VERSION ""

NS_ :

BS_:

BU_: FBD_HL IPB_App1 FBD_HM FBD_HR FBD_Miko FBD_MM FBD_Trunk FBD_VL FBD_VM FBD_VR Diagnosetool_CAN_FD_IPB_41

BO_ 552 LocalizationInitFBD_Miko: 48 FBD_Miko
 SG_ LocalizationInitFBD_Miko_IRKList : 0|8@1+ (1.0,0) [0|252] "" IPB_App1
 SG_ LocalizationInitFBD_Miko_ZoneEnt : 8|8@1+ (1.0,0) [0|252] "" IPB_App1
 SG_ LocalizationInitFBD_Miko_Ranging : 16|16@1+ (1.0,0) [0|65532] "" IPB_App1
 SG_ LocalizationInitFBD_Miko_TimeOfF : 32|16@1+ (15.65,0) [0|1000000] "ps" IPB_App1
 SG_ LocalizationInitFBD_Miko_RSSI_0 : 48|8@1+ (1.0,-90) [-90|90] "°" IPB_App1
 SG_ LocalizationInitFBD_Miko_Rangi_2 : 56|16@1+ (1.0,0) [0|65532] "" IPB_App1
 SG_ LocalizationInitFBD_Miko_TimeO_2 : 72|16@1+ (15.65,0) [0|1000000] "ps" IPB_App1
 SG_ LocalizationInitFBD_Miko_RSSI_1 : 88|8@1+ (1.0,-90) [-90|90] "°" IPB_App1
 SG_ LocalizationInitFBD_Miko_Rangi_3 : 96|16@1+ (1.0,0) [0|65532] "" IPB_App1
 SG_ LocalizationInitFBD_Miko_TimeO_3 : 112|16@1+ (15.65,0) [0|1000000] "ps" IPB_App1
 SG_ LocalizationInitFBD_Miko_RSSI_2 : 128|8@1+ (1.0,-90) [-90|90] "°" IPB_App1
 SG_ LocalizationInitFBD_Miko_Rangi_4 : 136|16@1+ (1.0,0) [0|65532] "" IPB_App1
 SG_ LocalizationInitFBD_Miko_TimeO_4 : 152|16@1+ (15.65,0) [0|1000000] "ps" IPB_App1
 SG_ LocalizationInitFBD_Miko_RSSI_3 : 168|8@1+ (1.0,-90) [-90|90] "°" IPB_App1
 SG_ LocalizationInitFBD_Miko_Rangi_5 : 176|16@1+ (1.0,0) [0|65532] "" IPB_App1
 SG_ LocalizationInitFBD_Miko_TimeO_5 : 192|16@1+ (15.65,0) [0|1000000] "ps" IPB_App1
 SG_ LocalizationInitFBD_Miko_RSSI_4 : 208|8@1+ (1.0,-90) [-90|90] "°" IPB_App1
 SG_ LocalizationInitFBD_Miko_Sign_00 : 216|8@1+ (1.0,0) [0|255] "" IPB_App1
 SG_ LocalizationInitFBD_Miko_Sign_01 : 224|8@1+ (1.0,0) [0|255] "" IPB_App1
 SG_ LocalizationInitFBD_Miko_Sign_02 : 232|8@1+ (1.0,0) [0|255] "" IPB_App1
 SG_ LocalizationInitFBD_Miko_Sign_03 : 240|8@1+ (1.0,0) [0|255] "" IPB_App1
 SG_ LocalizationInitFBD_Miko_Sign_04 : 248|8@1+ (1.0,0) [0|255] "" IPB_App1
 SG_ LocalizationInitFBD_Miko_Sign_05 : 256|8@1+ (1.0,0) [0|255] "" IPB_App1
 SG_ LocalizationInitFBD_Miko_Sign_06 : 264|8@1+ (1.0,0) [0|255] "" IPB_App1
 SG_ LocalizationInitFBD_Miko_Sign_07 : 272|8@1+ (1.0,0) [0|255] "" IPB_App1
 SG_ LocalizationInitFBD_Miko_Sign_08 : 280|8@1+ (1.0,0) [0|255] "" IPB_App1
 SG_ LocalizationInitFBD_Miko_Sign_09 : 288|8@1+ (1.0,0) [0|255] "" IPB_App1
 SG_ LocalizationInitFBD_Miko_Sign_10 : 296|8@1+ (1.0,0) [0|255] "" IPB_App1
 SG_ LocalizationInitFBD_Miko_Sign_11 : 304|8@1+ (1.0,0) [0|255] "" IPB_App1
 SG_ LocalizationInitFBD_Miko_Sign_12 : 312|8@1+ (1.0,0) [0|255] "" IPB_App1
 SG_ LocalizationInitFBD_Miko_Sign_13 : 320|8@1+ (1.0,0) [0|255] "" IPB_App1
 SG_ LocalizationInitFBD_Miko_Sign_14 : 328|8@1+ (1.0,0) [0|255] "" IPB_App1
 SG_ LocalizationInitFBD_Miko_Sign_15 : 336|8@1+ (1.0,0) [0|255] "" IPB_App1
 SG_ LocalizationInitFBD_Miko_Rangi_6 : 344|8@1+ (1.0,0) [0|255] "" IPB_App1
 SG_ LocalizationInitFBD_Miko_Rangi_7 : 352|8@1+ (1.0,0) [0|255] "" IPB_App1
 SG_ LocalizationInitFBD_Miko_Rangi_8 : 360|8@1+ (1.0,0) [0|255] "" IPB_App1
 SG_ LocalizationInitFBD_Miko_Rangi_9 : 368|8@1+ (1.0,0) [0|255] "" IPB_App1
 SG_ LocalizationInitFBD_Miko_Rang_10 : 376|8@1+ (1.0,0) [0|255] "" IPB_App1

BO_ 560 LocalizationInitFBD_MM: 48 FBD_MM
 SG_ LocalizationInitFBD_MM_IRKListIn : 0|8@1+ (1.0,0) [0|252] "" IPB_App1
 SG_ LocalizationInitFBD_MM_ZoneEntry : 8|8@1+ (1.0,0) [0|252] "" IPB_App1
 SG_ LocalizationInitFBD_MM_RangingBl : 16|16@1+ (1.0,0) [0|65532] "" IPB_App1
 SG_ LocalizationInitFBD_MM_TimeOfFli : 32|16@1+ (15.65,0) [0|1000000] "ps" IPB_App1
 SG_ LocalizationInitFBD_MM_RSSI_0 : 48|8@1+ (1.0,-90) [-90|90] "°" IPB_App1
 SG_ LocalizationInitFBD_MM_Ranging_2 : 56|16@1+ (1.0,0) [0|65532] "" IPB_App1
 SG_ LocalizationInitFBD_MM_TimeOfF_2 : 72|16@1+ (15.65,0) [0|1000000] "ps" IPB_App1
 SG_ LocalizationInitFBD_MM_RSSI_1 : 88|8@1+ (1.0,-90) [-90|90] "°" IPB_App1
 SG_ LocalizationInitFBD_MM_Ranging_3 : 96|16@1+ (1.0,0) [0|65532] "" IPB_App1
 SG_ LocalizationInitFBD_MM_TimeOfF_3 : 112|16@1+ (15.65,0) [0|1000000] "ps" IPB_App1
 SG_ LocalizationInitFBD_MM_RSSI_2 : 128|8@1+ (1.0,-90) [-90|90] "°" IPB_App1
 SG_ LocalizationInitFBD_MM_Ranging_4 : 136|16@1+ (1.0,0) [0|65532] "" IPB_App1
 SG_ LocalizationInitFBD_MM_TimeOfF_4 : 152|16@1+ (15.65,0) [0|1000000] "ps" IPB_App1
 SG_ LocalizationInitFBD_MM_RSSI_3 : 168|8@1+ (1.0,-90) [-90|90] "°" IPB_App1
 SG_ LocalizationInitFBD_MM_Ranging_5 : 176|16@1+ (1.0,0) [0|65532] "" IPB_App1
 SG_ LocalizationInitFBD_MM_TimeOfF_5 : 192|16@1+ (15.65,0) [0|1000000] "ps" IPB_App1
 SG_ LocalizationInitFBD_MM_RSSI_4 : 208|8@1+ (1.0,-90) [-90|90] "°" IPB_App1
 SG_ LocalizationInitFBD_MM_Sign_00 : 216|8@1+ (1.0,0) [0|255] "" IPB_App1
 SG_ LocalizationInitFBD_MM_Sign_01 : 224|8@1+ (1.0,0) [0|255] "" IPB_App1
 SG_ LocalizationInitFBD_MM_Sign_02 : 232|8@1+ (1.0,0) [0|255] "" IPB_App1
 SG_ LocalizationInitFBD_MM_Sign_03 : 240|8@1+ (1.0,0) [0|255] "" IPB_App1
 SG_ LocalizationInitFBD_MM_Sign_04 : 248|8@1+ (1.0,0) [0|255] "" IPB_App1
 SG_ LocalizationInitFBD_MM_Sign_05 : 256|8@1+ (1.0,0) [0|255] "" IPB_App1
 SG_ LocalizationInitFBD_MM_Sign_06 : 264|8@1+ (1.0,0) [0|255] "" IPB_App1
 SG_ LocalizationInitFBD_MM_Sign_07 : 272|8@1+ (1.0,0) [0|255] "" IPB_App1
 SG_ LocalizationInitFBD_MM_Sign_08 : 280|8@1+ (1.0,0) [0|255] "" IPB_App1
 SG_ LocalizationInitFBD_MM_Sign_09 : 288|8@1+ (1.0,0) [0|255] "" IPB_App1
 SG_ LocalizationInitFBD_MM_Sign_10 : 296|8@1+ (1.0,0) [0|255] "" IPB_App1
 SG_ LocalizationInitFBD_MM_Sign_11 : 304|8@1+ (1.0,0) [0|255] "" IPB_App1
 SG_ LocalizationInitFBD_MM_Sign_12 : 312|8@1+ (1.0,0) [0|255] "" IPB_App1
 SG_ LocalizationInitFBD_MM_Sign_13 : 320|8@1+ (1.0,0) [0|255] "" IPB_App1
 SG_ LocalizationInitFBD_MM_Sign_14 : 328|8@1+ (1.0,0) [0|255] "" IPB_App1
 SG_ LocalizationInitFBD_MM_Sign_15 : 336|8@1+ (1.0,0) [0|255] "" IPB_App1
 SG_ LocalizationInitFBD_MM_RangingRo : 344|8@1+ (1.0,0) [0|255] "" IPB_App1
 SG_ LocalizationInitFBD_MM_Ranging_6 : 352|8@1+ (1.0,0) [0|255] "" IPB_App1
 SG_ LocalizationInitFBD_MM_Ranging_7 : 360|8@1+ (1.0,0) [0|255] "" IPB_App1
 SG_ LocalizationInitFBD_MM_Ranging_8 : 368|8@1+ (1.0,0) [0|255] "" IPB_App1
 SG_ LocalizationInitFBD_MM_Ranging_9 : 376|8@1+ (1.0,0) [0|255] "" IPB_App1

BO_ 553 LocalizationInitFBD_Trunk: 48 FBD_Trunk
 SG_ LocalizationInitFBD_Trunk_IRKLis : 0|8@1+ (1.0,0) [0|252] "" IPB_App1
 SG_ LocalizationInitFBD_Trunk_ZoneEn : 8|8@1+ (1.0,0) [0|252] "" IPB_App1
 SG_ LocalizationInitFBD_Trunk_Rangin : 16|16@1+ (1.0,0) [0|65532] "" IPB_App1
 SG_ LocalizationInitFBD_Trunk_TimeOf : 32|16@1+ (15.65,0) [0|1000000] "ps" IPB_App1
 SG_ LocalizationInitFBD_Trunk_RSSI_0 : 48|8@1+ (1.0,-90) [-90|90] "°" IPB_App1
 SG_ LocalizationInitFBD_Trunk_Rang_2 : 56|16@1+ (1.0,0) [0|65532] "" IPB_App1
 SG_ LocalizationInitFBD_Trunk_Time_2 : 72|16@1+ (15.65,0) [0|1000000] "ps" IPB_App1
 SG_ LocalizationInitFBD_Trunk_RSSI_1 : 88|8@1+ (1.0,-90) [-90|90] "°" IPB_App1
 SG_ LocalizationInitFBD_Trunk_Rang_3 : 96|16@1+ (1.0,0) [0|65532] "" IPB_App1
 SG_ LocalizationInitFBD_Trunk_Time_3 : 112|16@1+ (15.65,0) [0|1000000] "ps" IPB_App1
 SG_ LocalizationInitFBD_Trunk_RSSI_2 : 128|8@1+ (1.0,-90) [-90|90] "°" IPB_App1
 SG_ LocalizationInitFBD_Trunk_Rang_4 : 136|16@1+ (1.0,0) [0|65532] "" IPB_App1
 SG_ LocalizationInitFBD_Trunk_Time_4 : 152|16@1+ (15.65,0) [0|1000000] "ps" IPB_App1
 SG_ LocalizationInitFBD_Trunk_RSSI_3 : 168|8@1+ (1.0,-90) [-90|90] "°" IPB_App1
 SG_ LocalizationInitFBD_Trunk_Rang_5 : 176|16@1+ (1.0,0) [0|65532] "" IPB_App1
 SG_ LocalizationInitFBD_Trunk_Time_5 : 192|16@1+ (15.65,0) [0|1000000] "ps" IPB_App1
 SG_ LocalizationInitFBD_Trunk_RSSI_4 : 208|8@1+ (1.0,-90) [-90|90] "°" IPB_App1
 SG_ LocalizationInitFBD_Trunk_Sign_0 : 216|8@1+ (1.0,0) [0|255] "" IPB_App1
 SG_ LocalizationInitFBD_Trunk_Sign_2 : 224|8@1+ (1.0,0) [0|255] "" IPB_App1
 SG_ LocalizationInitFBD_Trunk_Sign_3 : 232|8@1+ (1.0,0) [0|255] "" IPB_App1
 SG_ LocalizationInitFBD_Trunk_Sign_4 : 240|8@1+ (1.0,0) [0|255] "" IPB_App1
 SG_ LocalizationInitFBD_Trunk_Sign_5 : 248|8@1+ (1.0,0) [0|255] "" IPB_App1
 SG_ LocalizationInitFBD_Trunk_Sign_6 : 256|8@1+ (1.0,0) [0|255] "" IPB_App1
 SG_ LocalizationInitFBD_Trunk_Sign_7 : 264|8@1+ (1.0,0) [0|255] "" IPB_App1
 SG_ LocalizationInitFBD_Trunk_Sign_8 : 272|8@1+ (1.0,0) [0|255] "" IPB_App1
 SG_ LocalizationInitFBD_Trunk_Sign_9 : 280|8@1+ (1.0,0) [0|255] "" IPB_App1
 SG_ LocalizationInitFBD_Trunk_Sig_10 : 288|8@1+ (1.0,0) [0|255] "" IPB_App1
 SG_ LocalizationInitFBD_Trunk_Sign_1 : 296|8@1+ (1.0,0) [0|255] "" IPB_App1
 SG_ LocalizationInitFBD_Trunk_Sig_11 : 304|8@1+ (1.0,0) [0|255] "" IPB_App1
 SG_ LocalizationInitFBD_Trunk_Sig_12 : 312|8@1+ (1.0,0) [0|255] "" IPB_App1
 SG_ LocalizationInitFBD_Trunk_Sig_13 : 320|8@1+ (1.0,0) [0|255] "" IPB_App1
 SG_ LocalizationInitFBD_Trunk_Sig_14 : 328|8@1+ (1.0,0) [0|255] "" IPB_App1
 SG_ LocalizationInitFBD_Trunk_Sig_15 : 336|8@1+ (1.0,0) [0|255] "" IPB_App1
 SG_ LocalizationInitFBD_Trunk_Rang_6 : 344|8@1+ (1.0,0) [0|255] "" IPB_App1
 SG_ LocalizationInitFBD_Trunk_Rang_7 : 352|8@1+ (1.0,0) [0|255] "" IPB_App1
 SG_ LocalizationInitFBD_Trunk_Rang_8 : 360|8@1+ (1.0,0) [0|255] "" IPB_App1
 SG_ LocalizationInitFBD_Trunk_Rang_9 : 368|8@1+ (1.0,0) [0|255] "" IPB_App1
 SG_ LocalizationInitFBD_Trunk_Ran_10 : 376|8@1+ (1.0,0) [0|255] "" IPB_App1

BO_ 554 LocalizationInitFBD_VL: 48 FBD_VL
 SG_ LocalizationInitFBD_VL_IRKListIn : 0|8@1+ (1.0,0) [0|252] "" IPB_App1
 SG_ LocalizationInitFBD_VL_ZoneEntry : 8|8@1+ (1.0,0) [0|252] "" IPB_App1
 SG_ LocalizationInitFBD_VL_RangingBl : 16|16@1+ (1.0,0) [0|65532] "" IPB_App1
 SG_ LocalizationInitFBD_VL_TimeOfFli : 32|16@1+ (15.65,0) [0|1000000] "ps" IPB_App1
 SG_ LocalizationInitFBD_VL_RSSI_0 : 48|8@1+ (1.0,-90) [-90|90] "°" IPB_App1
 SG_ LocalizationInitFBD_VL_Ranging_2 : 56|16@1+ (1.0,0) [0|65532] "" IPB_App1
 SG_ LocalizationInitFBD_VL_TimeOfF_2 : 72|16@1+ (15.65,0) [0|1000000] "ps" IPB_App1
 SG_ LocalizationInitFBD_VL_RSSI_1 : 88|8@1+ (1.0,-90) [-90|90] "°" IPB_App1
 SG_ LocalizationInitFBD_VL_Ranging_3 : 96|16@1+ (1.0,0) [0|65532] "" IPB_App1
 SG_ LocalizationInitFBD_VL_TimeOfF_3 : 112|16@1+ (15.65,0) [0|1000000] "ps" IPB_App1
 SG_ LocalizationInitFBD_VL_RSSI_2 : 128|8@1+ (1.0,-90) [-90|90] "°" IPB_App1
 SG_ LocalizationInitFBD_VL_Ranging_4 : 136|16@1+ (1.0,0) [0|65532] "" IPB_App1
 SG_ LocalizationInitFBD_VL_TimeOfF_4 : 152|16@1+ (15.65,0) [0|1000000] "ps" IPB_App1
 SG_ LocalizationInitFBD_VL_RSSI_3 : 168|8@1+ (1.0,-90) [-90|90] "°" IPB_App1
 SG_ LocalizationInitFBD_VL_Ranging_5 : 176|16@1+ (1.0,0) [0|65532] "" IPB_App1
 SG_ LocalizationInitFBD_VL_TimeOfF_5 : 192|16@1+ (15.65,0) [0|1000000] "ps" IPB_App1
 SG_ LocalizationInitFBD_VL_RSSI_4 : 208|8@1+ (1.0,-90) [-90|90] "°" IPB_App1
 SG_ LocalizationInitFBD_VL_Sign_00 : 216|8@1+ (1.0,0) [0|255] "" IPB_App1
 SG_ LocalizationInitFBD_VL_Sign_01 : 224|8@1+ (1.0,0) [0|255] "" IPB_App1
 SG_ LocalizationInitFBD_VL_Sign_02 : 232|8@1+ (1.0,0) [0|255] "" IPB_App1
 SG_ LocalizationInitFBD_VL_Sign_03 : 240|8@1+ (1.0,0) [0|255] "" IPB_App1
 SG_ LocalizationInitFBD_VL_Sign_04 : 248|8@1+ (1.0,0) [0|255] "" IPB_App1
 SG_ LocalizationInitFBD_VL_Sign_05 : 256|8@1+ (1.0,0) [0|255] "" IPB_App1
 SG_ LocalizationInitFBD_VL_Sign_06 : 264|8@1+ (1.0,0) [0|255] "" IPB_App1
 SG_ LocalizationInitFBD_VL_Sign_07 : 272|8@1+ (1.0,0) [0|255] "" IPB_App1
 SG_ LocalizationInitFBD_VL_Sign_08 : 280|8@1+ (1.0,0) [0|255] "" IPB_App1
 SG_ LocalizationInitFBD_VL_Sign_09 : 288|8@1+ (1.0,0) [0|255] "" IPB_App1
 SG_ LocalizationInitFBD_VL_Sign_10 : 296|8@1+ (1.0,0) [0|255] "" IPB_App1
 SG_ LocalizationInitFBD_VL_Sign_11 : 304|8@1+ (1.0,0) [0|255] "" IPB_App1
 SG_ LocalizationInitFBD_VL_Sign_12 : 312|8@1+ (1.0,0) [0|255] "" IPB_App1
 SG_ LocalizationInitFBD_VL_Sign_13 : 320|8@1+ (1.0,0) [0|255] "" IPB_App1
 SG_ LocalizationInitFBD_VL_Sign_14 : 328|8@1+ (1.0,0) [0|255] "" IPB_App1
 SG_ LocalizationInitFBD_VL_Sign_15 : 336|8@1+ (1.0,0) [0|255] "" IPB_App1
 SG_ LocalizationInitFBD_VL_RangingRo : 344|8@1+ (1.0,0) [0|255] "" IPB_App1
 SG_ LocalizationInitFBD_VL_Ranging_6 : 352|8@1+ (1.0,0) [0|255] "" IPB_App1
 SG_ LocalizationInitFBD_VL_Ranging_7 : 360|8@1+ (1.0,0) [0|255] "" IPB_App1
 SG_ LocalizationInitFBD_VL_Ranging_8 : 368|8@1+ (1.0,0) [0|255] "" IPB_App1
 SG_ LocalizationInitFBD_VL_Ranging_9 : 376|8@1+ (1.0,0) [0|255] "" IPB_App1

BO_ 550 LocalizationInitFBD_VM: 48 FBD_VM
 SG_ LocalizationInitFBD_VM_IRKListIn : 0|8@1+ (1.0,0) [0|252] "" IPB_App1
 SG_ LocalizationInitFBD_VM_ZoneEntry : 8|8@1+ (1.0,0) [0|252] "" IPB_App1
 SG_ LocalizationInitFBD_VM_RangingBl : 16|16@1+ (1.0,0) [0|65532] "" IPB_App1
 SG_ LocalizationInitFBD_VM_TimeOfFli : 32|16@1+ (15.65,0) [0|1000000] "ps" IPB_App1
 SG_ LocalizationInitFBD_VM_RSSI_0 : 48|8@1+ (1.0,-90) [-90|90] "°" IPB_App1
 SG_ LocalizationInitFBD_VM_Ranging_2 : 56|16@1+ (1.0,0) [0|65532] "" IPB_App1
 SG_ LocalizationInitFBD_VM_TimeOfF_2 : 72|16@1+ (15.65,0) [0|1000000] "ps" IPB_App1
 SG_ LocalizationInitFBD_VM_RSSI_1 : 88|8@1+ (1.0,-90) [-90|90] "°" IPB_App1
 SG_ LocalizationInitFBD_VM_Ranging_3 : 96|16@1+ (1.0,0) [0|65532] "" IPB_App1
 SG_ LocalizationInitFBD_VM_TimeOfF_3 : 112|16@1+ (15.65,0) [0|1000000] "ps" IPB_App1
 SG_ LocalizationInitFBD_VM_RSSI_2 : 128|8@1+ (1.0,-90) [-90|90] "°" IPB_App1
 SG_ LocalizationInitFBD_VM_Ranging_4 : 136|16@1+ (1.0,0) [0|65532] "" IPB_App1
 SG_ LocalizationInitFBD_VM_TimeOfF_4 : 152|16@1+ (15.65,0) [0|1000000] "ps" IPB_App1
 SG_ LocalizationInitFBD_VM_RSSI_3 : 168|8@1+ (1.0,-90) [-90|90] "°" IPB_App1
 SG_ LocalizationInitFBD_VM_Ranging_5 : 176|16@1+ (1.0,0) [0|65532] "" IPB_App1
 SG_ LocalizationInitFBD_VM_TimeOfF_5 : 192|16@1+ (15.65,0) [0|1000000] "ps" IPB_App1
 SG_ LocalizationInitFBD_VM_RSSI_4 : 208|8@1+ (1.0,-90) [-90|90] "°" IPB_App1
 SG_ LocalizationInitFBD_VM_Sign_00 : 216|8@1+ (1.0,0) [0|255] "" IPB_App1
 SG_ LocalizationInitFBD_VM_Sign_01 : 224|8@1+ (1.0,0) [0|255] "" IPB_App1
 SG_ LocalizationInitFBD_VM_Sign_02 : 232|8@1+ (1.0,0) [0|255] "" IPB_App1
 SG_ LocalizationInitFBD_VM_Sign_03 : 240|8@1+ (1.0,0) [0|255] "" IPB_App1
 SG_ LocalizationInitFBD_VM_Sign_04 : 248|8@1+ (1.0,0) [0|255] "" IPB_App1
 SG_ LocalizationInitFBD_VM_Sign_05 : 256|8@1+ (1.0,0) [0|255] "" IPB_App1
 SG_ LocalizationInitFBD_VM_Sign_06 : 264|8@1+ (1.0,0) [0|255] "" IPB_App1
 SG_ LocalizationInitFBD_VM_Sign_07 : 272|8@1+ (1.0,0) [0|255] "" IPB_App1
 SG_ LocalizationInitFBD_VM_Sign_08 : 280|8@1+ (1.0,0) [0|255] "" IPB_App1
 SG_ LocalizationInitFBD_VM_Sign_09 : 288|8@1+ (1.0,0) [0|255] "" IPB_App1
 SG_ LocalizationInitFBD_VM_Sign_10 : 296|8@1+ (1.0,0) [0|255] "" IPB_App1
 SG_ LocalizationInitFBD_VM_Sign_11 : 304|8@1+ (1.0,0) [0|255] "" IPB_App1
 SG_ LocalizationInitFBD_VM_Sign_12 : 312|8@1+ (1.0,0) [0|255] "" IPB_App1
 SG_ LocalizationInitFBD_VM_Sign_13 : 320|8@1+ (1.0,0) [0|255] "" IPB_App1
 SG_ LocalizationInitFBD_VM_Sign_14 : 328|8@1+ (1.0,0) [0|255] "" IPB_App1
 SG_ LocalizationInitFBD_VM_Sign_15 : 336|8@1+ (1.0,0) [0|255] "" IPB_App1
 SG_ LocalizationInitFBD_VM_RangingRo : 344|8@1+ (1.0,0) [0|255] "" IPB_App1
 SG_ LocalizationInitFBD_VM_Ranging_6 : 352|8@1+ (1.0,0) [0|255] "" IPB_App1
 SG_ LocalizationInitFBD_VM_Ranging_7 : 360|8@1+ (1.0,0) [0|255] "" IPB_App1
 SG_ LocalizationInitFBD_VM_Ranging_8 : 368|8@1+ (1.0,0) [0|255] "" IPB_App1
 SG_ LocalizationInitFBD_VM_Ranging_9 : 376|8@1+ (1.0,0) [0|255] "" IPB_App1

BO_ 555 LocalizationInitFBD_VR: 48 FBD_VR
 SG_ LocalizationInitFBD_VR_IRKListIn : 0|8@1+ (1.0,0) [0|252] "" IPB_App1
 SG_ LocalizationInitFBD_VR_ZoneEntry : 8|8@1+ (1.0,0) [0|252] "" IPB_App1
 SG_ LocalizationInitFBD_VR_RangingBl : 16|16@1+ (1.0,0) [0|65532] "" IPB_App1
 SG_ LocalizationInitFBD_VR_TimeOfFli : 32|16@1+ (15.65,0) [0|1000000] "ps" IPB_App1
 SG_ LocalizationInitFBD_VR_RSSI_0 : 48|8@1+ (1.0,-90) [-90|90] "°" IPB_App1
 SG_ LocalizationInitFBD_VR_Ranging_2 : 56|16@1+ (1.0,0) [0|65532] "" IPB_App1
 SG_ LocalizationInitFBD_VR_TimeOfF_2 : 72|16@1+ (15.65,0) [0|1000000] "ps" IPB_App1
 SG_ LocalizationInitFBD_VR_RSSI_1 : 88|8@1+ (1.0,-90) [-90|90] "°" IPB_App1
 SG_ LocalizationInitFBD_VR_Ranging_3 : 96|16@1+ (1.0,0) [0|65532] "" IPB_App1
 SG_ LocalizationInitFBD_VR_TimeOfF_3 : 112|16@1+ (15.65,0) [0|1000000] "ps" IPB_App1
 SG_ LocalizationInitFBD_VR_RSSI_2 : 128|8@1+ (1.0,-90) [-90|90] "°" IPB_App1
 SG_ LocalizationInitFBD_VR_Ranging_4 : 136|16@1+ (1.0,0) [0|65532] "" IPB_App1
 SG_ LocalizationInitFBD_VR_TimeOfF_4 : 152|16@1+ (15.65,0) [0|1000000] "ps" IPB_App1
 SG_ LocalizationInitFBD_VR_RSSI_3 : 168|8@1+ (1.0,-90) [-90|90] "°" IPB_App1
 SG_ LocalizationInitFBD_VR_Ranging_5 : 176|16@1+ (1.0,0) [0|65532] "" IPB_App1
 SG_ LocalizationInitFBD_VR_TimeOfF_5 : 192|16@1+ (15.65,0) [0|1000000] "ps" IPB_App1
 SG_ LocalizationInitFBD_VR_RSSI_4 : 208|8@1+ (1.0,-90) [-90|90] "°" IPB_App1
 SG_ LocalizationInitFBD_VR_Sign_00 : 216|8@1+ (1.0,0) [0|255] "" IPB_App1
 SG_ LocalizationInitFBD_VR_Sign_01 : 224|8@1+ (1.0,0) [0|255] "" IPB_App1
 SG_ LocalizationInitFBD_VR_Sign_02 : 232|8@1+ (1.0,0) [0|255] "" IPB_App1
 SG_ LocalizationInitFBD_VR_Sign_03 : 240|8@1+ (1.0,0) [0|255] "" IPB_App1
 SG_ LocalizationInitFBD_VR_Sign_04 : 248|8@1+ (1.0,0) [0|255] "" IPB_App1
 SG_ LocalizationInitFBD_VR_Sign_05 : 256|8@1+ (1.0,0) [0|255] "" IPB_App1
 SG_ LocalizationInitFBD_VR_Sign_06 : 264|8@1+ (1.0,0) [0|255] "" IPB_App1
 SG_ LocalizationInitFBD_VR_Sign_07 : 272|8@1+ (1.0,0) [0|255] "" IPB_App1
 SG_ LocalizationInitFBD_VR_Sign_08 : 280|8@1+ (1.0,0) [0|255] "" IPB_App1
 SG_ LocalizationInitFBD_VR_Sign_09 : 288|8@1+ (1.0,0) [0|255] "" IPB_App1
 SG_ LocalizationInitFBD_VR_Sign_10 : 296|8@1+ (1.0,0) [0|255] "" IPB_App1
 SG_ LocalizationInitFBD_VR_Sign_11 : 304|8@1+ (1.0,0) [0|255] "" IPB_App1
 SG_ LocalizationInitFBD_VR_Sign_12 : 312|8@1+ (1.0,0) [0|255] "" IPB_App1
 SG_ LocalizationInitFBD_VR_Sign_13 : 320|8@1+ (1.0,0) [0|255] "" IPB_App1
 SG_ LocalizationInitFBD_VR_Sign_14 : 328|8@1+ (1.0,0) [0|255] "" IPB_App1
 SG_ LocalizationInitFBD_VR_Sign_15 : 336|8@1+ (1.0,0) [0|255] "" IPB_App1
 SG_ LocalizationInitFBD_VR_RangingRo : 344|8@1+ (1.0,0) [0|255] "" IPB_App1
 SG_ LocalizationInitFBD_VR_Ranging_6 : 352|8@1+ (1.0,0) [0|255] "" IPB_App1
 SG_ LocalizationInitFBD_VR_Ranging_7 : 360|8@1+ (1.0,0) [0|255] "" IPB_App1
 SG_ LocalizationInitFBD_VR_Ranging_8 : 368|8@1+ (1.0,0) [0|255] "" IPB_App1
 SG_ LocalizationInitFBD_VR_Ranging_9 : 376|8@1+ (1.0,0) [0|255] "" IPB_App1

BO_ 406 LocalizationInitRequest: 20 IPB_App1
 SG_ LocalizationInitRequest_Address : 0|16@1+ (1,0) [0|0] "" FBD_HL,FBD_HM,FBD_HR,FBD_MM,FBD_Miko,FBD_Trunk,FBD_VL,FBD_VM,FBD_VR
 SG_ LocalizationInitRequest_SessionI : 16|8@1+ (1.0,0) [0|252] "" FBD_HL,FBD_HM,FBD_HR,FBD_MM,FBD_Miko,FBD_Trunk,FBD_VL,FBD_VM,FBD_VR
 SG_ LocalizationInitRequest_IRKListI : 24|8@1+ (1.0,0) [0|252] "" FBD_HL,FBD_HM,FBD_HR,FBD_MM,FBD_Miko,FBD_Trunk,FBD_VL,FBD_VM,FBD_VR
 SG_ LocalizationInitRequest_Auth00 : 32|8@1+ (1.0,0) [0|255] "" FBD_HL,FBD_HM,FBD_HR,FBD_MM,FBD_Miko,FBD_Trunk,FBD_VL,FBD_VM,FBD_VR
 SG_ LocalizationInitRequest_Auth01 : 40|8@1+ (1.0,0) [0|255] "" FBD_HL,FBD_HM,FBD_HR,FBD_MM,FBD_Miko,FBD_Trunk,FBD_VL,FBD_VM,FBD_VR
 SG_ LocalizationInitRequest_Auth02 : 48|8@1+ (1.0,0) [0|255] "" FBD_HL,FBD_HM,FBD_HR,FBD_MM,FBD_Miko,FBD_Trunk,FBD_VL,FBD_VM,FBD_VR
 SG_ LocalizationInitRequest_Auth03 : 56|8@1+ (1.0,0) [0|255] "" FBD_HL,FBD_HM,FBD_HR,FBD_MM,FBD_Miko,FBD_Trunk,FBD_VL,FBD_VM,FBD_VR
 SG_ LocalizationInitRequest_Auth04 : 64|8@1+ (1.0,0) [0|255] "" FBD_HL,FBD_HM,FBD_HR,FBD_MM,FBD_Miko,FBD_Trunk,FBD_VL,FBD_VM,FBD_VR
 SG_ LocalizationInitRequest_Auth05 : 72|8@1+ (1.0,0) [0|255] "" FBD_HL,FBD_HM,FBD_HR,FBD_MM,FBD_Miko,FBD_Trunk,FBD_VL,FBD_VM,FBD_VR
 SG_ LocalizationInitRequest_Auth06 : 80|8@1+ (1.0,0) [0|255] "" FBD_HL,FBD_HM,FBD_HR,FBD_MM,FBD_Miko,FBD_Trunk,FBD_VL,FBD_VM,FBD_VR
 SG_ LocalizationInitRequest_Auth07 : 88|8@1+ (1.0,0) [0|255] "" FBD_HL,FBD_HM,FBD_HR,FBD_MM,FBD_Miko,FBD_Trunk,FBD_VL,FBD_VM,FBD_VR
 SG_ LocalizationInitRequest_Auth08 : 96|8@1+ (1.0,0) [0|255] "" FBD_HL,FBD_HM,FBD_HR,FBD_MM,FBD_Miko,FBD_Trunk,FBD_VL,FBD_VM,FBD_VR
 SG_ LocalizationInitRequest_Auth09 : 104|8@1+ (1.0,0) [0|255] "" FBD_HL,FBD_HM,FBD_HR,FBD_MM,FBD_Miko,FBD_Trunk,FBD_VL,FBD_VM,FBD_VR
 SG_ LocalizationInitRequest_Auth10 : 112|8@1+ (1.0,0) [0|255] "" FBD_HL,FBD_HM,FBD_HR,FBD_MM,FBD_Miko,FBD_Trunk,FBD_VL,FBD_VM,FBD_VR
 SG_ LocalizationInitRequest_Auth11 : 120|8@1+ (1.0,0) [0|255] "" FBD_HL,FBD_HM,FBD_HR,FBD_MM,FBD_Miko,FBD_Trunk,FBD_VL,FBD_VM,FBD_VR
 SG_ LocalizationInitRequest_Auth12 : 128|8@1+ (1.0,0) [0|255] "" FBD_HL,FBD_HM,FBD_HR,FBD_MM,FBD_Miko,FBD_Trunk,FBD_VL,FBD_VM,FBD_VR
 SG_ LocalizationInitRequest_Auth13 : 136|8@1+ (1.0,0) [0|255] "" FBD_HL,FBD_HM,FBD_HR,FBD_MM,FBD_Miko,FBD_Trunk,FBD_VL,FBD_VM,FBD_VR
 SG_ LocalizationInitRequest_Auth14 : 144|8@1+ (1.0,0) [0|255] "" FBD_HL,FBD_HM,FBD_HR,FBD_MM,FBD_Miko,FBD_Trunk,FBD_VL,FBD_VM,FBD_VR
 SG_ LocalizationInitRequest_Auth15 : 152|8@1+ (1.0,0) [0|255] "" FBD_HL,FBD_HM,FBD_HR,FBD_MM,FBD_Miko,FBD_Trunk,FBD_VL,FBD_VM,FBD_VR

BO_ 999 LocalizationResult_IPB: 32 IPB_App1
 SG_ LocalizationResult_IPB_Byte00 : 0|8@1+ (1.0,0) [0|252] "" Diagnosetool_CAN_FD_IPB_41
 SG_ LocalizationResult_IPB_Byte01 : 8|8@1+ (1.0,0) [0|252] "" Diagnosetool_CAN_FD_IPB_41
 SG_ LocalizationResult_IPB_Byte02 : 16|8@1+ (1.0,0) [0|252] "" Diagnosetool_CAN_FD_IPB_41
 SG_ LocalizationResult_IPB_Byte03 : 24|8@1+ (1.0,0) [0|252] "" Diagnosetool_CAN_FD_IPB_41
 SG_ LocalizationResult_IPB_Byte04 : 32|8@1+ (1.0,0) [0|252] "" Diagnosetool_CAN_FD_IPB_41
 SG_ LocalizationResult_IPB_Byte05 : 40|8@1+ (1.0,0) [0|252] "" Diagnosetool_CAN_FD_IPB_41
 SG_ LocalizationResult_IPB_Byte06 : 48|8@1+ (1.0,0) [0|252] "" Diagnosetool_CAN_FD_IPB_41
 SG_ LocalizationResult_IPB_Byte07 : 56|8@1+ (1.0,0) [0|252] "" Diagnosetool_CAN_FD_IPB_41
 SG_ LocalizationResult_IPB_Byte08 : 64|8@1+ (1.0,0) [0|252] "" Diagnosetool_CAN_FD_IPB_41
 SG_ LocalizationResult_IPB_Byte09 : 72|8@1+ (1.0,0) [0|252] "" Diagnosetool_CAN_FD_IPB_41
 SG_ LocalizationResult_IPB_Byte10 : 80|8@1+ (1.0,0) [0|252] "" Diagnosetool_CAN_FD_IPB_41
 SG_ LocalizationResult_IPB_Byte11 : 88|8@1+ (1.0,0) [0|252] "" Diagnosetool_CAN_FD_IPB_41
 SG_ LocalizationResult_IPB_Byte12 : 96|8@1+ (1.0,0) [0|252] "" Diagnosetool_CAN_FD_IPB_41
 SG_ LocalizationResult_IPB_Byte13 : 104|8@1+ (1.0,0) [0|252] "" Diagnosetool_CAN_FD_IPB_41
 SG_ LocalizationResult_IPB_Byte14 : 112|8@1+ (1.0,0) [0|252] "" Diagnosetool_CAN_FD_IPB_41
 SG_ LocalizationResult_IPB_Byte15 : 120|8@1+ (1.0,0) [0|252] "" Diagnosetool_CAN_FD_IPB_41
 SG_ LocalizationResult_IPB_Byte16 : 128|8@1+ (1.0,0) [0|252] "" Diagnosetool_CAN_FD_IPB_41
 SG_ LocalizationResult_IPB_Byte17 : 136|8@1+ (1.0,0) [0|252] "" Diagnosetool_CAN_FD_IPB_41
 SG_ LocalizationResult_IPB_Byte18 : 144|8@1+ (1.0,0) [0|252] "" Diagnosetool_CAN_FD_IPB_41
 SG_ LocalizationResult_IPB_Byte19 : 152|8@1+ (1.0,0) [0|252] "" Diagnosetool_CAN_FD_IPB_41
 SG_ LocalizationResult_IPB_Byte20 : 160|8@1+ (1.0,0) [0|252] "" Diagnosetool_CAN_FD_IPB_41
 SG_ LocalizationResult_IPB_Byte21 : 168|8@1+ (1.0,0) [0|252] "" Diagnosetool_CAN_FD_IPB_41
 SG_ LocalizationResult_IPB_Byte22 : 176|8@1+ (1.0,0) [0|252] "" Diagnosetool_CAN_FD_IPB_41
 SG_ LocalizationResult_IPB_Byte23 : 184|8@1+ (1.0,0) [0|252] "" Diagnosetool_CAN_FD_IPB_41
 SG_ LocalizationResult_IPB_Byte24 : 192|8@1+ (1.0,0) [0|252] "" Diagnosetool_CAN_FD_IPB_41
 SG_ LocalizationResult_IPB_Byte25 : 200|8@1+ (1.0,0) [0|252] "" Diagnosetool_CAN_FD_IPB_41
 SG_ LocalizationResult_IPB_Byte26 : 208|8@1+ (1.0,0) [0|252] "" Diagnosetool_CAN_FD_IPB_41
 SG_ LocalizationResult_IPB_Byte27 : 216|8@1+ (1.0,0) [0|252] "" Diagnosetool_CAN_FD_IPB_41
 SG_ LocalizationResult_IPB_Byte28 : 224|8@1+ (1.0,0) [0|252] "" Diagnosetool_CAN_FD_IPB_41
 SG_ LocalizationResult_IPB_Byte29 : 232|8@1+ (1.0,0) [0|252] "" Diagnosetool_CAN_FD_IPB_41
 SG_ LocalizationResult_IPB_Byte30 : 240|8@1+ (1.0,0) [0|252] "" Diagnosetool_CAN_FD_IPB_41
 SG_ LocalizationResult_IPB_Byte31 : 248|8@1+ (1.0,0) [0|252] "" Diagnosetool_CAN_FD_IPB_41

BO_ 998 MyWayTracking_IPB: 32 IPB_App1
 SG_ MyWayTracking_IPB_SessionIDShort : 0|8@1+ (1.0,0) [0|252] "" Diagnosetool_CAN_FD_IPB_41
 SG_ MyWayTracking_IPB_IRKListIndex : 8|8@1+ (1.0,0) [0|252] "" Diagnosetool_CAN_FD_IPB_41
 SG_ MyWayTracking_IPB_TrackingStatus : 16|8@1+ (1.0,0) [0|252] "" Diagnosetool_CAN_FD_IPB_41
 SG_ MyWayTracking_IPB_Classification : 24|8@1+ (1.0,0) [0|252] "" Diagnosetool_CAN_FD_IPB_41
 SG_ MyWayTracking_IPB_Intent : 32|8@1+ (1.0,0) [0|252] "" Diagnosetool_CAN_FD_IPB_41
 SG_ MyWayTracking_IPB_TimeRemaining : 40|8@1+ (1.0,0) [0|252] "" Diagnosetool_CAN_FD_IPB_41
 SG_ MyWayTracking_IPB_Target : 48|8@1+ (1.0,0) [0|252] "" Diagnosetool_CAN_FD_IPB_41
 SG_ MyWayTracking_IPB_Parameter00 : 56|8@1+ (1.0,0) [0|252] "" Diagnosetool_CAN_FD_IPB_41
 SG_ MyWayTracking_IPB_Parameter01 : 64|8@1+ (1.0,0) [0|252] "" Diagnosetool_CAN_FD_IPB_41
 SG_ MyWayTracking_IPB_Parameter02 : 72|8@1+ (1.0,0) [0|252] "" Diagnosetool_CAN_FD_IPB_41
 SG_ MyWayTracking_IPB_Parameter03 : 80|8@1+ (1.0,0) [0|252] "" Diagnosetool_CAN_FD_IPB_41
 SG_ MyWayTracking_IPB_Parameter04 : 88|8@1+ (1.0,0) [0|252] "" Diagnosetool_CAN_FD_IPB_41
 SG_ MyWayTracking_IPB_Parameter05 : 96|8@1+ (1.0,0) [0|252] "" Diagnosetool_CAN_FD_IPB_41
 SG_ MyWayTracking_IPB_Parameter06 : 104|8@1+ (1.0,0) [0|252] "" Diagnosetool_CAN_FD_IPB_41
 SG_ MyWayTracking_IPB_Parameter07 : 112|8@1+ (1.0,0) [0|252] "" Diagnosetool_CAN_FD_IPB_41
 SG_ MyWayTracking_IPB_Parameter08 : 120|8@1+ (1.0,0) [0|252] "" Diagnosetool_CAN_FD_IPB_41
 SG_ MyWayTracking_IPB_Parameter09 : 128|8@1+ (1.0,0) [0|252] "" Diagnosetool_CAN_FD_IPB_41
 SG_ MyWayTracking_IPB_Parameter10 : 136|8@1+ (1.0,0) [0|252] "" Diagnosetool_CAN_FD_IPB_41
 SG_ MyWayTracking_IPB_Parameter11 : 144|8@1+ (1.0,0) [0|252] "" Diagnosetool_CAN_FD_IPB_41
 SG_ MyWayTracking_IPB_Parameter12 : 152|8@1+ (1.0,0) [0|252] "" Diagnosetool_CAN_FD_IPB_41
 SG_ MyWayTracking_IPB_Parameter13 : 160|8@1+ (1.0,0) [0|252] "" Diagnosetool_CAN_FD_IPB_41
 SG_ MyWayTracking_IPB_Parameter14 : 168|8@1+ (1.0,0) [0|252] "" Diagnosetool_CAN_FD_IPB_41
 SG_ MyWayTracking_IPB_Parameter15 : 176|8@1+ (1.0,0) [0|252] "" Diagnosetool_CAN_FD_IPB_41
 SG_ MyWayTracking_IPB_Parameter16 : 184|8@1+ (1.0,0) [0|252] "" Diagnosetool_CAN_FD_IPB_41
 SG_ MyWayTracking_IPB_Parameter17 : 192|8@1+ (1.0,0) [0|252] "" Diagnosetool_CAN_FD_IPB_41
 SG_ MyWayTracking_IPB_Parameter18 : 200|8@1+ (1.0,0) [0|252] "" Diagnosetool_CAN_FD_IPB_41
 SG_ MyWayTracking_IPB_Parameter19 : 208|8@1+ (1.0,0) [0|252] "" Diagnosetool_CAN_FD_IPB_41
 SG_ MyWayTracking_IPB_Parameter20 : 216|8@1+ (1.0,0) [0|252] "" Diagnosetool_CAN_FD_IPB_41
 SG_ MyWayTracking_IPB_Parameter21 : 224|8@1+ (1.0,0) [0|252] "" Diagnosetool_CAN_FD_IPB_41
 SG_ MyWayTracking_IPB_Parameter22 : 232|8@1+ (1.0,0) [0|252] "" Diagnosetool_CAN_FD_IPB_41
 SG_ MyWayTracking_IPB_Parameter23 : 240|8@1+ (1.0,0) [0|252] "" Diagnosetool_CAN_FD_IPB_41
 SG_ MyWayTracking_IPB_Parameter24 : 248|8@1+ (1.0,0) [0|252] "" Diagnosetool_CAN_FD_IPB_41

BO_ 606 RequestBindingStatusFBD: 8 IPB_App1
 SG_ RequestBindingStatusFBD_Address : 0|16@1+ (1,0) [0|0] "" FBD_HL,FBD_HM,FBD_HR,FBD_MM,FBD_Miko,FBD_Trunk,FBD_VL,FBD_VM,FBD_VR
 SG_ RequestBindingStatusFBD_RequestS : 16|8@1+ (1.0,0) [0|252] "" FBD_HL,FBD_HM,FBD_HR,FBD_MM,FBD_Miko,FBD_Trunk,FBD_VL,FBD_VM,FBD_VR

BO_ 384 RequestBLECSSession: 48 IPB_App1
 SG_ RequestBLECSSession_Address : 0|16@1+ (1,0) [0|0] "" FBD_HL,FBD_HM,FBD_HR,FBD_MM,FBD_Miko,FBD_Trunk,FBD_VL,FBD_VM,FBD_VR
 SG_ RequestBLECSSession_ID : 16|8@1+ (1.0,0) [0|252] "" FBD_HL,FBD_HM,FBD_HR,FBD_MM,FBD_Miko,FBD_Trunk,FBD_VL,FBD_VM,FBD_VR
 SG_ RequestBLECSSession_IRKListID : 24|8@1+ (1.0,0) [0|252] "" FBD_HL,FBD_HM,FBD_HR,FBD_MM,FBD_Miko,FBD_Trunk,FBD_VL,FBD_VM,FBD_VR
 SG_ RequestBLECSSession_DeviceGroup : 32|8@1+ (1.0,0) [0|252] "" FBD_HL,FBD_HM,FBD_HR,FBD_MM,FBD_Miko,FBD_Trunk,FBD_VL,FBD_VM,FBD_VR
 SG_ RequestBLECSSession_MainModeType : 40|8@1+ (1,0) [0|0] "" FBD_HL,FBD_HM,FBD_HR,FBD_MM,FBD_Miko,FBD_Trunk,FBD_VL,FBD_VM,FBD_VR
 SG_ RequestBLECSSession_SubModeType : 48|8@1+ (1,0) [0|0] "" FBD_HL,FBD_HM,FBD_HR,FBD_MM,FBD_Miko,FBD_Trunk,FBD_VL,FBD_VM,FBD_VR
 SG_ RequestBLECSSession_MainModeRepe : 56|8@1+ (1.0,0) [0|252] "" FBD_HL,FBD_HM,FBD_HR,FBD_MM,FBD_Miko,FBD_Trunk,FBD_VL,FBD_VM,FBD_VR
 SG_ RequestBLECSSession_Mode0Steps : 64|8@1+ (1.0,0) [0|252] "" FBD_HL,FBD_HM,FBD_HR,FBD_MM,FBD_Miko,FBD_Trunk,FBD_VL,FBD_VM,FBD_VR
 SG_ RequestBLECSSession_RTTType : 72|8@1+ (1,0) [0|0] "" FBD_HL,FBD_HM,FBD_HR,FBD_MM,FBD_Miko,FBD_Trunk,FBD_VL,FBD_VM,FBD_VR
 SG_ RequestBLECSSession_CSSyncPHY : 80|8@1+ (1,0) [0|0] "" FBD_HL,FBD_HM,FBD_HR,FBD_MM,FBD_Miko,FBD_Trunk,FBD_VL,FBD_VM,FBD_VR
 SG_ RequestBLECSSession_ChannelMap00 : 88|64@1+ (1,0) [0|0] "" FBD_HL,FBD_HM,FBD_HR,FBD_MM,FBD_Miko,FBD_Trunk,FBD_VL,FBD_VM,FBD_VR
 SG_ RequestBLECSSession_ChannelMap60 : 152|24@1+ (1,0) [0|0] "" FBD_HL,FBD_HM,FBD_HR,FBD_MM,FBD_Miko,FBD_Trunk,FBD_VL,FBD_VM,FBD_VR
 SG_ RequestBLECSSession_MaxProcedure : 176|16@1+ (0.625,0) [0|40900] "ms" FBD_HL,FBD_HM,FBD_HR,FBD_MM,FBD_Miko,FBD_Trunk,FBD_VL,FBD_VM,FBD_VR
 SG_ RequestBLECSSession_MinProcedure : 192|16@1+ (0.625,0) [0|40900] "ms" FBD_HL,FBD_HM,FBD_HR,FBD_MM,FBD_Miko,FBD_Trunk,FBD_VL,FBD_VM,FBD_VR
 SG_ RequestBLECSSession_MaxProcedu_2 : 208|16@1+ (0.625,0) [0|40900] "ms" FBD_HL,FBD_HM,FBD_HR,FBD_MM,FBD_Miko,FBD_Trunk,FBD_VL,FBD_VM,FBD_VR
 SG_ RequestBLECSSession_MaxProcedu_3 : 224|16@1+ (1.0,0) [0|65532] "" FBD_HL,FBD_HM,FBD_HR,FBD_MM,FBD_Miko,FBD_Trunk,FBD_VL,FBD_VM,FBD_VR
 SG_ RequestBLECSSession_ToneAntennaC : 240|8@1+ (1,0) [0|0] "" FBD_HL,FBD_HM,FBD_HR,FBD_MM,FBD_Miko,FBD_Trunk,FBD_VL,FBD_VM,FBD_VR
 SG_ RequestBLECSSession_BusCycleTime : 248|16@1+ (1.0,0) [0|65532] "ms" FBD_HL,FBD_HM,FBD_HR,FBD_MM,FBD_Miko,FBD_Trunk,FBD_VL,FBD_VM,FBD_VR

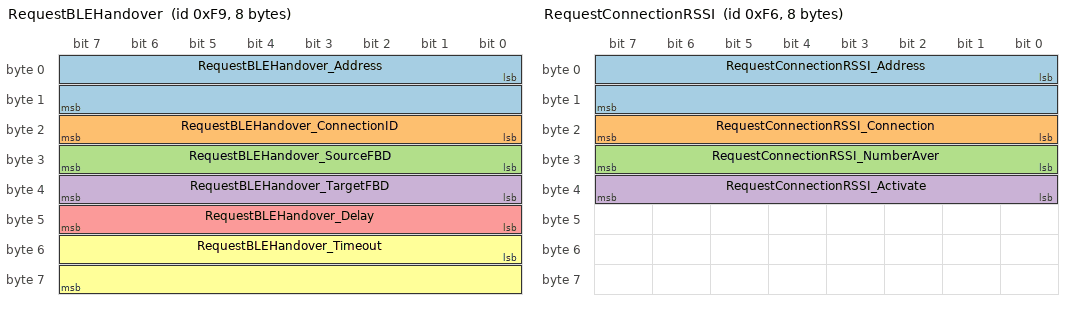
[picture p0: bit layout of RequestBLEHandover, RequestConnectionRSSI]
BO_ 249 RequestBLEHandover: 8 IPB_App1
 SG_ RequestBLEHandover_Address : 0|16@1+ (1,0) [0|0] "" FBD_HL,FBD_HM,FBD_HR,FBD_MM,FBD_Miko,FBD_Trunk,FBD_VL,FBD_VM,FBD_VR
 SG_ RequestBLEHandover_ConnectionID : 16|8@1+ (1.0,0) [0|252] "" FBD_HL,FBD_HM,FBD_HR,FBD_MM,FBD_Miko,FBD_Trunk,FBD_VL,FBD_VM,FBD_VR
 SG_ RequestBLEHandover_SourceFBD : 24|8@1+ (1,0) [0|0] "" FBD_HL,FBD_HM,FBD_HR,FBD_MM,FBD_Miko,FBD_Trunk,FBD_VL,FBD_VM,FBD_VR
 SG_ RequestBLEHandover_TargetFBD : 32|8@1+ (1,0) [0|0] "" FBD_HL,FBD_HM,FBD_HR,FBD_MM,FBD_Miko,FBD_Trunk,FBD_VL,FBD_VM,FBD_VR
 SG_ RequestBLEHandover_Delay : 40|8@1+ (1.0,0) [0|252] "ms" FBD_HL,FBD_HM,FBD_HR,FBD_MM,FBD_Miko,FBD_Trunk,FBD_VL,FBD_VM,FBD_VR
 SG_ RequestBLEHandover_Timeout : 48|16@1+ (1.0,0) [0|65532] "ms" FBD_HL,FBD_HM,FBD_HR,FBD_MM,FBD_Miko,FBD_Trunk,FBD_VL,FBD_VM,FBD_VR

BO_ 203 RequestBLESettings: 8 IPB_App1
 SG_ RequestBLESettings_Address : 0|16@1+ (1,0) [0|0] "" FBD_HL,FBD_HM,FBD_HR,FBD_MM,FBD_Miko,FBD_Trunk,FBD_VL,FBD_VM,FBD_VR
 SG_ RequestBLESettings_RequestSettin : 16|8@1+ (1.0,0) [0|252] "" FBD_HL,FBD_HM,FBD_HR,FBD_MM,FBD_Miko,FBD_Trunk,FBD_VL,FBD_VM,FBD_VR

BO_ 601 RequestConfigurationStatusFBD: 8 IPB_App1
 SG_ RequestConfigurationStatusFBD_Ad : 0|16@1+ (1,0) [0|0] "" FBD_HL,FBD_HM,FBD_HR,FBD_MM,FBD_Miko,FBD_Trunk,FBD_VL,FBD_VM,FBD_VR
 SG_ RequestConfigurationStatusFBD_Re : 16|8@1+ (1.0,0) [0|252] "" FBD_HL,FBD_HM,FBD_HR,FBD_MM,FBD_Miko,FBD_Trunk,FBD_VL,FBD_VM,FBD_VR

BO_ 246 RequestConnectionRSSI: 8 IPB_App1
 SG_ RequestConnectionRSSI_Address : 0|16@1+ (1,0) [0|0] "" FBD_HL,FBD_HM,FBD_HR,FBD_MM,FBD_Miko,FBD_Trunk,FBD_VL,FBD_VM,FBD_VR
 SG_ RequestConnectionRSSI_Connection : 16|8@1+ (1.0,0) [0|252] "" FBD_HL,FBD_HM,FBD_HR,FBD_MM,FBD_Miko,FBD_Trunk,FBD_VL,FBD_VM,FBD_VR
 SG_ RequestConnectionRSSI_NumberAver : 24|8@1+ (1.0,0) [0|252] "" FBD_HL,FBD_HM,FBD_HR,FBD_MM,FBD_Miko,FBD_Trunk,FBD_VL,FBD_VM,FBD_VR
 SG_ RequestConnectionRSSI_Activate : 32|8@1+ (1,0) [0|0] "" FBD_HL,FBD_HM,FBD_HR,FBD_MM,FBD_Miko,FBD_Trunk,FBD_VL,FBD_VM,FBD_VR

BO_ 602 RequestCoordinates: 8 IPB_App1
 SG_ RequestCoordinates_Address : 0|16@1+ (1,0) [0|0] "" FBD_HL,FBD_HM,FBD_HR,FBD_MM,FBD_Miko,FBD_Trunk,FBD_VL,FBD_VM,FBD_VR
 SG_ RequestCoordinates_RequestData : 16|8@1+ (1.0,0) [0|252] "" FBD_HL,FBD_HM,FBD_HR,FBD_MM,FBD_Miko,FBD_Trunk,FBD_VL,FBD_VM,FBD_VR

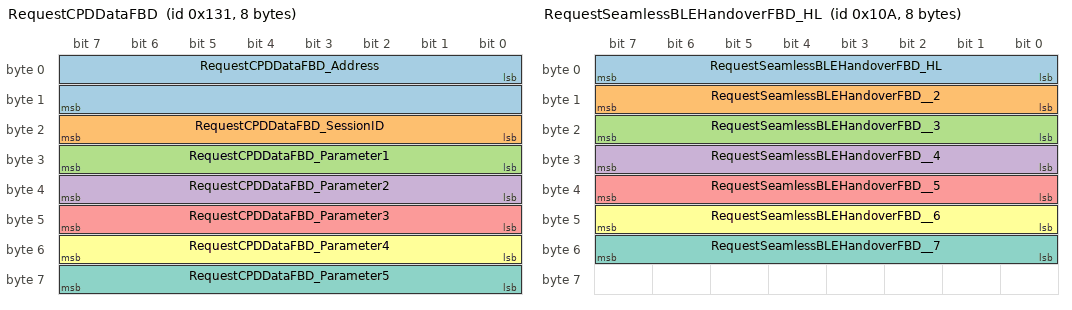
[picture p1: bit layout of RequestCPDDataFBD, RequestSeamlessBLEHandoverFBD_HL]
BO_ 305 RequestCPDDataFBD: 8 IPB_App1
 SG_ RequestCPDDataFBD_Address : 0|16@1+ (1,0) [0|0] "" FBD_HL,FBD_HM,FBD_HR,FBD_MM,FBD_Miko,FBD_Trunk,FBD_VL,FBD_VM,FBD_VR
 SG_ RequestCPDDataFBD_SessionID : 16|8@1+ (1.0,0) [0|252] "" FBD_HL,FBD_HM,FBD_HR,FBD_MM,FBD_Miko,FBD_Trunk,FBD_VL,FBD_VM,FBD_VR
 SG_ RequestCPDDataFBD_Parameter1 : 24|8@1+ (1.0,0) [0|252] "" FBD_HL,FBD_HM,FBD_HR,FBD_MM,FBD_Miko,FBD_Trunk,FBD_VL,FBD_VM,FBD_VR
 SG_ RequestCPDDataFBD_Parameter2 : 32|8@1+ (1.0,0) [0|252] "" FBD_HL,FBD_HM,FBD_HR,FBD_MM,FBD_Miko,FBD_Trunk,FBD_VL,FBD_VM,FBD_VR
 SG_ RequestCPDDataFBD_Parameter3 : 40|8@1+ (1.0,0) [0|252] "" FBD_HL,FBD_HM,FBD_HR,FBD_MM,FBD_Miko,FBD_Trunk,FBD_VL,FBD_VM,FBD_VR
 SG_ RequestCPDDataFBD_Parameter4 : 48|8@1+ (1.0,0) [0|252] "" FBD_HL,FBD_HM,FBD_HR,FBD_MM,FBD_Miko,FBD_Trunk,FBD_VL,FBD_VM,FBD_VR
 SG_ RequestCPDDataFBD_Parameter5 : 56|8@1+ (1.0,0) [0|252] "" FBD_HL,FBD_HM,FBD_HR,FBD_MM,FBD_Miko,FBD_Trunk,FBD_VL,FBD_VM,FBD_VR

BO_ 405 RequestRangingSessionSign: 12 IPB_App1
 SG_ RequestRangingSessionSign_Addres : 0|16@1+ (1,0) [0|0] "" FBD_HL,FBD_HM,FBD_HR,FBD_MM,FBD_Miko,FBD_Trunk,FBD_VL,FBD_VM,FBD_VR
 SG_ RequestRangingSessionSign_Functi : 16|8@1+ (1.0,0) [0|252] "" FBD_HL,FBD_HM,FBD_HR,FBD_MM,FBD_Miko,FBD_Trunk,FBD_VL,FBD_VM,FBD_VR
 SG_ RequestRangingSessionSign_IRKLis : 24|8@1+ (1.0,0) [0|252] "" FBD_HL,FBD_HM,FBD_HR,FBD_MM,FBD_Miko,FBD_Trunk,FBD_VL,FBD_VM,FBD_VR
 SG_ RequestRangingSessionSign_STSInd : 32|32@1+ (1.0,0) [0|4294967292] "" FBD_HL,FBD_HM,FBD_HR,FBD_MM,FBD_Miko,FBD_Trunk,FBD_VL,FBD_VM,FBD_VR
 SG_ RequestRangingSessionSign_Nonce : 64|32@1+ (1.0,0) [0|4294967294] "" FBD_HL,FBD_HM,FBD_HR,FBD_MM,FBD_Miko,FBD_Trunk,FBD_VL,FBD_VM,FBD_VR

BO_ 266 RequestSeamlessBLEHandoverFBD_HL: 8 FBD_HL
 SG_ RequestSeamlessBLEHandoverFBD_HL : 0|8@1+ (1.0,0) [0|252] "" FBD_HM,FBD_HR,FBD_MM,FBD_Miko,FBD_Trunk,FBD_VL,FBD_VM,FBD_VR
 SG_ RequestSeamlessBLEHandoverFBD__2 : 8|8@1+ (1,0) [0|0] "" FBD_HM,FBD_HR,FBD_MM,FBD_Miko,FBD_Trunk,FBD_VL,FBD_VM,FBD_VR
 SG_ RequestSeamlessBLEHandoverFBD__3 : 16|8@1+ (1,0) [0|0] "" FBD_HM,FBD_HR,FBD_MM,FBD_Miko,FBD_Trunk,FBD_VL,FBD_VM,FBD_VR
 SG_ RequestSeamlessBLEHandoverFBD__4 : 24|8@1+ (1.0,0) [0|252] "" FBD_HM,FBD_HR,FBD_MM,FBD_Miko,FBD_Trunk,FBD_VL,FBD_VM,FBD_VR
 SG_ RequestSeamlessBLEHandoverFBD__5 : 32|8@1+ (0.5,-127) [-127|-1] "dB" FBD_HM,FBD_HR,FBD_MM,FBD_Miko,FBD_Trunk,FBD_VL,FBD_VM,FBD_VR
 SG_ RequestSeamlessBLEHandoverFBD__6 : 40|8@1+ (0.5,0) [0|126] "dB" FBD_HM,FBD_HR,FBD_MM,FBD_Miko,FBD_Trunk,FBD_VL,FBD_VM,FBD_VR
 SG_ RequestSeamlessBLEHandoverFBD__7 : 48|8@1+ (1.0,0) [0|252] "ms" FBD_HM,FBD_HR,FBD_MM,FBD_Miko,FBD_Trunk,FBD_VL,FBD_VM,FBD_VR

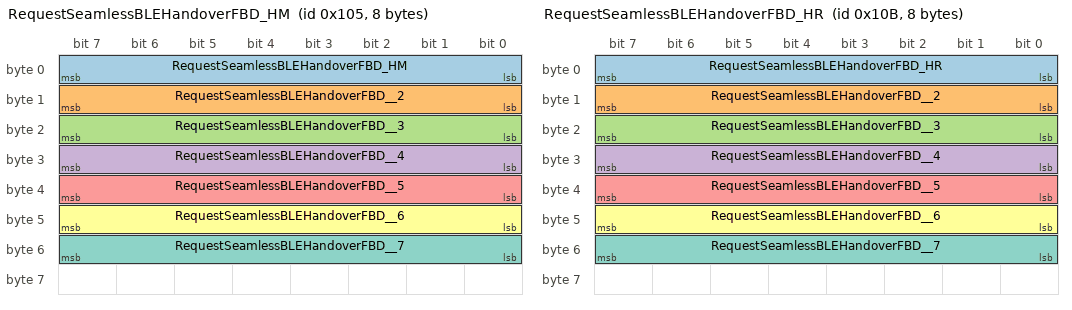
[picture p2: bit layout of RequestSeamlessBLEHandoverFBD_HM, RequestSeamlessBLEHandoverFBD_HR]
BO_ 261 RequestSeamlessBLEHandoverFBD_HM: 8 FBD_HM
 SG_ RequestSeamlessBLEHandoverFBD_HM : 0|8@1+ (1.0,0) [0|252] "" FBD_HL,FBD_HR,FBD_MM,FBD_Miko,FBD_Trunk,FBD_VL,FBD_VM,FBD_VR
 SG_ RequestSeamlessBLEHandoverFBD__2 : 8|8@1+ (1,0) [0|0] "" FBD_HL,FBD_HR,FBD_MM,FBD_Miko,FBD_Trunk,FBD_VL,FBD_VM,FBD_VR
 SG_ RequestSeamlessBLEHandoverFBD__3 : 16|8@1+ (1,0) [0|0] "" FBD_HL,FBD_HR,FBD_MM,FBD_Miko,FBD_Trunk,FBD_VL,FBD_VM,FBD_VR
 SG_ RequestSeamlessBLEHandoverFBD__4 : 24|8@1+ (1.0,0) [0|252] "" FBD_HL,FBD_HR,FBD_MM,FBD_Miko,FBD_Trunk,FBD_VL,FBD_VM,FBD_VR
 SG_ RequestSeamlessBLEHandoverFBD__5 : 32|8@1+ (0.5,-127) [-127|-1] "dB" FBD_HL,FBD_HR,FBD_MM,FBD_Miko,FBD_Trunk,FBD_VL,FBD_VM,FBD_VR
 SG_ RequestSeamlessBLEHandoverFBD__6 : 40|8@1+ (0.5,0) [0|126] "dB" FBD_HL,FBD_HR,FBD_MM,FBD_Miko,FBD_Trunk,FBD_VL,FBD_VM,FBD_VR
 SG_ RequestSeamlessBLEHandoverFBD__7 : 48|8@1+ (1.0,0) [0|252] "ms" FBD_HL,FBD_HR,FBD_MM,FBD_Miko,FBD_Trunk,FBD_VL,FBD_VM,FBD_VR

BO_ 267 RequestSeamlessBLEHandoverFBD_HR: 8 FBD_HR
 SG_ RequestSeamlessBLEHandoverFBD_HR : 0|8@1+ (1.0,0) [0|252] "" FBD_HL,FBD_HM,FBD_MM,FBD_Miko,FBD_Trunk,FBD_VL,FBD_VM,FBD_VR
 SG_ RequestSeamlessBLEHandoverFBD__2 : 8|8@1+ (1,0) [0|0] "" FBD_HL,FBD_HM,FBD_MM,FBD_Miko,FBD_Trunk,FBD_VL,FBD_VM,FBD_VR
 SG_ RequestSeamlessBLEHandoverFBD__3 : 16|8@1+ (1,0) [0|0] "" FBD_HL,FBD_HM,FBD_MM,FBD_Miko,FBD_Trunk,FBD_VL,FBD_VM,FBD_VR
 SG_ RequestSeamlessBLEHandoverFBD__4 : 24|8@1+ (1.0,0) [0|252] "" FBD_HL,FBD_HM,FBD_MM,FBD_Miko,FBD_Trunk,FBD_VL,FBD_VM,FBD_VR
 SG_ RequestSeamlessBLEHandoverFBD__5 : 32|8@1+ (0.5,-127) [-127|-1] "dB" FBD_HL,FBD_HM,FBD_MM,FBD_Miko,FBD_Trunk,FBD_VL,FBD_VM,FBD_VR
 SG_ RequestSeamlessBLEHandoverFBD__6 : 40|8@1+ (0.5,0) [0|126] "dB" FBD_HL,FBD_HM,FBD_MM,FBD_Miko,FBD_Trunk,FBD_VL,FBD_VM,FBD_VR
 SG_ RequestSeamlessBLEHandoverFBD__7 : 48|8@1+ (1.0,0) [0|252] "ms" FBD_HL,FBD_HM,FBD_MM,FBD_Miko,FBD_Trunk,FBD_VL,FBD_VM,FBD_VR

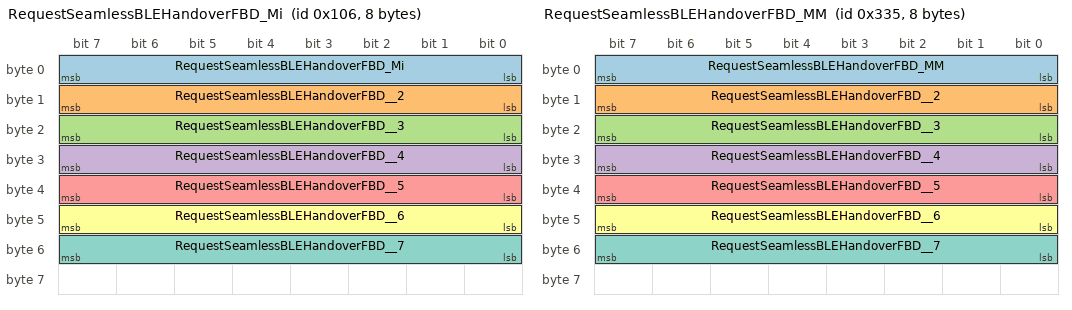
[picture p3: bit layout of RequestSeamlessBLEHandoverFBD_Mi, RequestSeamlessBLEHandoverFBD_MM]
BO_ 262 RequestSeamlessBLEHandoverFBD_Mi: 8 FBD_Miko
 SG_ RequestSeamlessBLEHandoverFBD_Mi : 0|8@1+ (1.0,0) [0|252] "" FBD_HL,FBD_HM,FBD_HR,FBD_MM,FBD_Trunk,FBD_VL,FBD_VM,FBD_VR
 SG_ RequestSeamlessBLEHandoverFBD__2 : 8|8@1+ (1,0) [0|0] "" FBD_HL,FBD_HM,FBD_HR,FBD_MM,FBD_Trunk,FBD_VL,FBD_VM,FBD_VR
 SG_ RequestSeamlessBLEHandoverFBD__3 : 16|8@1+ (1,0) [0|0] "" FBD_HL,FBD_HM,FBD_HR,FBD_MM,FBD_Trunk,FBD_VL,FBD_VM,FBD_VR
 SG_ RequestSeamlessBLEHandoverFBD__4 : 24|8@1+ (1.0,0) [0|252] "" FBD_HL,FBD_HM,FBD_HR,FBD_MM,FBD_Trunk,FBD_VL,FBD_VM,FBD_VR
 SG_ RequestSeamlessBLEHandoverFBD__5 : 32|8@1+ (0.5,-127) [-127|-1] "dB" FBD_HL,FBD_HM,FBD_HR,FBD_MM,FBD_Trunk,FBD_VL,FBD_VM,FBD_VR
 SG_ RequestSeamlessBLEHandoverFBD__6 : 40|8@1+ (0.5,0) [0|126] "dB" FBD_HL,FBD_HM,FBD_HR,FBD_MM,FBD_Trunk,FBD_VL,FBD_VM,FBD_VR
 SG_ RequestSeamlessBLEHandoverFBD__7 : 48|8@1+ (1.0,0) [0|252] "ms" FBD_HL,FBD_HM,FBD_HR,FBD_MM,FBD_Trunk,FBD_VL,FBD_VM,FBD_VR

BO_ 821 RequestSeamlessBLEHandoverFBD_MM: 8 FBD_MM
 SG_ RequestSeamlessBLEHandoverFBD_MM : 0|8@1+ (1.0,0) [0|252] "" FBD_HL,FBD_HM,FBD_HR,FBD_Miko,FBD_Trunk,FBD_VL,FBD_VM,FBD_VR
 SG_ RequestSeamlessBLEHandoverFBD__2 : 8|8@1+ (1,0) [0|0] "" FBD_HL,FBD_HM,FBD_HR,FBD_Miko,FBD_Trunk,FBD_VL,FBD_VM,FBD_VR
 SG_ RequestSeamlessBLEHandoverFBD__3 : 16|8@1+ (1,0) [0|0] "" FBD_HL,FBD_HM,FBD_HR,FBD_Miko,FBD_Trunk,FBD_VL,FBD_VM,FBD_VR
 SG_ RequestSeamlessBLEHandoverFBD__4 : 24|8@1+ (1.0,0) [0|252] "" FBD_HL,FBD_HM,FBD_HR,FBD_Miko,FBD_Trunk,FBD_VL,FBD_VM,FBD_VR
 SG_ RequestSeamlessBLEHandoverFBD__5 : 32|8@1+ (0.5,-127) [-127|-1] "dB" FBD_HL,FBD_HM,FBD_HR,FBD_Miko,FBD_Trunk,FBD_VL,FBD_VM,FBD_VR
 SG_ RequestSeamlessBLEHandoverFBD__6 : 40|8@1+ (0.5,0) [0|126] "dB" FBD_HL,FBD_HM,FBD_HR,FBD_Miko,FBD_Trunk,FBD_VL,FBD_VM,FBD_VR
 SG_ RequestSeamlessBLEHandoverFBD__7 : 48|8@1+ (1.0,0) [0|252] "ms" FBD_HL,FBD_HM,FBD_HR,FBD_Miko,FBD_Trunk,FBD_VL,FBD_VM,FBD_VR

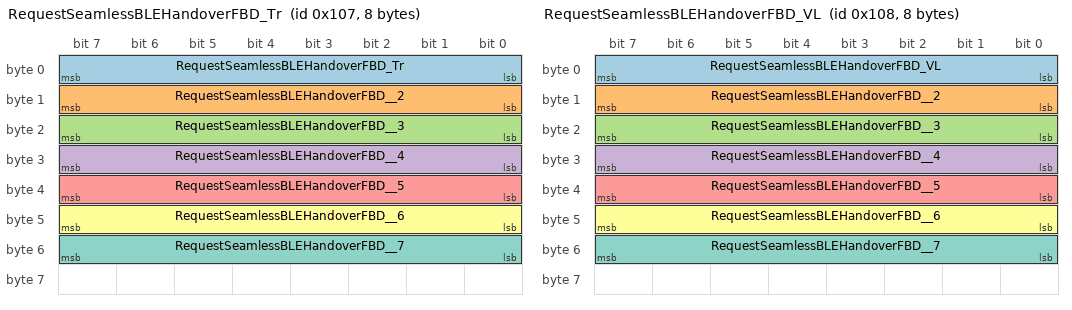
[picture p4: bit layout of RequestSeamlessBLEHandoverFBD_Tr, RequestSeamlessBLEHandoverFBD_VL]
BO_ 263 RequestSeamlessBLEHandoverFBD_Tr: 8 FBD_Trunk
 SG_ RequestSeamlessBLEHandoverFBD_Tr : 0|8@1+ (1.0,0) [0|252] "" FBD_HL,FBD_HM,FBD_HR,FBD_MM,FBD_Miko,FBD_VL,FBD_VM,FBD_VR
 SG_ RequestSeamlessBLEHandoverFBD__2 : 8|8@1+ (1,0) [0|0] "" FBD_HL,FBD_HM,FBD_HR,FBD_MM,FBD_Miko,FBD_VL,FBD_VM,FBD_VR
 SG_ RequestSeamlessBLEHandoverFBD__3 : 16|8@1+ (1,0) [0|0] "" FBD_HL,FBD_HM,FBD_HR,FBD_MM,FBD_Miko,FBD_VL,FBD_VM,FBD_VR
 SG_ RequestSeamlessBLEHandoverFBD__4 : 24|8@1+ (1.0,0) [0|252] "" FBD_HL,FBD_HM,FBD_HR,FBD_MM,FBD_Miko,FBD_VL,FBD_VM,FBD_VR
 SG_ RequestSeamlessBLEHandoverFBD__5 : 32|8@1+ (0.5,-127) [-127|-1] "dB" FBD_HL,FBD_HM,FBD_HR,FBD_MM,FBD_Miko,FBD_VL,FBD_VM,FBD_VR
 SG_ RequestSeamlessBLEHandoverFBD__6 : 40|8@1+ (0.5,0) [0|126] "dB" FBD_HL,FBD_HM,FBD_HR,FBD_MM,FBD_Miko,FBD_VL,FBD_VM,FBD_VR
 SG_ RequestSeamlessBLEHandoverFBD__7 : 48|8@1+ (1.0,0) [0|252] "ms" FBD_HL,FBD_HM,FBD_HR,FBD_MM,FBD_Miko,FBD_VL,FBD_VM,FBD_VR

BO_ 264 RequestSeamlessBLEHandoverFBD_VL: 8 FBD_VL
 SG_ RequestSeamlessBLEHandoverFBD_VL : 0|8@1+ (1.0,0) [0|252] "" FBD_HL,FBD_HM,FBD_HR,FBD_MM,FBD_Miko,FBD_Trunk,FBD_VM,FBD_VR
 SG_ RequestSeamlessBLEHandoverFBD__2 : 8|8@1+ (1,0) [0|0] "" FBD_HL,FBD_HM,FBD_HR,FBD_MM,FBD_Miko,FBD_Trunk,FBD_VM,FBD_VR
 SG_ RequestSeamlessBLEHandoverFBD__3 : 16|8@1+ (1,0) [0|0] "" FBD_HL,FBD_HM,FBD_HR,FBD_MM,FBD_Miko,FBD_Trunk,FBD_VM,FBD_VR
 SG_ RequestSeamlessBLEHandoverFBD__4 : 24|8@1+ (1.0,0) [0|252] "" FBD_HL,FBD_HM,FBD_HR,FBD_MM,FBD_Miko,FBD_Trunk,FBD_VM,FBD_VR
 SG_ RequestSeamlessBLEHandoverFBD__5 : 32|8@1+ (0.5,-127) [-127|-1] "dB" FBD_HL,FBD_HM,FBD_HR,FBD_MM,FBD_Miko,FBD_Trunk,FBD_VM,FBD_VR
 SG_ RequestSeamlessBLEHandoverFBD__6 : 40|8@1+ (0.5,0) [0|126] "dB" FBD_HL,FBD_HM,FBD_HR,FBD_MM,FBD_Miko,FBD_Trunk,FBD_VM,FBD_VR
 SG_ RequestSeamlessBLEHandoverFBD__7 : 48|8@1+ (1.0,0) [0|252] "ms" FBD_HL,FBD_HM,FBD_HR,FBD_MM,FBD_Miko,FBD_Trunk,FBD_VM,FBD_VR

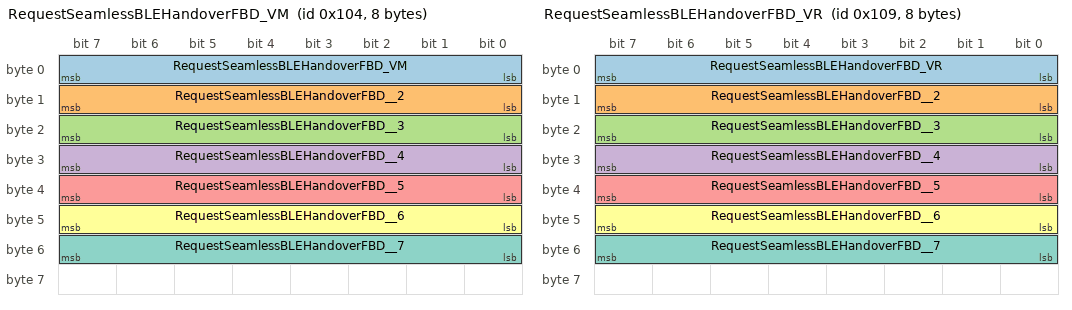
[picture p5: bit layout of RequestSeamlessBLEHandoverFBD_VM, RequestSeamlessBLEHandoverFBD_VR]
BO_ 260 RequestSeamlessBLEHandoverFBD_VM: 8 FBD_VM
 SG_ RequestSeamlessBLEHandoverFBD_VM : 0|8@1+ (1.0,0) [0|252] "" FBD_HL,FBD_HM,FBD_HR,FBD_MM,FBD_Miko,FBD_Trunk,FBD_VL,FBD_VR
 SG_ RequestSeamlessBLEHandoverFBD__2 : 8|8@1+ (1,0) [0|0] "" FBD_HL,FBD_HM,FBD_HR,FBD_MM,FBD_Miko,FBD_Trunk,FBD_VL,FBD_VR
 SG_ RequestSeamlessBLEHandoverFBD__3 : 16|8@1+ (1,0) [0|0] "" FBD_HL,FBD_HM,FBD_HR,FBD_MM,FBD_Miko,FBD_Trunk,FBD_VL,FBD_VR
 SG_ RequestSeamlessBLEHandoverFBD__4 : 24|8@1+ (1.0,0) [0|252] "" FBD_HL,FBD_HM,FBD_HR,FBD_MM,FBD_Miko,FBD_Trunk,FBD_VL,FBD_VR
 SG_ RequestSeamlessBLEHandoverFBD__5 : 32|8@1+ (0.5,-127) [-127|-1] "dB" FBD_HL,FBD_HM,FBD_HR,FBD_MM,FBD_Miko,FBD_Trunk,FBD_VL,FBD_VR
 SG_ RequestSeamlessBLEHandoverFBD__6 : 40|8@1+ (0.5,0) [0|126] "dB" FBD_HL,FBD_HM,FBD_HR,FBD_MM,FBD_Miko,FBD_Trunk,FBD_VL,FBD_VR
 SG_ RequestSeamlessBLEHandoverFBD__7 : 48|8@1+ (1.0,0) [0|252] "ms" FBD_HL,FBD_HM,FBD_HR,FBD_MM,FBD_Miko,FBD_Trunk,FBD_VL,FBD_VR

BO_ 265 RequestSeamlessBLEHandoverFBD_VR: 8 FBD_VR
 SG_ RequestSeamlessBLEHandoverFBD_VR : 0|8@1+ (1.0,0) [0|252] "" FBD_HL,FBD_HM,FBD_HR,FBD_MM,FBD_Miko,FBD_Trunk,FBD_VL,FBD_VM
 SG_ RequestSeamlessBLEHandoverFBD__2 : 8|8@1+ (1,0) [0|0] "" FBD_HL,FBD_HM,FBD_HR,FBD_MM,FBD_Miko,FBD_Trunk,FBD_VL,FBD_VM
 SG_ RequestSeamlessBLEHandoverFBD__3 : 16|8@1+ (1,0) [0|0] "" FBD_HL,FBD_HM,FBD_HR,FBD_MM,FBD_Miko,FBD_Trunk,FBD_VL,FBD_VM
 SG_ RequestSeamlessBLEHandoverFBD__4 : 24|8@1+ (1.0,0) [0|252] "" FBD_HL,FBD_HM,FBD_HR,FBD_MM,FBD_Miko,FBD_Trunk,FBD_VL,FBD_VM
 SG_ RequestSeamlessBLEHandoverFBD__5 : 32|8@1+ (0.5,-127) [-127|-1] "dB" FBD_HL,FBD_HM,FBD_HR,FBD_MM,FBD_Miko,FBD_Trunk,FBD_VL,FBD_VM
 SG_ RequestSeamlessBLEHandoverFBD__6 : 40|8@1+ (0.5,0) [0|126] "dB" FBD_HL,FBD_HM,FBD_HR,FBD_MM,FBD_Miko,FBD_Trunk,FBD_VL,FBD_VM
 SG_ RequestSeamlessBLEHandoverFBD__7 : 48|8@1+ (1.0,0) [0|252] "ms" FBD_HL,FBD_HM,FBD_HR,FBD_MM,FBD_Miko,FBD_Trunk,FBD_VL,FBD_VM

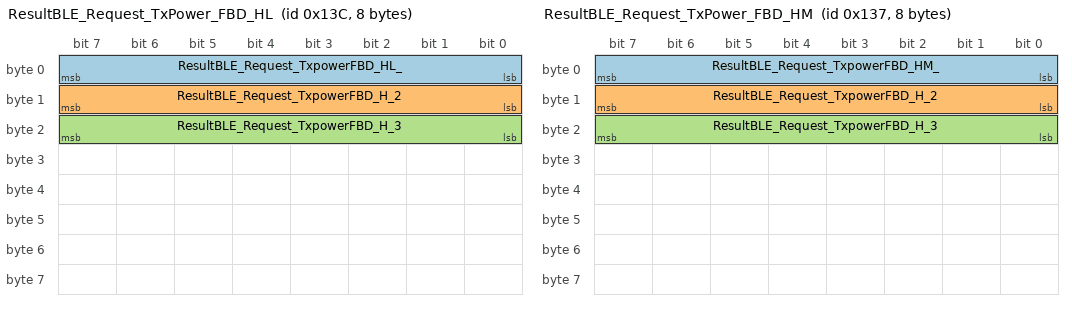
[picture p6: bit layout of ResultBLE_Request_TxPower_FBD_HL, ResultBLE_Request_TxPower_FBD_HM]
BO_ 316 ResultBLE_Request_TxPower_FBD_HL: 8 FBD_HL
 SG_ ResultBLE_Request_TxpowerFBD_HL_ : 0|8@1+ (1.0,0) [0|252] "" FBD_HM,FBD_HR,FBD_MM,FBD_Miko,FBD_Trunk,FBD_VL,FBD_VM,FBD_VR,IPB_App1
 SG_ ResultBLE_Request_TxpowerFBD_H_2 : 8|8@1+ (1.0,0) [0|252] "dB" FBD_HM,FBD_HR,FBD_MM,FBD_Miko,FBD_Trunk,FBD_VL,FBD_VM,FBD_VR,IPB_App1
 SG_ ResultBLE_Request_TxpowerFBD_H_3 : 16|8@1+ (1.0,0) [0|126] "dB" FBD_HM,FBD_HR,FBD_MM,FBD_Miko,FBD_Trunk,FBD_VL,FBD_VM,FBD_VR,IPB_App1

BO_ 311 ResultBLE_Request_TxPower_FBD_HM: 8 FBD_HM
 SG_ ResultBLE_Request_TxpowerFBD_HM_ : 0|8@1+ (1.0,0) [0|252] "" FBD_HL,FBD_HR,FBD_MM,FBD_Miko,FBD_Trunk,FBD_VL,FBD_VM,FBD_VR,IPB_App1
 SG_ ResultBLE_Request_TxpowerFBD_H_2 : 8|8@1+ (1.0,0) [0|252] "dB" FBD_HL,FBD_HR,FBD_MM,FBD_Miko,FBD_Trunk,FBD_VL,FBD_VM,FBD_VR,IPB_App1
 SG_ ResultBLE_Request_TxpowerFBD_H_3 : 16|8@1+ (1.0,0) [0|126] "dB" FBD_HL,FBD_HR,FBD_MM,FBD_Miko,FBD_Trunk,FBD_VL,FBD_VM,FBD_VR,IPB_App1

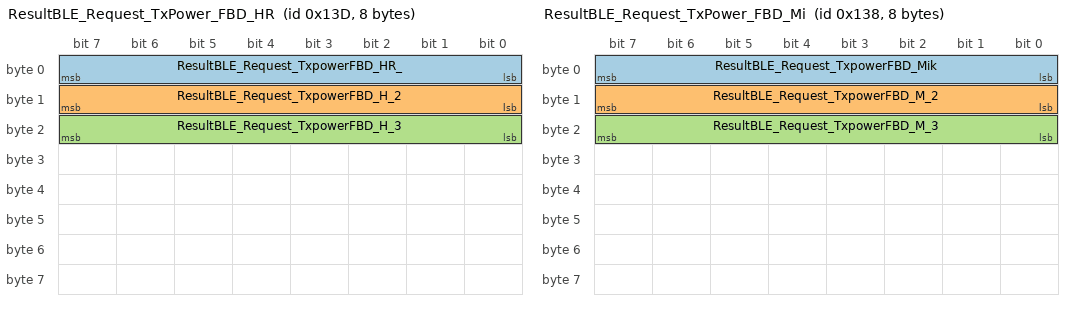
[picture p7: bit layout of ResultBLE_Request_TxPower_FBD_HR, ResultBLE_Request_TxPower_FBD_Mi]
BO_ 317 ResultBLE_Request_TxPower_FBD_HR: 8 FBD_HR
 SG_ ResultBLE_Request_TxpowerFBD_HR_ : 0|8@1+ (1.0,0) [0|252] "" FBD_HL,FBD_HM,FBD_MM,FBD_Miko,FBD_Trunk,FBD_VL,FBD_VM,FBD_VR,IPB_App1
 SG_ ResultBLE_Request_TxpowerFBD_H_2 : 8|8@1+ (1.0,0) [0|252] "dB" FBD_HL,FBD_HM,FBD_MM,FBD_Miko,FBD_Trunk,FBD_VL,FBD_VM,FBD_VR,IPB_App1
 SG_ ResultBLE_Request_TxpowerFBD_H_3 : 16|8@1+ (1.0,0) [0|126] "dB" FBD_HL,FBD_HM,FBD_MM,FBD_Miko,FBD_Trunk,FBD_VL,FBD_VM,FBD_VR,IPB_App1

BO_ 312 ResultBLE_Request_TxPower_FBD_Mi: 8 FBD_Miko
 SG_ ResultBLE_Request_TxpowerFBD_Mik : 0|8@1+ (1.0,0) [0|252] "" FBD_HL,FBD_HM,FBD_HR,FBD_MM,FBD_Trunk,FBD_VL,FBD_VM,FBD_VR,IPB_App1
 SG_ ResultBLE_Request_TxpowerFBD_M_2 : 8|8@1+ (1.0,0) [0|252] "dB" FBD_HL,FBD_HM,FBD_HR,FBD_MM,FBD_Trunk,FBD_VL,FBD_VM,FBD_VR,IPB_App1
 SG_ ResultBLE_Request_TxpowerFBD_M_3 : 16|8@1+ (1.0,0) [0|126] "dB" FBD_HL,FBD_HM,FBD_HR,FBD_MM,FBD_Trunk,FBD_VL,FBD_VM,FBD_VR,IPB_App1

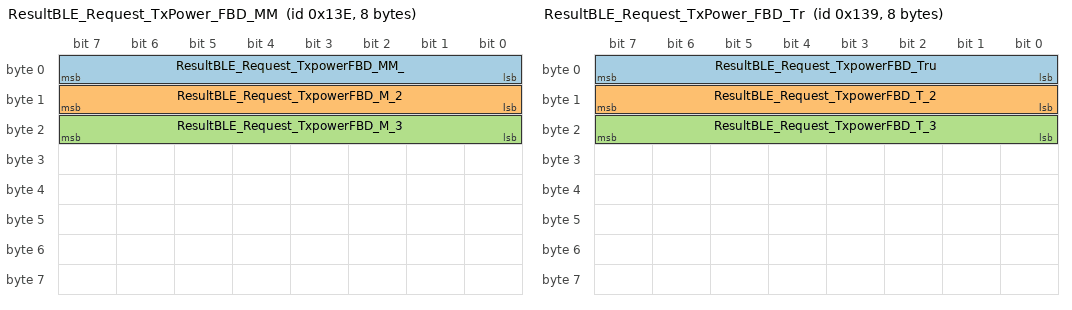
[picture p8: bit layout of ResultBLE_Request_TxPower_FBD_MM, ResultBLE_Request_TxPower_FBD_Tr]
BO_ 318 ResultBLE_Request_TxPower_FBD_MM: 8 FBD_MM
 SG_ ResultBLE_Request_TxpowerFBD_MM_ : 0|8@1+ (1.0,0) [0|252] "" FBD_HL,FBD_HM,FBD_HR,FBD_Miko,FBD_Trunk,FBD_VL,FBD_VM,FBD_VR,IPB_App1
 SG_ ResultBLE_Request_TxpowerFBD_M_2 : 8|8@1+ (1.0,0) [0|252] "dB" FBD_HL,FBD_HM,FBD_HR,FBD_Miko,FBD_Trunk,FBD_VL,FBD_VM,FBD_VR,IPB_App1
 SG_ ResultBLE_Request_TxpowerFBD_M_3 : 16|8@1+ (1.0,0) [0|126] "dB" FBD_HL,FBD_HM,FBD_HR,FBD_Miko,FBD_Trunk,FBD_VL,FBD_VM,FBD_VR,IPB_App1

BO_ 313 ResultBLE_Request_TxPower_FBD_Tr: 8 FBD_Trunk
 SG_ ResultBLE_Request_TxpowerFBD_Tru : 0|8@1+ (1.0,0) [0|252] "" FBD_HL,FBD_HM,FBD_HR,FBD_MM,FBD_Miko,FBD_VL,FBD_VM,FBD_VR,IPB_App1
 SG_ ResultBLE_Request_TxpowerFBD_T_2 : 8|8@1+ (1.0,0) [0|252] "dB" FBD_HL,FBD_HM,FBD_HR,FBD_MM,FBD_Miko,FBD_VL,FBD_VM,FBD_VR,IPB_App1
 SG_ ResultBLE_Request_TxpowerFBD_T_3 : 16|8@1+ (1.0,0) [0|126] "dB" FBD_HL,FBD_HM,FBD_HR,FBD_MM,FBD_Miko,FBD_VL,FBD_VM,FBD_VR,IPB_App1

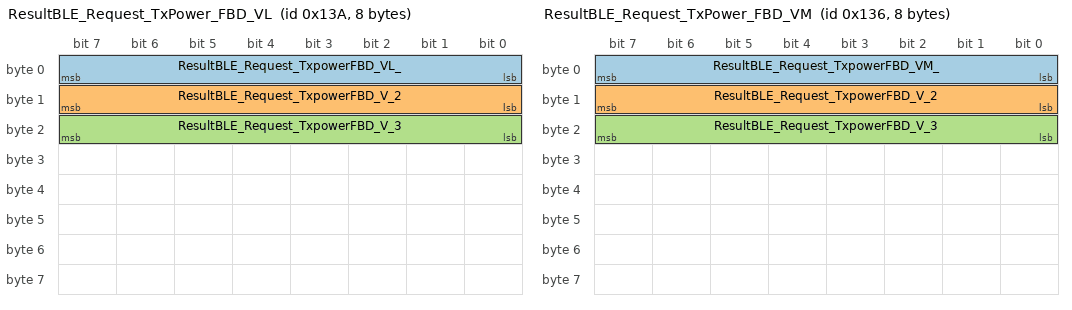
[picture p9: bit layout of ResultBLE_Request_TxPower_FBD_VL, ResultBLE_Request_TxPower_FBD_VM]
BO_ 314 ResultBLE_Request_TxPower_FBD_VL: 8 FBD_VL
 SG_ ResultBLE_Request_TxpowerFBD_VL_ : 0|8@1+ (1.0,0) [0|252] "" FBD_HL,FBD_HM,FBD_HR,FBD_MM,FBD_Miko,FBD_Trunk,FBD_VM,FBD_VR,IPB_App1
 SG_ ResultBLE_Request_TxpowerFBD_V_2 : 8|8@1+ (1.0,0) [0|252] "dB" FBD_HL,FBD_HM,FBD_HR,FBD_MM,FBD_Miko,FBD_Trunk,FBD_VM,FBD_VR,IPB_App1
 SG_ ResultBLE_Request_TxpowerFBD_V_3 : 16|8@1+ (1.0,0) [0|126] "dB" FBD_HL,FBD_HM,FBD_HR,FBD_MM,FBD_Miko,FBD_Trunk,FBD_VM,FBD_VR,IPB_App1

BO_ 310 ResultBLE_Request_TxPower_FBD_VM: 8 FBD_VM
 SG_ ResultBLE_Request_TxpowerFBD_VM_ : 0|8@1+ (1.0,0) [0|252] "" FBD_HL,FBD_HM,FBD_HR,FBD_MM,FBD_Miko,FBD_Trunk,FBD_VL,FBD_VR,IPB_App1
 SG_ ResultBLE_Request_TxpowerFBD_V_2 : 8|8@1+ (1.0,0) [0|252] "dB" FBD_HL,FBD_HM,FBD_HR,FBD_MM,FBD_Miko,FBD_Trunk,FBD_VL,FBD_VR,IPB_App1
 SG_ ResultBLE_Request_TxpowerFBD_V_3 : 16|8@1+ (1.0,0) [0|126] "dB" FBD_HL,FBD_HM,FBD_HR,FBD_MM,FBD_Miko,FBD_Trunk,FBD_VL,FBD_VR,IPB_App1

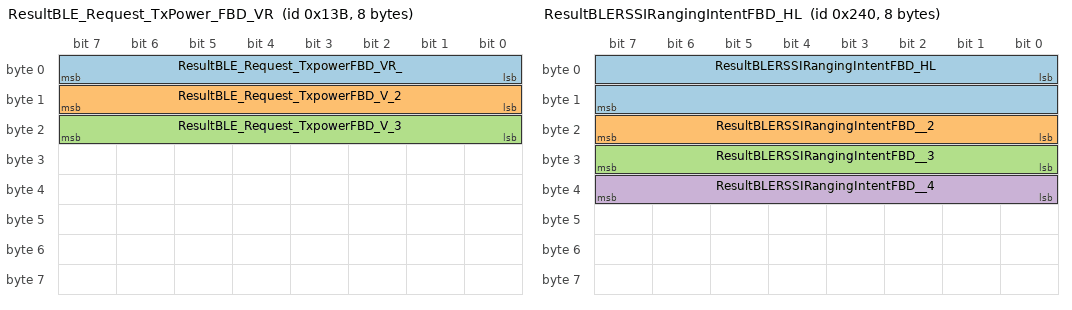
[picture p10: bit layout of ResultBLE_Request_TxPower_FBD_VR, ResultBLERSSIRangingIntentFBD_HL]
BO_ 315 ResultBLE_Request_TxPower_FBD_VR: 8 FBD_VR
 SG_ ResultBLE_Request_TxpowerFBD_VR_ : 0|8@1+ (1.0,0) [0|252] "" FBD_HL,FBD_HM,FBD_HR,FBD_MM,FBD_Miko,FBD_Trunk,FBD_VL,FBD_VM,IPB_App1
 SG_ ResultBLE_Request_TxpowerFBD_V_2 : 8|8@1+ (1.0,0) [0|252] "dB" FBD_HL,FBD_HM,FBD_HR,FBD_MM,FBD_Miko,FBD_Trunk,FBD_VL,FBD_VM,IPB_App1
 SG_ ResultBLE_Request_TxpowerFBD_V_3 : 16|8@1+ (1.0,0) [0|126] "dB" FBD_HL,FBD_HM,FBD_HR,FBD_MM,FBD_Miko,FBD_Trunk,FBD_VL,FBD_VM,IPB_App1

BO_ 296 ResultBLEConMonitoringFBD_HL: 64 FBD_HL
 SG_ ResultBLEConMonitoringFBD_HL_IRK : 0|8@1+ (1.0,0) [0|252] "" FBD_HM,FBD_HR,FBD_MM,FBD_Miko,FBD_Trunk,FBD_VL,FBD_VM,FBD_VR,IPB_App1
 SG_ ResultBLEConMonitoringFBD_HL_RSS : 8|8@1+ (1.0,0) [0|252] "dB" FBD_HM,FBD_HR,FBD_MM,FBD_Miko,FBD_Trunk,FBD_VL,FBD_VM,FBD_VR,IPB_App1
 SG_ ResultBLEConMonitoringFBD_HL_con : 16|16@1+ (1.0,0) [0|65532] "" FBD_HM,FBD_HR,FBD_MM,FBD_Miko,FBD_Trunk,FBD_VL,FBD_VM,FBD_VR,IPB_App1
 SG_ ResultBLEConMonitoringFBD_HL_Ch_ : 32|8@1+ (1.0,0) [0|252] "" FBD_HM,FBD_HR,FBD_MM,FBD_Miko,FBD_Trunk,FBD_VL,FBD_VM,FBD_VR,IPB_App1
 SG_ ResultBLEConMonitoringFBD_HL_Dev : 40|8@1+ (1.0,0) [0|252] "" FBD_HM,FBD_HR,FBD_MM,FBD_Miko,FBD_Trunk,FBD_VL,FBD_VM,FBD_VR,IPB_App1
 SG_ ResultBLEConMonitoringFBD_HL_R_2 : 48|8@1+ (1.0,0) [0|252] "dB" FBD_HM,FBD_HR,FBD_MM,FBD_Miko,FBD_Trunk,FBD_VL,FBD_VM,FBD_VR,IPB_App1
 SG_ ResultBLEConMonitoringFBD_HL_c_2 : 56|16@1+ (1.0,0) [0|65532] "" FBD_HM,FBD_HR,FBD_MM,FBD_Miko,FBD_Trunk,FBD_VL,FBD_VM,FBD_VR,IPB_App1
 SG_ ResultBLEConMonitoringFBD_HL_C_2 : 72|8@1+ (1.0,0) [0|252] "" FBD_HM,FBD_HR,FBD_MM,FBD_Miko,FBD_Trunk,FBD_VL,FBD_VM,FBD_VR,IPB_App1
 SG_ ResultBLEConMonitoringFBD_HL_C_3 : 80|8@1+ (1.0,0) [0|252] "" FBD_HM,FBD_HR,FBD_MM,FBD_Miko,FBD_Trunk,FBD_VL,FBD_VM,FBD_VR,IPB_App1
 SG_ ResultBLEConMonitoringFBD_HL_R_3 : 88|8@1+ (1.0,0) [0|252] "dB" FBD_HM,FBD_HR,FBD_MM,FBD_Miko,FBD_Trunk,FBD_VL,FBD_VM,FBD_VR,IPB_App1
 SG_ ResultBLEConMonitoringFBD_HL_c_3 : 96|16@1+ (1.0,0) [0|65532] "" FBD_HM,FBD_HR,FBD_MM,FBD_Miko,FBD_Trunk,FBD_VL,FBD_VM,FBD_VR,IPB_App1
 SG_ ResultBLEConMonitoringFBD_HL_C_4 : 112|8@1+ (1.0,0) [0|252] "" FBD_HM,FBD_HR,FBD_MM,FBD_Miko,FBD_Trunk,FBD_VL,FBD_VM,FBD_VR,IPB_App1
 SG_ ResultBLEConMonitoringFBD_HL_C_5 : 120|8@1+ (1.0,0) [0|252] "" FBD_HM,FBD_HR,FBD_MM,FBD_Miko,FBD_Trunk,FBD_VL,FBD_VM,FBD_VR,IPB_App1
 SG_ ResultBLEConMonitoringFBD_HL_R_4 : 128|8@1+ (1.0,0) [0|252] "dB" FBD_HM,FBD_HR,FBD_MM,FBD_Miko,FBD_Trunk,FBD_VL,FBD_VM,FBD_VR,IPB_App1
 SG_ ResultBLEConMonitoringFBD_HL_c_4 : 136|16@1+ (1.0,0) [0|65532] "" FBD_HM,FBD_HR,FBD_MM,FBD_Miko,FBD_Trunk,FBD_VL,FBD_VM,FBD_VR,IPB_App1
 SG_ ResultBLEConMonitoringFBD_HL_C_6 : 152|8@1+ (1.0,0) [0|252] "" FBD_HM,FBD_HR,FBD_MM,FBD_Miko,FBD_Trunk,FBD_VL,FBD_VM,FBD_VR,IPB_App1
 SG_ ResultBLEConMonitoringFBD_HL_C_7 : 160|8@1+ (1.0,0) [0|252] "" FBD_HM,FBD_HR,FBD_MM,FBD_Miko,FBD_Trunk,FBD_VL,FBD_VM,FBD_VR,IPB_App1
 SG_ ResultBLEConMonitoringFBD_HL_R_5 : 168|8@1+ (1.0,0) [0|252] "dB" FBD_HM,FBD_HR,FBD_MM,FBD_Miko,FBD_Trunk,FBD_VL,FBD_VM,FBD_VR,IPB_App1
 SG_ ResultBLEConMonitoringFBD_HL_c_5 : 176|16@1+ (1.0,0) [0|65532] "" FBD_HM,FBD_HR,FBD_MM,FBD_Miko,FBD_Trunk,FBD_VL,FBD_VM,FBD_VR,IPB_App1
 SG_ ResultBLEConMonitoringFBD_HL_C_8 : 192|8@1+ (1.0,0) [0|252] "" FBD_HM,FBD_HR,FBD_MM,FBD_Miko,FBD_Trunk,FBD_VL,FBD_VM,FBD_VR,IPB_App1
 SG_ ResultBLEConMonitoringFBD_HL_C_9 : 200|8@1+ (1.0,0) [0|252] "" FBD_HM,FBD_HR,FBD_MM,FBD_Miko,FBD_Trunk,FBD_VL,FBD_VM,FBD_VR,IPB_App1
 SG_ ResultBLEConMonitoringFBD_HL_R_6 : 208|8@1+ (1.0,0) [0|252] "dB" FBD_HM,FBD_HR,FBD_MM,FBD_Miko,FBD_Trunk,FBD_VL,FBD_VM,FBD_VR,IPB_App1
 SG_ ResultBLEConMonitoringFBD_HL_c_6 : 216|16@1+ (1.0,0) [0|65532] "" FBD_HM,FBD_HR,FBD_MM,FBD_Miko,FBD_Trunk,FBD_VL,FBD_VM,FBD_VR,IPB_App1
 SG_ ResultBLEConMonitoringFBD_HL__10 : 232|8@1+ (1.0,0) [0|252] "" FBD_HM,FBD_HR,FBD_MM,FBD_Miko,FBD_Trunk,FBD_VL,FBD_VM,FBD_VR,IPB_App1
 SG_ ResultBLEConMonitoringFBD_HL__11 : 240|8@1+ (1.0,0) [0|252] "" FBD_HM,FBD_HR,FBD_MM,FBD_Miko,FBD_Trunk,FBD_VL,FBD_VM,FBD_VR,IPB_App1
 SG_ ResultBLEConMonitoringFBD_HL_R_7 : 248|8@1+ (1.0,0) [0|252] "dB" FBD_HM,FBD_HR,FBD_MM,FBD_Miko,FBD_Trunk,FBD_VL,FBD_VM,FBD_VR,IPB_App1
 SG_ ResultBLEConMonitoringFBD_HL_c_7 : 256|16@1+ (1.0,0) [0|65532] "" FBD_HM,FBD_HR,FBD_MM,FBD_Miko,FBD_Trunk,FBD_VL,FBD_VM,FBD_VR,IPB_App1
 SG_ ResultBLEConMonitoringFBD_HL__12 : 272|8@1+ (1.0,0) [0|252] "" FBD_HM,FBD_HR,FBD_MM,FBD_Miko,FBD_Trunk,FBD_VL,FBD_VM,FBD_VR,IPB_App1
 SG_ ResultBLEConMonitoringFBD_HL__13 : 280|8@1+ (1.0,0) [0|252] "" FBD_HM,FBD_HR,FBD_MM,FBD_Miko,FBD_Trunk,FBD_VL,FBD_VM,FBD_VR,IPB_App1
 SG_ ResultBLEConMonitoringFBD_HL_R_8 : 288|8@1+ (1.0,0) [0|252] "dB" FBD_HM,FBD_HR,FBD_MM,FBD_Miko,FBD_Trunk,FBD_VL,FBD_VM,FBD_VR,IPB_App1
 SG_ ResultBLEConMonitoringFBD_HL_c_8 : 296|16@1+ (1.0,0) [0|65532] "" FBD_HM,FBD_HR,FBD_MM,FBD_Miko,FBD_Trunk,FBD_VL,FBD_VM,FBD_VR,IPB_App1
 SG_ ResultBLEConMonitoringFBD_HL__14 : 312|8@1+ (1.0,0) [0|252] "" FBD_HM,FBD_HR,FBD_MM,FBD_Miko,FBD_Trunk,FBD_VL,FBD_VM,FBD_VR,IPB_App1
 SG_ ResultBLEConMonitoringFBD_HL__15 : 320|8@1+ (1.0,0) [0|252] "" FBD_HM,FBD_HR,FBD_MM,FBD_Miko,FBD_Trunk,FBD_VL,FBD_VM,FBD_VR,IPB_App1
 SG_ ResultBLEConMonitoringFBD_HL_R_9 : 328|8@1+ (1.0,0) [0|252] "dB" FBD_HM,FBD_HR,FBD_MM,FBD_Miko,FBD_Trunk,FBD_VL,FBD_VM,FBD_VR,IPB_App1
 SG_ ResultBLEConMonitoringFBD_HL_c_9 : 336|16@1+ (1.0,0) [0|65532] "" FBD_HM,FBD_HR,FBD_MM,FBD_Miko,FBD_Trunk,FBD_VL,FBD_VM,FBD_VR,IPB_App1
 SG_ ResultBLEConMonitoringFBD_HL__16 : 352|8@1+ (1.0,0) [0|252] "" FBD_HM,FBD_HR,FBD_MM,FBD_Miko,FBD_Trunk,FBD_VL,FBD_VM,FBD_VR,IPB_App1
 SG_ ResultBLEConMonitoringFBD_HL__17 : 360|8@1+ (1.0,0) [0|252] "" FBD_HM,FBD_HR,FBD_MM,FBD_Miko,FBD_Trunk,FBD_VL,FBD_VM,FBD_VR,IPB_App1
 SG_ ResultBLEConMonitoringFBD_HL__18 : 368|8@1+ (1.0,0) [0|252] "dB" FBD_HM,FBD_HR,FBD_MM,FBD_Miko,FBD_Trunk,FBD_VL,FBD_VM,FBD_VR,IPB_App1
 SG_ ResultBLEConMonitoringFBD_HL__19 : 376|16@1+ (1.0,0) [0|65532] "" FBD_HM,FBD_HR,FBD_MM,FBD_Miko,FBD_Trunk,FBD_VL,FBD_VM,FBD_VR,IPB_App1
 SG_ ResultBLEConMonitoringFBD_HL__20 : 392|8@1+ (1.0,0) [0|252] "" FBD_HM,FBD_HR,FBD_MM,FBD_Miko,FBD_Trunk,FBD_VL,FBD_VM,FBD_VR,IPB_App1
 SG_ ResultBLEConMonitoringFBD_HL__21 : 400|8@1+ (1.0,0) [0|252] "" FBD_HM,FBD_HR,FBD_MM,FBD_Miko,FBD_Trunk,FBD_VL,FBD_VM,FBD_VR,IPB_App1
 SG_ ResultBLEConMonitoringFBD_HL_IV0 : 408|8@1+ (1.0,0) [0|255] "" FBD_HM,FBD_HR,FBD_MM,FBD_Miko,FBD_Trunk,FBD_VL,FBD_VM,FBD_VR,IPB_App1
 SG_ ResultBLEConMonitoringFBD_HL_I_2 : 416|8@1+ (1.0,0) [0|255] "" FBD_HM,FBD_HR,FBD_MM,FBD_Miko,FBD_Trunk,FBD_VL,FBD_VM,FBD_VR,IPB_App1
 SG_ ResultBLEConMonitoringFBD_HL_I_3 : 424|8@1+ (1.0,0) [0|255] "" FBD_HM,FBD_HR,FBD_MM,FBD_Miko,FBD_Trunk,FBD_VL,FBD_VM,FBD_VR,IPB_App1
 SG_ ResultBLEConMonitoringFBD_HL_I_4 : 432|8@1+ (1.0,0) [0|255] "" FBD_HM,FBD_HR,FBD_MM,FBD_Miko,FBD_Trunk,FBD_VL,FBD_VM,FBD_VR,IPB_App1
 SG_ ResultBLEConMonitoringFBD_HL_Sig : 440|8@1+ (1.0,0) [0|255] "" FBD_HM,FBD_HR,FBD_MM,FBD_Miko,FBD_Trunk,FBD_VL,FBD_VM,FBD_VR,IPB_App1
 SG_ ResultBLEConMonitoringFBD_HL_S_2 : 448|8@1+ (1.0,0) [0|255] "" FBD_HM,FBD_HR,FBD_MM,FBD_Miko,FBD_Trunk,FBD_VL,FBD_VM,FBD_VR,IPB_App1
 SG_ ResultBLEConMonitoringFBD_HL_S_3 : 456|8@1+ (1.0,0) [0|255] "" FBD_HM,FBD_HR,FBD_MM,FBD_Miko,FBD_Trunk,FBD_VL,FBD_VM,FBD_VR,IPB_App1
 SG_ ResultBLEConMonitoringFBD_HL_S_4 : 464|8@1+ (1.0,0) [0|255] "" FBD_HM,FBD_HR,FBD_MM,FBD_Miko,FBD_Trunk,FBD_VL,FBD_VM,FBD_VR,IPB_App1
 SG_ ResultBLEConMonitoringFBD_HL_S_5 : 472|8@1+ (1.0,0) [0|255] "" FBD_HM,FBD_HR,FBD_MM,FBD_Miko,FBD_Trunk,FBD_VL,FBD_VM,FBD_VR,IPB_App1
 SG_ ResultBLEConMonitoringFBD_HL_S_6 : 480|8@1+ (1.0,0) [0|255] "" FBD_HM,FBD_HR,FBD_MM,FBD_Miko,FBD_Trunk,FBD_VL,FBD_VM,FBD_VR,IPB_App1
 SG_ ResultBLEConMonitoringFBD_HL_S_7 : 488|8@1+ (1.0,0) [0|255] "" FBD_HM,FBD_HR,FBD_MM,FBD_Miko,FBD_Trunk,FBD_VL,FBD_VM,FBD_VR,IPB_App1
 SG_ ResultBLEConMonitoringFBD_HL_S_8 : 496|8@1+ (1.0,0) [0|255] "" FBD_HM,FBD_HR,FBD_MM,FBD_Miko,FBD_Trunk,FBD_VL,FBD_VM,FBD_VR,IPB_App1

BO_ 291 ResultBLEConMonitoringFBD_HM: 64 FBD_HM
 SG_ ResultBLEConMonitoringFBD_HM_IRK : 0|8@1+ (1.0,0) [0|252] "" FBD_HL,FBD_HR,FBD_MM,FBD_Miko,FBD_Trunk,FBD_VL,FBD_VM,FBD_VR,IPB_App1
 SG_ ResultBLEConMonitoringFBD_HM_RSS : 8|8@1+ (1.0,0) [0|252] "dB" FBD_HL,FBD_HR,FBD_MM,FBD_Miko,FBD_Trunk,FBD_VL,FBD_VM,FBD_VR,IPB_App1
 SG_ ResultBLEConMonitoringFBD_HM_con : 16|16@1+ (1.0,0) [0|65532] "" FBD_HL,FBD_HR,FBD_MM,FBD_Miko,FBD_Trunk,FBD_VL,FBD_VM,FBD_VR,IPB_App1
 SG_ ResultBLEConMonitoringFBD_HM_Ch_ : 32|8@1+ (1.0,0) [0|252] "" FBD_HL,FBD_HR,FBD_MM,FBD_Miko,FBD_Trunk,FBD_VL,FBD_VM,FBD_VR,IPB_App1
 SG_ ResultBLEConMonitoringFBD_HM_Dev : 40|8@1+ (1.0,0) [0|252] "" FBD_HL,FBD_HR,FBD_MM,FBD_Miko,FBD_Trunk,FBD_VL,FBD_VM,FBD_VR,IPB_App1
 SG_ ResultBLEConMonitoringFBD_HM_R_2 : 48|8@1+ (1.0,0) [0|252] "dB" FBD_HL,FBD_HR,FBD_MM,FBD_Miko,FBD_Trunk,FBD_VL,FBD_VM,FBD_VR,IPB_App1
 SG_ ResultBLEConMonitoringFBD_HM_c_2 : 56|16@1+ (1.0,0) [0|65532] "" FBD_HL,FBD_HR,FBD_MM,FBD_Miko,FBD_Trunk,FBD_VL,FBD_VM,FBD_VR,IPB_App1
 SG_ ResultBLEConMonitoringFBD_HM_C_2 : 72|8@1+ (1.0,0) [0|252] "" FBD_HL,FBD_HR,FBD_MM,FBD_Miko,FBD_Trunk,FBD_VL,FBD_VM,FBD_VR,IPB_App1
 SG_ ResultBLEConMonitoringFBD_HM_C_3 : 80|8@1+ (1.0,0) [0|252] "" FBD_HL,FBD_HR,FBD_MM,FBD_Miko,FBD_Trunk,FBD_VL,FBD_VM,FBD_VR,IPB_App1
 SG_ ResultBLEConMonitoringFBD_HM_R_3 : 88|8@1+ (1.0,0) [0|252] "dB" FBD_HL,FBD_HR,FBD_MM,FBD_Miko,FBD_Trunk,FBD_VL,FBD_VM,FBD_VR,IPB_App1
 SG_ ResultBLEConMonitoringFBD_HM_c_3 : 96|16@1+ (1.0,0) [0|65532] "" FBD_HL,FBD_HR,FBD_MM,FBD_Miko,FBD_Trunk,FBD_VL,FBD_VM,FBD_VR,IPB_App1
 SG_ ResultBLEConMonitoringFBD_HM_C_4 : 112|8@1+ (1.0,0) [0|252] "" FBD_HL,FBD_HR,FBD_MM,FBD_Miko,FBD_Trunk,FBD_VL,FBD_VM,FBD_VR,IPB_App1
 SG_ ResultBLEConMonitoringFBD_HM_C_5 : 120|8@1+ (1.0,0) [0|252] "" FBD_HL,FBD_HR,FBD_MM,FBD_Miko,FBD_Trunk,FBD_VL,FBD_VM,FBD_VR,IPB_App1
 SG_ ResultBLEConMonitoringFBD_HM_R_4 : 128|8@1+ (1.0,0) [0|252] "dB" FBD_HL,FBD_HR,FBD_MM,FBD_Miko,FBD_Trunk,FBD_VL,FBD_VM,FBD_VR,IPB_App1
 SG_ ResultBLEConMonitoringFBD_HM_c_4 : 136|16@1+ (1.0,0) [0|65532] "" FBD_HL,FBD_HR,FBD_MM,FBD_Miko,FBD_Trunk,FBD_VL,FBD_VM,FBD_VR,IPB_App1
 SG_ ResultBLEConMonitoringFBD_HM_C_6 : 152|8@1+ (1.0,0) [0|252] "" FBD_HL,FBD_HR,FBD_MM,FBD_Miko,FBD_Trunk,FBD_VL,FBD_VM,FBD_VR,IPB_App1
 SG_ ResultBLEConMonitoringFBD_HM_C_7 : 160|8@1+ (1.0,0) [0|252] "" FBD_HL,FBD_HR,FBD_MM,FBD_Miko,FBD_Trunk,FBD_VL,FBD_VM,FBD_VR,IPB_App1
 SG_ ResultBLEConMonitoringFBD_HM_R_5 : 168|8@1+ (1.0,0) [0|252] "dB" FBD_HL,FBD_HR,FBD_MM,FBD_Miko,FBD_Trunk,FBD_VL,FBD_VM,FBD_VR,IPB_App1
 SG_ ResultBLEConMonitoringFBD_HM_c_5 : 176|16@1+ (1.0,0) [0|65532] "" FBD_HL,FBD_HR,FBD_MM,FBD_Miko,FBD_Trunk,FBD_VL,FBD_VM,FBD_VR,IPB_App1
 SG_ ResultBLEConMonitoringFBD_HM_C_8 : 192|8@1+ (1.0,0) [0|252] "" FBD_HL,FBD_HR,FBD_MM,FBD_Miko,FBD_Trunk,FBD_VL,FBD_VM,FBD_VR,IPB_App1
 SG_ ResultBLEConMonitoringFBD_HM_C_9 : 200|8@1+ (1.0,0) [0|252] "" FBD_HL,FBD_HR,FBD_MM,FBD_Miko,FBD_Trunk,FBD_VL,FBD_VM,FBD_VR,IPB_App1
 SG_ ResultBLEConMonitoringFBD_HM_R_6 : 208|8@1+ (1.0,0) [0|252] "dB" FBD_HL,FBD_HR,FBD_MM,FBD_Miko,FBD_Trunk,FBD_VL,FBD_VM,FBD_VR,IPB_App1
 SG_ ResultBLEConMonitoringFBD_HM_c_6 : 216|16@1+ (1.0,0) [0|65532] "" FBD_HL,FBD_HR,FBD_MM,FBD_Miko,FBD_Trunk,FBD_VL,FBD_VM,FBD_VR,IPB_App1
 SG_ ResultBLEConMonitoringFBD_HM__10 : 232|8@1+ (1.0,0) [0|252] "" FBD_HL,FBD_HR,FBD_MM,FBD_Miko,FBD_Trunk,FBD_VL,FBD_VM,FBD_VR,IPB_App1
 SG_ ResultBLEConMonitoringFBD_HM__11 : 240|8@1+ (1.0,0) [0|252] "" FBD_HL,FBD_HR,FBD_MM,FBD_Miko,FBD_Trunk,FBD_VL,FBD_VM,FBD_VR,IPB_App1
 SG_ ResultBLEConMonitoringFBD_HM_R_7 : 248|8@1+ (1.0,0) [0|252] "dB" FBD_HL,FBD_HR,FBD_MM,FBD_Miko,FBD_Trunk,FBD_VL,FBD_VM,FBD_VR,IPB_App1
 SG_ ResultBLEConMonitoringFBD_HM_c_7 : 256|16@1+ (1.0,0) [0|65532] "" FBD_HL,FBD_HR,FBD_MM,FBD_Miko,FBD_Trunk,FBD_VL,FBD_VM,FBD_VR,IPB_App1
 SG_ ResultBLEConMonitoringFBD_HM__12 : 272|8@1+ (1.0,0) [0|252] "" FBD_HL,FBD_HR,FBD_MM,FBD_Miko,FBD_Trunk,FBD_VL,FBD_VM,FBD_VR,IPB_App1
 SG_ ResultBLEConMonitoringFBD_HM__13 : 280|8@1+ (1.0,0) [0|252] "" FBD_HL,FBD_HR,FBD_MM,FBD_Miko,FBD_Trunk,FBD_VL,FBD_VM,FBD_VR,IPB_App1
 SG_ ResultBLEConMonitoringFBD_HM_R_8 : 288|8@1+ (1.0,0) [0|252] "dB" FBD_HL,FBD_HR,FBD_MM,FBD_Miko,FBD_Trunk,FBD_VL,FBD_VM,FBD_VR,IPB_App1
 SG_ ResultBLEConMonitoringFBD_HM_c_8 : 296|16@1+ (1.0,0) [0|65532] "" FBD_HL,FBD_HR,FBD_MM,FBD_Miko,FBD_Trunk,FBD_VL,FBD_VM,FBD_VR,IPB_App1
 SG_ ResultBLEConMonitoringFBD_HM__14 : 312|8@1+ (1.0,0) [0|252] "" FBD_HL,FBD_HR,FBD_MM,FBD_Miko,FBD_Trunk,FBD_VL,FBD_VM,FBD_VR,IPB_App1
 SG_ ResultBLEConMonitoringFBD_HM__15 : 320|8@1+ (1.0,0) [0|252] "" FBD_HL,FBD_HR,FBD_MM,FBD_Miko,FBD_Trunk,FBD_VL,FBD_VM,FBD_VR,IPB_App1
 SG_ ResultBLEConMonitoringFBD_HM_R_9 : 328|8@1+ (1.0,0) [0|252] "dB" FBD_HL,FBD_HR,FBD_MM,FBD_Miko,FBD_Trunk,FBD_VL,FBD_VM,FBD_VR,IPB_App1
 SG_ ResultBLEConMonitoringFBD_HM_c_9 : 336|16@1+ (1.0,0) [0|65532] "" FBD_HL,FBD_HR,FBD_MM,FBD_Miko,FBD_Trunk,FBD_VL,FBD_VM,FBD_VR,IPB_App1
 SG_ ResultBLEConMonitoringFBD_HM__16 : 352|8@1+ (1.0,0) [0|252] "" FBD_HL,FBD_HR,FBD_MM,FBD_Miko,FBD_Trunk,FBD_VL,FBD_VM,FBD_VR,IPB_App1
 SG_ ResultBLEConMonitoringFBD_HM__17 : 360|8@1+ (1.0,0) [0|252] "" FBD_HL,FBD_HR,FBD_MM,FBD_Miko,FBD_Trunk,FBD_VL,FBD_VM,FBD_VR,IPB_App1
 SG_ ResultBLEConMonitoringFBD_HM__18 : 368|8@1+ (1.0,0) [0|252] "dB" FBD_HL,FBD_HR,FBD_MM,FBD_Miko,FBD_Trunk,FBD_VL,FBD_VM,FBD_VR,IPB_App1
 SG_ ResultBLEConMonitoringFBD_HM__19 : 376|16@1+ (1.0,0) [0|65532] "" FBD_HL,FBD_HR,FBD_MM,FBD_Miko,FBD_Trunk,FBD_VL,FBD_VM,FBD_VR,IPB_App1
 SG_ ResultBLEConMonitoringFBD_HM__20 : 392|8@1+ (1.0,0) [0|252] "" FBD_HL,FBD_HR,FBD_MM,FBD_Miko,FBD_Trunk,FBD_VL,FBD_VM,FBD_VR,IPB_App1
 SG_ ResultBLEConMonitoringFBD_HM__21 : 400|8@1+ (1.0,0) [0|252] "" FBD_HL,FBD_HR,FBD_MM,FBD_Miko,FBD_Trunk,FBD_VL,FBD_VM,FBD_VR,IPB_App1
 SG_ ResultBLEConMonitoringFBD_HM_IV0 : 408|8@1+ (1.0,0) [0|255] "" FBD_HL,FBD_HR,FBD_MM,FBD_Miko,FBD_Trunk,FBD_VL,FBD_VM,FBD_VR,IPB_App1
 SG_ ResultBLEConMonitoringFBD_HM_I_2 : 416|8@1+ (1.0,0) [0|255] "" FBD_HL,FBD_HR,FBD_MM,FBD_Miko,FBD_Trunk,FBD_VL,FBD_VM,FBD_VR,IPB_App1
 SG_ ResultBLEConMonitoringFBD_HM_I_3 : 424|8@1+ (1.0,0) [0|255] "" FBD_HL,FBD_HR,FBD_MM,FBD_Miko,FBD_Trunk,FBD_VL,FBD_VM,FBD_VR,IPB_App1
 SG_ ResultBLEConMonitoringFBD_HM_I_4 : 432|8@1+ (1.0,0) [0|255] "" FBD_HL,FBD_HR,FBD_MM,FBD_Miko,FBD_Trunk,FBD_VL,FBD_VM,FBD_VR,IPB_App1
 SG_ ResultBLEConMonitoringFBD_HM_Sig : 440|8@1+ (1.0,0) [0|255] "" FBD_HL,FBD_HR,FBD_MM,FBD_Miko,FBD_Trunk,FBD_VL,FBD_VM,FBD_VR,IPB_App1
 SG_ ResultBLEConMonitoringFBD_HM_S_2 : 448|8@1+ (1.0,0) [0|255] "" FBD_HL,FBD_HR,FBD_MM,FBD_Miko,FBD_Trunk,FBD_VL,FBD_VM,FBD_VR,IPB_App1
 SG_ ResultBLEConMonitoringFBD_HM_S_3 : 456|8@1+ (1.0,0) [0|255] "" FBD_HL,FBD_HR,FBD_MM,FBD_Miko,FBD_Trunk,FBD_VL,FBD_VM,FBD_VR,IPB_App1
 SG_ ResultBLEConMonitoringFBD_HM_S_4 : 464|8@1+ (1.0,0) [0|255] "" FBD_HL,FBD_HR,FBD_MM,FBD_Miko,FBD_Trunk,FBD_VL,FBD_VM,FBD_VR,IPB_App1
 SG_ ResultBLEConMonitoringFBD_HM_S_5 : 472|8@1+ (1.0,0) [0|255] "" FBD_HL,FBD_HR,FBD_MM,FBD_Miko,FBD_Trunk,FBD_VL,FBD_VM,FBD_VR,IPB_App1
 SG_ ResultBLEConMonitoringFBD_HM_S_6 : 480|8@1+ (1.0,0) [0|255] "" FBD_HL,FBD_HR,FBD_MM,FBD_Miko,FBD_Trunk,FBD_VL,FBD_VM,FBD_VR,IPB_App1
 SG_ ResultBLEConMonitoringFBD_HM_S_7 : 488|8@1+ (1.0,0) [0|255] "" FBD_HL,FBD_HR,FBD_MM,FBD_Miko,FBD_Trunk,FBD_VL,FBD_VM,FBD_VR,IPB_App1
 SG_ ResultBLEConMonitoringFBD_HM_S_8 : 496|8@1+ (1.0,0) [0|255] "" FBD_HL,FBD_HR,FBD_MM,FBD_Miko,FBD_Trunk,FBD_VL,FBD_VM,FBD_VR,IPB_App1

BO_ 297 ResultBLEConMonitoringFBD_HR: 64 FBD_HR
 SG_ ResultBLEConMonitoringFBD_HR_IRK : 0|8@1+ (1.0,0) [0|252] "" FBD_HL,FBD_HM,FBD_MM,FBD_Miko,FBD_Trunk,FBD_VL,FBD_VM,FBD_VR,IPB_App1
 SG_ ResultBLEConMonitoringFBD_HR_RSS : 8|8@1+ (1.0,0) [0|252] "dB" FBD_HL,FBD_HM,FBD_MM,FBD_Miko,FBD_Trunk,FBD_VL,FBD_VM,FBD_VR,IPB_App1
 SG_ ResultBLEConMonitoringFBD_HR_con : 16|16@1+ (1.0,0) [0|65532] "" FBD_HL,FBD_HM,FBD_MM,FBD_Miko,FBD_Trunk,FBD_VL,FBD_VM,FBD_VR,IPB_App1
 SG_ ResultBLEConMonitoringFBD_HR_Ch_ : 32|8@1+ (1.0,0) [0|252] "" FBD_HL,FBD_HM,FBD_MM,FBD_Miko,FBD_Trunk,FBD_VL,FBD_VM,FBD_VR,IPB_App1
 SG_ ResultBLEConMonitoringFBD_HR_Dev : 40|8@1+ (1.0,0) [0|252] "" FBD_HL,FBD_HM,FBD_MM,FBD_Miko,FBD_Trunk,FBD_VL,FBD_VM,FBD_VR,IPB_App1
 SG_ ResultBLEConMonitoringFBD_HR_R_2 : 48|8@1+ (1.0,0) [0|252] "dB" FBD_HL,FBD_HM,FBD_MM,FBD_Miko,FBD_Trunk,FBD_VL,FBD_VM,FBD_VR,IPB_App1
 SG_ ResultBLEConMonitoringFBD_HR_c_2 : 56|16@1+ (1.0,0) [0|65532] "" FBD_HL,FBD_HM,FBD_MM,FBD_Miko,FBD_Trunk,FBD_VL,FBD_VM,FBD_VR,IPB_App1
 SG_ ResultBLEConMonitoringFBD_HR_C_2 : 72|8@1+ (1.0,0) [0|252] "" FBD_HL,FBD_HM,FBD_MM,FBD_Miko,FBD_Trunk,FBD_VL,FBD_VM,FBD_VR,IPB_App1
 SG_ ResultBLEConMonitoringFBD_HR_C_3 : 80|8@1+ (1.0,0) [0|252] "" FBD_HL,FBD_HM,FBD_MM,FBD_Miko,FBD_Trunk,FBD_VL,FBD_VM,FBD_VR,IPB_App1
 SG_ ResultBLEConMonitoringFBD_HR_R_3 : 88|8@1+ (1.0,0) [0|252] "dB" FBD_HL,FBD_HM,FBD_MM,FBD_Miko,FBD_Trunk,FBD_VL,FBD_VM,FBD_VR,IPB_App1
 SG_ ResultBLEConMonitoringFBD_HR_c_3 : 96|16@1+ (1.0,0) [0|65532] "" FBD_HL,FBD_HM,FBD_MM,FBD_Miko,FBD_Trunk,FBD_VL,FBD_VM,FBD_VR,IPB_App1
 SG_ ResultBLEConMonitoringFBD_HR_C_4 : 112|8@1+ (1.0,0) [0|252] "" FBD_HL,FBD_HM,FBD_MM,FBD_Miko,FBD_Trunk,FBD_VL,FBD_VM,FBD_VR,IPB_App1
 SG_ ResultBLEConMonitoringFBD_HR_C_5 : 120|8@1+ (1.0,0) [0|252] "" FBD_HL,FBD_HM,FBD_MM,FBD_Miko,FBD_Trunk,FBD_VL,FBD_VM,FBD_VR,IPB_App1
 SG_ ResultBLEConMonitoringFBD_HR_R_4 : 128|8@1+ (1.0,0) [0|252] "dB" FBD_HL,FBD_HM,FBD_MM,FBD_Miko,FBD_Trunk,FBD_VL,FBD_VM,FBD_VR,IPB_App1
 SG_ ResultBLEConMonitoringFBD_HR_c_4 : 136|16@1+ (1.0,0) [0|65532] "" FBD_HL,FBD_HM,FBD_MM,FBD_Miko,FBD_Trunk,FBD_VL,FBD_VM,FBD_VR,IPB_App1
 SG_ ResultBLEConMonitoringFBD_HR_C_6 : 152|8@1+ (1.0,0) [0|252] "" FBD_HL,FBD_HM,FBD_MM,FBD_Miko,FBD_Trunk,FBD_VL,FBD_VM,FBD_VR,IPB_App1
 SG_ ResultBLEConMonitoringFBD_HR_C_7 : 160|8@1+ (1.0,0) [0|252] "" FBD_HL,FBD_HM,FBD_MM,FBD_Miko,FBD_Trunk,FBD_VL,FBD_VM,FBD_VR,IPB_App1
 SG_ ResultBLEConMonitoringFBD_HR_R_5 : 168|8@1+ (1.0,0) [0|252] "dB" FBD_HL,FBD_HM,FBD_MM,FBD_Miko,FBD_Trunk,FBD_VL,FBD_VM,FBD_VR,IPB_App1
 SG_ ResultBLEConMonitoringFBD_HR_c_5 : 176|16@1+ (1.0,0) [0|65532] "" FBD_HL,FBD_HM,FBD_MM,FBD_Miko,FBD_Trunk,FBD_VL,FBD_VM,FBD_VR,IPB_App1
 SG_ ResultBLEConMonitoringFBD_HR_C_8 : 192|8@1+ (1.0,0) [0|252] "" FBD_HL,FBD_HM,FBD_MM,FBD_Miko,FBD_Trunk,FBD_VL,FBD_VM,FBD_VR,IPB_App1
 SG_ ResultBLEConMonitoringFBD_HR_C_9 : 200|8@1+ (1.0,0) [0|252] "" FBD_HL,FBD_HM,FBD_MM,FBD_Miko,FBD_Trunk,FBD_VL,FBD_VM,FBD_VR,IPB_App1
 SG_ ResultBLEConMonitoringFBD_HR_R_6 : 208|8@1+ (1.0,0) [0|252] "dB" FBD_HL,FBD_HM,FBD_MM,FBD_Miko,FBD_Trunk,FBD_VL,FBD_VM,FBD_VR,IPB_App1
 SG_ ResultBLEConMonitoringFBD_HR_c_6 : 216|16@1+ (1.0,0) [0|65532] "" FBD_HL,FBD_HM,FBD_MM,FBD_Miko,FBD_Trunk,FBD_VL,FBD_VM,FBD_VR,IPB_App1
 SG_ ResultBLEConMonitoringFBD_HR__10 : 232|8@1+ (1.0,0) [0|252] "" FBD_HL,FBD_HM,FBD_MM,FBD_Miko,FBD_Trunk,FBD_VL,FBD_VM,FBD_VR,IPB_App1
 SG_ ResultBLEConMonitoringFBD_HR__11 : 240|8@1+ (1.0,0) [0|252] "" FBD_HL,FBD_HM,FBD_MM,FBD_Miko,FBD_Trunk,FBD_VL,FBD_VM,FBD_VR,IPB_App1
 SG_ ResultBLEConMonitoringFBD_HR_R_7 : 248|8@1+ (1.0,0) [0|252] "dB" FBD_HL,FBD_HM,FBD_MM,FBD_Miko,FBD_Trunk,FBD_VL,FBD_VM,FBD_VR,IPB_App1
 SG_ ResultBLEConMonitoringFBD_HR_c_7 : 256|16@1+ (1.0,0) [0|65532] "" FBD_HL,FBD_HM,FBD_MM,FBD_Miko,FBD_Trunk,FBD_VL,FBD_VM,FBD_VR,IPB_App1
 SG_ ResultBLEConMonitoringFBD_HR__12 : 272|8@1+ (1.0,0) [0|252] "" FBD_HL,FBD_HM,FBD_MM,FBD_Miko,FBD_Trunk,FBD_VL,FBD_VM,FBD_VR,IPB_App1
 SG_ ResultBLEConMonitoringFBD_HR__13 : 280|8@1+ (1.0,0) [0|252] "" FBD_HL,FBD_HM,FBD_MM,FBD_Miko,FBD_Trunk,FBD_VL,FBD_VM,FBD_VR,IPB_App1
 SG_ ResultBLEConMonitoringFBD_HR_R_8 : 288|8@1+ (1.0,0) [0|252] "dB" FBD_HL,FBD_HM,FBD_MM,FBD_Miko,FBD_Trunk,FBD_VL,FBD_VM,FBD_VR,IPB_App1
 SG_ ResultBLEConMonitoringFBD_HR_c_8 : 296|16@1+ (1.0,0) [0|65532] "" FBD_HL,FBD_HM,FBD_MM,FBD_Miko,FBD_Trunk,FBD_VL,FBD_VM,FBD_VR,IPB_App1
 SG_ ResultBLEConMonitoringFBD_HR__14 : 312|8@1+ (1.0,0) [0|252] "" FBD_HL,FBD_HM,FBD_MM,FBD_Miko,FBD_Trunk,FBD_VL,FBD_VM,FBD_VR,IPB_App1
 SG_ ResultBLEConMonitoringFBD_HR__15 : 320|8@1+ (1.0,0) [0|252] "" FBD_HL,FBD_HM,FBD_MM,FBD_Miko,FBD_Trunk,FBD_VL,FBD_VM,FBD_VR,IPB_App1
 SG_ ResultBLEConMonitoringFBD_HR_R_9 : 328|8@1+ (1.0,0) [0|252] "dB" FBD_HL,FBD_HM,FBD_MM,FBD_Miko,FBD_Trunk,FBD_VL,FBD_VM,FBD_VR,IPB_App1
 SG_ ResultBLEConMonitoringFBD_HR_c_9 : 336|16@1+ (1.0,0) [0|65532] "" FBD_HL,FBD_HM,FBD_MM,FBD_Miko,FBD_Trunk,FBD_VL,FBD_VM,FBD_VR,IPB_App1
 SG_ ResultBLEConMonitoringFBD_HR__16 : 352|8@1+ (1.0,0) [0|252] "" FBD_HL,FBD_HM,FBD_MM,FBD_Miko,FBD_Trunk,FBD_VL,FBD_VM,FBD_VR,IPB_App1
 SG_ ResultBLEConMonitoringFBD_HR__17 : 360|8@1+ (1.0,0) [0|252] "" FBD_HL,FBD_HM,FBD_MM,FBD_Miko,FBD_Trunk,FBD_VL,FBD_VM,FBD_VR,IPB_App1
 SG_ ResultBLEConMonitoringFBD_HR__18 : 368|8@1+ (1.0,0) [0|252] "dB" FBD_HL,FBD_HM,FBD_MM,FBD_Miko,FBD_Trunk,FBD_VL,FBD_VM,FBD_VR,IPB_App1
 SG_ ResultBLEConMonitoringFBD_HR__19 : 376|16@1+ (1.0,0) [0|65532] "" FBD_HL,FBD_HM,FBD_MM,FBD_Miko,FBD_Trunk,FBD_VL,FBD_VM,FBD_VR,IPB_App1
 SG_ ResultBLEConMonitoringFBD_HR__20 : 392|8@1+ (1.0,0) [0|252] "" FBD_HL,FBD_HM,FBD_MM,FBD_Miko,FBD_Trunk,FBD_VL,FBD_VM,FBD_VR,IPB_App1
 SG_ ResultBLEConMonitoringFBD_HR__21 : 400|8@1+ (1.0,0) [0|252] "" FBD_HL,FBD_HM,FBD_MM,FBD_Miko,FBD_Trunk,FBD_VL,FBD_VM,FBD_VR,IPB_App1
 SG_ ResultBLEConMonitoringFBD_HR_IV0 : 408|8@1+ (1.0,0) [0|255] "" FBD_HL,FBD_HM,FBD_MM,FBD_Miko,FBD_Trunk,FBD_VL,FBD_VM,FBD_VR,IPB_App1
 SG_ ResultBLEConMonitoringFBD_HR_I_2 : 416|8@1+ (1.0,0) [0|255] "" FBD_HL,FBD_HM,FBD_MM,FBD_Miko,FBD_Trunk,FBD_VL,FBD_VM,FBD_VR,IPB_App1
 SG_ ResultBLEConMonitoringFBD_HR_I_3 : 424|8@1+ (1.0,0) [0|255] "" FBD_HL,FBD_HM,FBD_MM,FBD_Miko,FBD_Trunk,FBD_VL,FBD_VM,FBD_VR,IPB_App1
 SG_ ResultBLEConMonitoringFBD_HR_I_4 : 432|8@1+ (1.0,0) [0|255] "" FBD_HL,FBD_HM,FBD_MM,FBD_Miko,FBD_Trunk,FBD_VL,FBD_VM,FBD_VR,IPB_App1
 SG_ ResultBLEConMonitoringFBD_HR_Sig : 440|8@1+ (1.0,0) [0|255] "" FBD_HL,FBD_HM,FBD_MM,FBD_Miko,FBD_Trunk,FBD_VL,FBD_VM,FBD_VR,IPB_App1
 SG_ ResultBLEConMonitoringFBD_HR_S_2 : 448|8@1+ (1.0,0) [0|255] "" FBD_HL,FBD_HM,FBD_MM,FBD_Miko,FBD_Trunk,FBD_VL,FBD_VM,FBD_VR,IPB_App1
 SG_ ResultBLEConMonitoringFBD_HR_S_3 : 456|8@1+ (1.0,0) [0|255] "" FBD_HL,FBD_HM,FBD_MM,FBD_Miko,FBD_Trunk,FBD_VL,FBD_VM,FBD_VR,IPB_App1
 SG_ ResultBLEConMonitoringFBD_HR_S_4 : 464|8@1+ (1.0,0) [0|255] "" FBD_HL,FBD_HM,FBD_MM,FBD_Miko,FBD_Trunk,FBD_VL,FBD_VM,FBD_VR,IPB_App1
 SG_ ResultBLEConMonitoringFBD_HR_S_5 : 472|8@1+ (1.0,0) [0|255] "" FBD_HL,FBD_HM,FBD_MM,FBD_Miko,FBD_Trunk,FBD_VL,FBD_VM,FBD_VR,IPB_App1
 SG_ ResultBLEConMonitoringFBD_HR_S_6 : 480|8@1+ (1.0,0) [0|255] "" FBD_HL,FBD_HM,FBD_MM,FBD_Miko,FBD_Trunk,FBD_VL,FBD_VM,FBD_VR,IPB_App1
 SG_ ResultBLEConMonitoringFBD_HR_S_7 : 488|8@1+ (1.0,0) [0|255] "" FBD_HL,FBD_HM,FBD_MM,FBD_Miko,FBD_Trunk,FBD_VL,FBD_VM,FBD_VR,IPB_App1
 SG_ ResultBLEConMonitoringFBD_HR_S_8 : 496|8@1+ (1.0,0) [0|255] "" FBD_HL,FBD_HM,FBD_MM,FBD_Miko,FBD_Trunk,FBD_VL,FBD_VM,FBD_VR,IPB_App1

BO_ 292 ResultBLEConMonitoringFBD_Miko: 64 FBD_Miko
 SG_ ResultBLEConMonitoringFBD_Miko_I : 0|8@1+ (1.0,0) [0|252] "" FBD_HL,FBD_HM,FBD_HR,FBD_MM,FBD_Trunk,FBD_VL,FBD_VM,FBD_VR,IPB_App1
 SG_ ResultBLEConMonitoringFBD_Miko_R : 8|8@1+ (1.0,0) [0|252] "dB" FBD_HL,FBD_HM,FBD_HR,FBD_MM,FBD_Trunk,FBD_VL,FBD_VM,FBD_VR,IPB_App1
 SG_ ResultBLEConMonitoringFBD_Miko_c : 16|16@1+ (1.0,0) [0|65532] "" FBD_HL,FBD_HM,FBD_HR,FBD_MM,FBD_Trunk,FBD_VL,FBD_VM,FBD_VR,IPB_App1
 SG_ ResultBLEConMonitoringFBD_Miko_C : 32|8@1+ (1.0,0) [0|252] "" FBD_HL,FBD_HM,FBD_HR,FBD_MM,FBD_Trunk,FBD_VL,FBD_VM,FBD_VR,IPB_App1
 SG_ ResultBLEConMonitoringFBD_Miko_D : 40|8@1+ (1.0,0) [0|252] "" FBD_HL,FBD_HM,FBD_HR,FBD_MM,FBD_Trunk,FBD_VL,FBD_VM,FBD_VR,IPB_App1
 SG_ ResultBLEConMonitoringFBD_Miko_2 : 48|8@1+ (1.0,0) [0|252] "dB" FBD_HL,FBD_HM,FBD_HR,FBD_MM,FBD_Trunk,FBD_VL,FBD_VM,FBD_VR,IPB_App1
 SG_ ResultBLEConMonitoringFBD_Miko_3 : 56|16@1+ (1.0,0) [0|65532] "" FBD_HL,FBD_HM,FBD_HR,FBD_MM,FBD_Trunk,FBD_VL,FBD_VM,FBD_VR,IPB_App1
 SG_ ResultBLEConMonitoringFBD_Miko_4 : 72|8@1+ (1.0,0) [0|252] "" FBD_HL,FBD_HM,FBD_HR,FBD_MM,FBD_Trunk,FBD_VL,FBD_VM,FBD_VR,IPB_App1
 SG_ ResultBLEConMonitoringFBD_Miko_5 : 80|8@1+ (1.0,0) [0|252] "" FBD_HL,FBD_HM,FBD_HR,FBD_MM,FBD_Trunk,FBD_VL,FBD_VM,FBD_VR,IPB_App1
 SG_ ResultBLEConMonitoringFBD_Miko_6 : 88|8@1+ (1.0,0) [0|252] "dB" FBD_HL,FBD_HM,FBD_HR,FBD_MM,FBD_Trunk,FBD_VL,FBD_VM,FBD_VR,IPB_App1
 SG_ ResultBLEConMonitoringFBD_Miko_7 : 96|16@1+ (1.0,0) [0|65532] "" FBD_HL,FBD_HM,FBD_HR,FBD_MM,FBD_Trunk,FBD_VL,FBD_VM,FBD_VR,IPB_App1
 SG_ ResultBLEConMonitoringFBD_Miko_8 : 112|8@1+ (1.0,0) [0|252] "" FBD_HL,FBD_HM,FBD_HR,FBD_MM,FBD_Trunk,FBD_VL,FBD_VM,FBD_VR,IPB_App1
 SG_ ResultBLEConMonitoringFBD_Miko_9 : 120|8@1+ (1.0,0) [0|252] "" FBD_HL,FBD_HM,FBD_HR,FBD_MM,FBD_Trunk,FBD_VL,FBD_VM,FBD_VR,IPB_App1
 SG_ ResultBLEConMonitoringFBD_Mik_10 : 128|8@1+ (1.0,0) [0|252] "dB" FBD_HL,FBD_HM,FBD_HR,FBD_MM,FBD_Trunk,FBD_VL,FBD_VM,FBD_VR,IPB_App1
 SG_ ResultBLEConMonitoringFBD_Mik_11 : 136|16@1+ (1.0,0) [0|65532] "" FBD_HL,FBD_HM,FBD_HR,FBD_MM,FBD_Trunk,FBD_VL,FBD_VM,FBD_VR,IPB_App1
 SG_ ResultBLEConMonitoringFBD_Mik_12 : 152|8@1+ (1.0,0) [0|252] "" FBD_HL,FBD_HM,FBD_HR,FBD_MM,FBD_Trunk,FBD_VL,FBD_VM,FBD_VR,IPB_App1
 SG_ ResultBLEConMonitoringFBD_Mik_13 : 160|8@1+ (1.0,0) [0|252] "" FBD_HL,FBD_HM,FBD_HR,FBD_MM,FBD_Trunk,FBD_VL,FBD_VM,FBD_VR,IPB_App1
 SG_ ResultBLEConMonitoringFBD_Mik_14 : 168|8@1+ (1.0,0) [0|252] "dB" FBD_HL,FBD_HM,FBD_HR,FBD_MM,FBD_Trunk,FBD_VL,FBD_VM,FBD_VR,IPB_App1
 SG_ ResultBLEConMonitoringFBD_Mik_15 : 176|16@1+ (1.0,0) [0|65532] "" FBD_HL,FBD_HM,FBD_HR,FBD_MM,FBD_Trunk,FBD_VL,FBD_VM,FBD_VR,IPB_App1
 SG_ ResultBLEConMonitoringFBD_Mik_16 : 192|8@1+ (1.0,0) [0|252] "" FBD_HL,FBD_HM,FBD_HR,FBD_MM,FBD_Trunk,FBD_VL,FBD_VM,FBD_VR,IPB_App1
 SG_ ResultBLEConMonitoringFBD_Mik_17 : 200|8@1+ (1.0,0) [0|252] "" FBD_HL,FBD_HM,FBD_HR,FBD_MM,FBD_Trunk,FBD_VL,FBD_VM,FBD_VR,IPB_App1
 SG_ ResultBLEConMonitoringFBD_Mik_18 : 208|8@1+ (1.0,0) [0|252] "dB" FBD_HL,FBD_HM,FBD_HR,FBD_MM,FBD_Trunk,FBD_VL,FBD_VM,FBD_VR,IPB_App1
 SG_ ResultBLEConMonitoringFBD_Mik_19 : 216|16@1+ (1.0,0) [0|65532] "" FBD_HL,FBD_HM,FBD_HR,FBD_MM,FBD_Trunk,FBD_VL,FBD_VM,FBD_VR,IPB_App1
 SG_ ResultBLEConMonitoringFBD_Mik_20 : 232|8@1+ (1.0,0) [0|252] "" FBD_HL,FBD_HM,FBD_HR,FBD_MM,FBD_Trunk,FBD_VL,FBD_VM,FBD_VR,IPB_App1
 SG_ ResultBLEConMonitoringFBD_Mik_21 : 240|8@1+ (1.0,0) [0|252] "" FBD_HL,FBD_HM,FBD_HR,FBD_MM,FBD_Trunk,FBD_VL,FBD_VM,FBD_VR,IPB_App1
 SG_ ResultBLEConMonitoringFBD_Mik_22 : 248|8@1+ (1.0,0) [0|252] "dB" FBD_HL,FBD_HM,FBD_HR,FBD_MM,FBD_Trunk,FBD_VL,FBD_VM,FBD_VR,IPB_App1
 SG_ ResultBLEConMonitoringFBD_Mik_23 : 256|16@1+ (1.0,0) [0|65532] "" FBD_HL,FBD_HM,FBD_HR,FBD_MM,FBD_Trunk,FBD_VL,FBD_VM,FBD_VR,IPB_App1
 SG_ ResultBLEConMonitoringFBD_Mik_24 : 272|8@1+ (1.0,0) [0|252] "" FBD_HL,FBD_HM,FBD_HR,FBD_MM,FBD_Trunk,FBD_VL,FBD_VM,FBD_VR,IPB_App1
 SG_ ResultBLEConMonitoringFBD_Mik_25 : 280|8@1+ (1.0,0) [0|252] "" FBD_HL,FBD_HM,FBD_HR,FBD_MM,FBD_Trunk,FBD_VL,FBD_VM,FBD_VR,IPB_App1
 SG_ ResultBLEConMonitoringFBD_Mik_26 : 288|8@1+ (1.0,0) [0|252] "dB" FBD_HL,FBD_HM,FBD_HR,FBD_MM,FBD_Trunk,FBD_VL,FBD_VM,FBD_VR,IPB_App1
 SG_ ResultBLEConMonitoringFBD_Mik_27 : 296|16@1+ (1.0,0) [0|65532] "" FBD_HL,FBD_HM,FBD_HR,FBD_MM,FBD_Trunk,FBD_VL,FBD_VM,FBD_VR,IPB_App1
 SG_ ResultBLEConMonitoringFBD_Mik_28 : 312|8@1+ (1.0,0) [0|252] "" FBD_HL,FBD_HM,FBD_HR,FBD_MM,FBD_Trunk,FBD_VL,FBD_VM,FBD_VR,IPB_App1
 SG_ ResultBLEConMonitoringFBD_Mik_29 : 320|8@1+ (1.0,0) [0|252] "" FBD_HL,FBD_HM,FBD_HR,FBD_MM,FBD_Trunk,FBD_VL,FBD_VM,FBD_VR,IPB_App1
 SG_ ResultBLEConMonitoringFBD_Mik_30 : 328|8@1+ (1.0,0) [0|252] "dB" FBD_HL,FBD_HM,FBD_HR,FBD_MM,FBD_Trunk,FBD_VL,FBD_VM,FBD_VR,IPB_App1
 SG_ ResultBLEConMonitoringFBD_Mik_31 : 336|16@1+ (1.0,0) [0|65532] "" FBD_HL,FBD_HM,FBD_HR,FBD_MM,FBD_Trunk,FBD_VL,FBD_VM,FBD_VR,IPB_App1
 SG_ ResultBLEConMonitoringFBD_Mik_32 : 352|8@1+ (1.0,0) [0|252] "" FBD_HL,FBD_HM,FBD_HR,FBD_MM,FBD_Trunk,FBD_VL,FBD_VM,FBD_VR,IPB_App1
 SG_ ResultBLEConMonitoringFBD_Mik_33 : 360|8@1+ (1.0,0) [0|252] "" FBD_HL,FBD_HM,FBD_HR,FBD_MM,FBD_Trunk,FBD_VL,FBD_VM,FBD_VR,IPB_App1
 SG_ ResultBLEConMonitoringFBD_Mik_34 : 368|8@1+ (1.0,0) [0|252] "dB" FBD_HL,FBD_HM,FBD_HR,FBD_MM,FBD_Trunk,FBD_VL,FBD_VM,FBD_VR,IPB_App1
 SG_ ResultBLEConMonitoringFBD_Mik_35 : 376|16@1+ (1.0,0) [0|65532] "" FBD_HL,FBD_HM,FBD_HR,FBD_MM,FBD_Trunk,FBD_VL,FBD_VM,FBD_VR,IPB_App1
 SG_ ResultBLEConMonitoringFBD_Mik_36 : 392|8@1+ (1.0,0) [0|252] "" FBD_HL,FBD_HM,FBD_HR,FBD_MM,FBD_Trunk,FBD_VL,FBD_VM,FBD_VR,IPB_App1
 SG_ ResultBLEConMonitoringFBD_Mik_37 : 400|8@1+ (1.0,0) [0|252] "" FBD_HL,FBD_HM,FBD_HR,FBD_MM,FBD_Trunk,FBD_VL,FBD_VM,FBD_VR,IPB_App1
 SG_ ResultBLEConMonitoringFBD_Mik_38 : 408|8@1+ (1.0,0) [0|255] "" FBD_HL,FBD_HM,FBD_HR,FBD_MM,FBD_Trunk,FBD_VL,FBD_VM,FBD_VR,IPB_App1
 SG_ ResultBLEConMonitoringFBD_Mik_39 : 416|8@1+ (1.0,0) [0|255] "" FBD_HL,FBD_HM,FBD_HR,FBD_MM,FBD_Trunk,FBD_VL,FBD_VM,FBD_VR,IPB_App1
 SG_ ResultBLEConMonitoringFBD_Mik_40 : 424|8@1+ (1.0,0) [0|255] "" FBD_HL,FBD_HM,FBD_HR,FBD_MM,FBD_Trunk,FBD_VL,FBD_VM,FBD_VR,IPB_App1
 SG_ ResultBLEConMonitoringFBD_Mik_41 : 432|8@1+ (1.0,0) [0|255] "" FBD_HL,FBD_HM,FBD_HR,FBD_MM,FBD_Trunk,FBD_VL,FBD_VM,FBD_VR,IPB_App1
 SG_ ResultBLEConMonitoringFBD_Miko_S : 440|8@1+ (1.0,0) [0|255] "" FBD_HL,FBD_HM,FBD_HR,FBD_MM,FBD_Trunk,FBD_VL,FBD_VM,FBD_VR,IPB_App1
 SG_ ResultBLEConMonitoringFBD_Mik_42 : 448|8@1+ (1.0,0) [0|255] "" FBD_HL,FBD_HM,FBD_HR,FBD_MM,FBD_Trunk,FBD_VL,FBD_VM,FBD_VR,IPB_App1
 SG_ ResultBLEConMonitoringFBD_Mik_43 : 456|8@1+ (1.0,0) [0|255] "" FBD_HL,FBD_HM,FBD_HR,FBD_MM,FBD_Trunk,FBD_VL,FBD_VM,FBD_VR,IPB_App1
 SG_ ResultBLEConMonitoringFBD_Mik_44 : 464|8@1+ (1.0,0) [0|255] "" FBD_HL,FBD_HM,FBD_HR,FBD_MM,FBD_Trunk,FBD_VL,FBD_VM,FBD_VR,IPB_App1
 SG_ ResultBLEConMonitoringFBD_Mik_45 : 472|8@1+ (1.0,0) [0|255] "" FBD_HL,FBD_HM,FBD_HR,FBD_MM,FBD_Trunk,FBD_VL,FBD_VM,FBD_VR,IPB_App1
 SG_ ResultBLEConMonitoringFBD_Mik_46 : 480|8@1+ (1.0,0) [0|255] "" FBD_HL,FBD_HM,FBD_HR,FBD_MM,FBD_Trunk,FBD_VL,FBD_VM,FBD_VR,IPB_App1
 SG_ ResultBLEConMonitoringFBD_Mik_47 : 488|8@1+ (1.0,0) [0|255] "" FBD_HL,FBD_HM,FBD_HR,FBD_MM,FBD_Trunk,FBD_VL,FBD_VM,FBD_VR,IPB_App1
 SG_ ResultBLEConMonitoringFBD_Mik_48 : 496|8@1+ (1.0,0) [0|255] "" FBD_HL,FBD_HM,FBD_HR,FBD_MM,FBD_Trunk,FBD_VL,FBD_VM,FBD_VR,IPB_App1

BO_ 825 ResultBLEConMonitoringFBD_MM: 64 FBD_MM
 SG_ ResultBLEConMonitoringFBD_MM_IRK : 0|8@1+ (1.0,0) [0|252] "" FBD_HL,FBD_HM,FBD_HR,FBD_Miko,FBD_Trunk,FBD_VL,FBD_VM,FBD_VR,IPB_App1
 SG_ ResultBLEConMonitoringFBD_MM_RSS : 8|8@1+ (1.0,0) [0|252] "dB" FBD_HL,FBD_HM,FBD_HR,FBD_Miko,FBD_Trunk,FBD_VL,FBD_VM,FBD_VR,IPB_App1
 SG_ ResultBLEConMonitoringFBD_MM_con : 16|16@1+ (1.0,0) [0|65532] "" FBD_HL,FBD_HM,FBD_HR,FBD_Miko,FBD_Trunk,FBD_VL,FBD_VM,FBD_VR,IPB_App1
 SG_ ResultBLEConMonitoringFBD_MM_Ch_ : 32|8@1+ (1.0,0) [0|252] "" FBD_HL,FBD_HM,FBD_HR,FBD_Miko,FBD_Trunk,FBD_VL,FBD_VM,FBD_VR,IPB_App1
 SG_ ResultBLEConMonitoringFBD_MM_Dev : 40|8@1+ (1.0,0) [0|252] "" FBD_HL,FBD_HM,FBD_HR,FBD_Miko,FBD_Trunk,FBD_VL,FBD_VM,FBD_VR,IPB_App1
 SG_ ResultBLEConMonitoringFBD_MM_R_2 : 48|8@1+ (1.0,0) [0|252] "dB" FBD_HL,FBD_HM,FBD_HR,FBD_Miko,FBD_Trunk,FBD_VL,FBD_VM,FBD_VR,IPB_App1
 SG_ ResultBLEConMonitoringFBD_MM_c_2 : 56|16@1+ (1.0,0) [0|65532] "" FBD_HL,FBD_HM,FBD_HR,FBD_Miko,FBD_Trunk,FBD_VL,FBD_VM,FBD_VR,IPB_App1
 SG_ ResultBLEConMonitoringFBD_MM_C_2 : 72|8@1+ (1.0,0) [0|252] "" FBD_HL,FBD_HM,FBD_HR,FBD_Miko,FBD_Trunk,FBD_VL,FBD_VM,FBD_VR,IPB_App1
 SG_ ResultBLEConMonitoringFBD_MM_C_3 : 80|8@1+ (1.0,0) [0|252] "" FBD_HL,FBD_HM,FBD_HR,FBD_Miko,FBD_Trunk,FBD_VL,FBD_VM,FBD_VR,IPB_App1
 SG_ ResultBLEConMonitoringFBD_MM_R_3 : 88|8@1+ (1.0,0) [0|252] "dB" FBD_HL,FBD_HM,FBD_HR,FBD_Miko,FBD_Trunk,FBD_VL,FBD_VM,FBD_VR,IPB_App1
 SG_ ResultBLEConMonitoringFBD_MM_c_3 : 96|16@1+ (1.0,0) [0|65532] "" FBD_HL,FBD_HM,FBD_HR,FBD_Miko,FBD_Trunk,FBD_VL,FBD_VM,FBD_VR,IPB_App1
 SG_ ResultBLEConMonitoringFBD_MM_C_4 : 112|8@1+ (1.0,0) [0|252] "" FBD_HL,FBD_HM,FBD_HR,FBD_Miko,FBD_Trunk,FBD_VL,FBD_VM,FBD_VR,IPB_App1
 SG_ ResultBLEConMonitoringFBD_MM_C_5 : 120|8@1+ (1.0,0) [0|252] "" FBD_HL,FBD_HM,FBD_HR,FBD_Miko,FBD_Trunk,FBD_VL,FBD_VM,FBD_VR,IPB_App1
 SG_ ResultBLEConMonitoringFBD_MM_R_4 : 128|8@1+ (1.0,0) [0|252] "dB" FBD_HL,FBD_HM,FBD_HR,FBD_Miko,FBD_Trunk,FBD_VL,FBD_VM,FBD_VR,IPB_App1
 SG_ ResultBLEConMonitoringFBD_MM_c_4 : 136|16@1+ (1.0,0) [0|65532] "" FBD_HL,FBD_HM,FBD_HR,FBD_Miko,FBD_Trunk,FBD_VL,FBD_VM,FBD_VR,IPB_App1
 SG_ ResultBLEConMonitoringFBD_MM_C_6 : 152|8@1+ (1.0,0) [0|252] "" FBD_HL,FBD_HM,FBD_HR,FBD_Miko,FBD_Trunk,FBD_VL,FBD_VM,FBD_VR,IPB_App1
 SG_ ResultBLEConMonitoringFBD_MM_C_7 : 160|8@1+ (1.0,0) [0|252] "" FBD_HL,FBD_HM,FBD_HR,FBD_Miko,FBD_Trunk,FBD_VL,FBD_VM,FBD_VR,IPB_App1
 SG_ ResultBLEConMonitoringFBD_MM_R_5 : 168|8@1+ (1.0,0) [0|252] "dB" FBD_HL,FBD_HM,FBD_HR,FBD_Miko,FBD_Trunk,FBD_VL,FBD_VM,FBD_VR,IPB_App1
 SG_ ResultBLEConMonitoringFBD_MM_c_5 : 176|16@1+ (1.0,0) [0|65532] "" FBD_HL,FBD_HM,FBD_HR,FBD_Miko,FBD_Trunk,FBD_VL,FBD_VM,FBD_VR,IPB_App1
 SG_ ResultBLEConMonitoringFBD_MM_C_8 : 192|8@1+ (1.0,0) [0|252] "" FBD_HL,FBD_HM,FBD_HR,FBD_Miko,FBD_Trunk,FBD_VL,FBD_VM,FBD_VR,IPB_App1
 SG_ ResultBLEConMonitoringFBD_MM_C_9 : 200|8@1+ (1.0,0) [0|252] "" FBD_HL,FBD_HM,FBD_HR,FBD_Miko,FBD_Trunk,FBD_VL,FBD_VM,FBD_VR,IPB_App1
 SG_ ResultBLEConMonitoringFBD_MM_R_6 : 208|8@1+ (1.0,0) [0|252] "dB" FBD_HL,FBD_HM,FBD_HR,FBD_Miko,FBD_Trunk,FBD_VL,FBD_VM,FBD_VR,IPB_App1
 SG_ ResultBLEConMonitoringFBD_MM_c_6 : 216|16@1+ (1.0,0) [0|65532] "" FBD_HL,FBD_HM,FBD_HR,FBD_Miko,FBD_Trunk,FBD_VL,FBD_VM,FBD_VR,IPB_App1
 SG_ ResultBLEConMonitoringFBD_MM__10 : 232|8@1+ (1.0,0) [0|252] "" FBD_HL,FBD_HM,FBD_HR,FBD_Miko,FBD_Trunk,FBD_VL,FBD_VM,FBD_VR,IPB_App1
 SG_ ResultBLEConMonitoringFBD_MM__11 : 240|8@1+ (1.0,0) [0|252] "" FBD_HL,FBD_HM,FBD_HR,FBD_Miko,FBD_Trunk,FBD_VL,FBD_VM,FBD_VR,IPB_App1
 SG_ ResultBLEConMonitoringFBD_MM_R_7 : 248|8@1+ (1.0,0) [0|252] "dB" FBD_HL,FBD_HM,FBD_HR,FBD_Miko,FBD_Trunk,FBD_VL,FBD_VM,FBD_VR,IPB_App1
 SG_ ResultBLEConMonitoringFBD_MM_c_7 : 256|16@1+ (1.0,0) [0|65532] "" FBD_HL,FBD_HM,FBD_HR,FBD_Miko,FBD_Trunk,FBD_VL,FBD_VM,FBD_VR,IPB_App1
 SG_ ResultBLEConMonitoringFBD_MM__12 : 272|8@1+ (1.0,0) [0|252] "" FBD_HL,FBD_HM,FBD_HR,FBD_Miko,FBD_Trunk,FBD_VL,FBD_VM,FBD_VR,IPB_App1
 SG_ ResultBLEConMonitoringFBD_MM__13 : 280|8@1+ (1.0,0) [0|252] "" FBD_HL,FBD_HM,FBD_HR,FBD_Miko,FBD_Trunk,FBD_VL,FBD_VM,FBD_VR,IPB_App1
 SG_ ResultBLEConMonitoringFBD_MM_R_8 : 288|8@1+ (1.0,0) [0|252] "dB" FBD_HL,FBD_HM,FBD_HR,FBD_Miko,FBD_Trunk,FBD_VL,FBD_VM,FBD_VR,IPB_App1
 SG_ ResultBLEConMonitoringFBD_MM_c_8 : 296|16@1+ (1.0,0) [0|65532] "" FBD_HL,FBD_HM,FBD_HR,FBD_Miko,FBD_Trunk,FBD_VL,FBD_VM,FBD_VR,IPB_App1
 SG_ ResultBLEConMonitoringFBD_MM__14 : 312|8@1+ (1.0,0) [0|252] "" FBD_HL,FBD_HM,FBD_HR,FBD_Miko,FBD_Trunk,FBD_VL,FBD_VM,FBD_VR,IPB_App1
 SG_ ResultBLEConMonitoringFBD_MM__15 : 320|8@1+ (1.0,0) [0|252] "" FBD_HL,FBD_HM,FBD_HR,FBD_Miko,FBD_Trunk,FBD_VL,FBD_VM,FBD_VR,IPB_App1
 SG_ ResultBLEConMonitoringFBD_MM_R_9 : 328|8@1+ (1.0,0) [0|252] "dB" FBD_HL,FBD_HM,FBD_HR,FBD_Miko,FBD_Trunk,FBD_VL,FBD_VM,FBD_VR,IPB_App1
 SG_ ResultBLEConMonitoringFBD_MM_c_9 : 336|16@1+ (1.0,0) [0|65532] "" FBD_HL,FBD_HM,FBD_HR,FBD_Miko,FBD_Trunk,FBD_VL,FBD_VM,FBD_VR,IPB_App1
 SG_ ResultBLEConMonitoringFBD_MM__16 : 352|8@1+ (1.0,0) [0|252] "" FBD_HL,FBD_HM,FBD_HR,FBD_Miko,FBD_Trunk,FBD_VL,FBD_VM,FBD_VR,IPB_App1
 SG_ ResultBLEConMonitoringFBD_MM__17 : 360|8@1+ (1.0,0) [0|252] "" FBD_HL,FBD_HM,FBD_HR,FBD_Miko,FBD_Trunk,FBD_VL,FBD_VM,FBD_VR,IPB_App1
 SG_ ResultBLEConMonitoringFBD_MM__18 : 368|8@1+ (1.0,0) [0|252] "dB" FBD_HL,FBD_HM,FBD_HR,FBD_Miko,FBD_Trunk,FBD_VL,FBD_VM,FBD_VR,IPB_App1
 SG_ ResultBLEConMonitoringFBD_MM__19 : 376|16@1+ (1.0,0) [0|65532] "" FBD_HL,FBD_HM,FBD_HR,FBD_Miko,FBD_Trunk,FBD_VL,FBD_VM,FBD_VR,IPB_App1
 SG_ ResultBLEConMonitoringFBD_MM__20 : 392|8@1+ (1.0,0) [0|252] "" FBD_HL,FBD_HM,FBD_HR,FBD_Miko,FBD_Trunk,FBD_VL,FBD_VM,FBD_VR,IPB_App1
 SG_ ResultBLEConMonitoringFBD_MM__21 : 400|8@1+ (1.0,0) [0|252] "" FBD_HL,FBD_HM,FBD_HR,FBD_Miko,FBD_Trunk,FBD_VL,FBD_VM,FBD_VR,IPB_App1
 SG_ ResultBLEConMonitoringFBD_MM_IV0 : 408|8@1+ (1.0,0) [0|255] "" FBD_HL,FBD_HM,FBD_HR,FBD_Miko,FBD_Trunk,FBD_VL,FBD_VM,FBD_VR,IPB_App1
 SG_ ResultBLEConMonitoringFBD_MM_I_2 : 416|8@1+ (1.0,0) [0|255] "" FBD_HL,FBD_HM,FBD_HR,FBD_Miko,FBD_Trunk,FBD_VL,FBD_VM,FBD_VR,IPB_App1
 SG_ ResultBLEConMonitoringFBD_MM_I_3 : 424|8@1+ (1.0,0) [0|255] "" FBD_HL,FBD_HM,FBD_HR,FBD_Miko,FBD_Trunk,FBD_VL,FBD_VM,FBD_VR,IPB_App1
 SG_ ResultBLEConMonitoringFBD_MM_I_4 : 432|8@1+ (1.0,0) [0|255] "" FBD_HL,FBD_HM,FBD_HR,FBD_Miko,FBD_Trunk,FBD_VL,FBD_VM,FBD_VR,IPB_App1
 SG_ ResultBLEConMonitoringFBD_MM_Sig : 440|8@1+ (1.0,0) [0|255] "" FBD_HL,FBD_HM,FBD_HR,FBD_Miko,FBD_Trunk,FBD_VL,FBD_VM,FBD_VR,IPB_App1
 SG_ ResultBLEConMonitoringFBD_MM_S_2 : 448|8@1+ (1.0,0) [0|255] "" FBD_HL,FBD_HM,FBD_HR,FBD_Miko,FBD_Trunk,FBD_VL,FBD_VM,FBD_VR,IPB_App1
 SG_ ResultBLEConMonitoringFBD_MM_S_3 : 456|8@1+ (1.0,0) [0|255] "" FBD_HL,FBD_HM,FBD_HR,FBD_Miko,FBD_Trunk,FBD_VL,FBD_VM,FBD_VR,IPB_App1
 SG_ ResultBLEConMonitoringFBD_MM_S_4 : 464|8@1+ (1.0,0) [0|255] "" FBD_HL,FBD_HM,FBD_HR,FBD_Miko,FBD_Trunk,FBD_VL,FBD_VM,FBD_VR,IPB_App1
 SG_ ResultBLEConMonitoringFBD_MM_S_5 : 472|8@1+ (1.0,0) [0|255] "" FBD_HL,FBD_HM,FBD_HR,FBD_Miko,FBD_Trunk,FBD_VL,FBD_VM,FBD_VR,IPB_App1
 SG_ ResultBLEConMonitoringFBD_MM_S_6 : 480|8@1+ (1.0,0) [0|255] "" FBD_HL,FBD_HM,FBD_HR,FBD_Miko,FBD_Trunk,FBD_VL,FBD_VM,FBD_VR,IPB_App1
 SG_ ResultBLEConMonitoringFBD_MM_S_7 : 488|8@1+ (1.0,0) [0|255] "" FBD_HL,FBD_HM,FBD_HR,FBD_Miko,FBD_Trunk,FBD_VL,FBD_VM,FBD_VR,IPB_App1
 SG_ ResultBLEConMonitoringFBD_MM_S_8 : 496|8@1+ (1.0,0) [0|255] "" FBD_HL,FBD_HM,FBD_HR,FBD_Miko,FBD_Trunk,FBD_VL,FBD_VM,FBD_VR,IPB_App1

BO_ 293 ResultBLEConMonitoringFBD_Trunk: 64 FBD_Trunk
 SG_ ResultBLEConMonitoringFBD_Trunk_ : 0|8@1+ (1.0,0) [0|252] "" FBD_HL,FBD_HM,FBD_HR,FBD_MM,FBD_Miko,FBD_VL,FBD_VM,FBD_VR,IPB_App1
 SG_ ResultBLEConMonitoringFBD_Trun_2 : 8|8@1+ (1.0,0) [0|252] "dB" FBD_HL,FBD_HM,FBD_HR,FBD_MM,FBD_Miko,FBD_VL,FBD_VM,FBD_VR,IPB_App1
 SG_ ResultBLEConMonitoringFBD_Trun_3 : 16|16@1+ (1.0,0) [0|65532] "" FBD_HL,FBD_HM,FBD_HR,FBD_MM,FBD_Miko,FBD_VL,FBD_VM,FBD_VR,IPB_App1
 SG_ ResultBLEConMonitoringFBD_Trun_4 : 32|8@1+ (1.0,0) [0|252] "" FBD_HL,FBD_HM,FBD_HR,FBD_MM,FBD_Miko,FBD_VL,FBD_VM,FBD_VR,IPB_App1
 SG_ ResultBLEConMonitoringFBD_Tunk_D : 40|8@1+ (1.0,0) [0|252] "" FBD_HL,FBD_HM,FBD_HR,FBD_MM,FBD_Miko,FBD_VL,FBD_VM,FBD_VR,IPB_App1
 SG_ ResultBLEConMonitoringFBD_Trun_5 : 48|8@1+ (1.0,0) [0|252] "dB" FBD_HL,FBD_HM,FBD_HR,FBD_MM,FBD_Miko,FBD_VL,FBD_VM,FBD_VR,IPB_App1
 SG_ ResultBLEConMonitoringFBD_Trun_6 : 56|16@1+ (1.0,0) [0|65532] "" FBD_HL,FBD_HM,FBD_HR,FBD_MM,FBD_Miko,FBD_VL,FBD_VM,FBD_VR,IPB_App1
 SG_ ResultBLEConMonitoringFBD_Trun_7 : 72|8@1+ (1.0,0) [0|252] "" FBD_HL,FBD_HM,FBD_HR,FBD_MM,FBD_Miko,FBD_VL,FBD_VM,FBD_VR,IPB_App1
 SG_ ResultBLEConMonitoringFBD_Trun_8 : 80|8@1+ (1.0,0) [0|252] "" FBD_HL,FBD_HM,FBD_HR,FBD_MM,FBD_Miko,FBD_VL,FBD_VM,FBD_VR,IPB_App1
 SG_ ResultBLEConMonitoringFBD_Trun_9 : 88|8@1+ (1.0,0) [0|252] "dB" FBD_HL,FBD_HM,FBD_HR,FBD_MM,FBD_Miko,FBD_VL,FBD_VM,FBD_VR,IPB_App1
 SG_ ResultBLEConMonitoringFBD_Tru_10 : 96|16@1+ (1.0,0) [0|65532] "" FBD_HL,FBD_HM,FBD_HR,FBD_MM,FBD_Miko,FBD_VL,FBD_VM,FBD_VR,IPB_App1
 SG_ ResultBLEConMonitoringFBD_Tru_11 : 112|8@1+ (1.0,0) [0|252] "" FBD_HL,FBD_HM,FBD_HR,FBD_MM,FBD_Miko,FBD_VL,FBD_VM,FBD_VR,IPB_App1
 SG_ ResultBLEConMonitoringFBD_Tru_12 : 120|8@1+ (1.0,0) [0|252] "" FBD_HL,FBD_HM,FBD_HR,FBD_MM,FBD_Miko,FBD_VL,FBD_VM,FBD_VR,IPB_App1
 SG_ ResultBLEConMonitoringFBD_Tru_13 : 128|8@1+ (1.0,0) [0|252] "dB" FBD_HL,FBD_HM,FBD_HR,FBD_MM,FBD_Miko,FBD_VL,FBD_VM,FBD_VR,IPB_App1
 SG_ ResultBLEConMonitoringFBD_Tru_14 : 136|16@1+ (1.0,0) [0|65532] "" FBD_HL,FBD_HM,FBD_HR,FBD_MM,FBD_Miko,FBD_VL,FBD_VM,FBD_VR,IPB_App1
 SG_ ResultBLEConMonitoringFBD_Tru_15 : 152|8@1+ (1.0,0) [0|252] "" FBD_HL,FBD_HM,FBD_HR,FBD_MM,FBD_Miko,FBD_VL,FBD_VM,FBD_VR,IPB_App1
 SG_ ResultBLEConMonitoringFBD_Tru_16 : 160|8@1+ (1.0,0) [0|252] "" FBD_HL,FBD_HM,FBD_HR,FBD_MM,FBD_Miko,FBD_VL,FBD_VM,FBD_VR,IPB_App1
 SG_ ResultBLEConMonitoringFBD_Tru_17 : 168|8@1+ (1.0,0) [0|252] "dB" FBD_HL,FBD_HM,FBD_HR,FBD_MM,FBD_Miko,FBD_VL,FBD_VM,FBD_VR,IPB_App1
 SG_ ResultBLEConMonitoringFBD_Tru_18 : 176|16@1+ (1.0,0) [0|65532] "" FBD_HL,FBD_HM,FBD_HR,FBD_MM,FBD_Miko,FBD_VL,FBD_VM,FBD_VR,IPB_App1
 SG_ ResultBLEConMonitoringFBD_Tru_19 : 192|8@1+ (1.0,0) [0|252] "" FBD_HL,FBD_HM,FBD_HR,FBD_MM,FBD_Miko,FBD_VL,FBD_VM,FBD_VR,IPB_App1
 SG_ ResultBLEConMonitoringFBD_Tru_20 : 200|8@1+ (1.0,0) [0|252] "" FBD_HL,FBD_HM,FBD_HR,FBD_MM,FBD_Miko,FBD_VL,FBD_VM,FBD_VR,IPB_App1
 SG_ ResultBLEConMonitoringFBD_Tru_21 : 208|8@1+ (1.0,0) [0|252] "dB" FBD_HL,FBD_HM,FBD_HR,FBD_MM,FBD_Miko,FBD_VL,FBD_VM,FBD_VR,IPB_App1
 SG_ ResultBLEConMonitoringFBD_Tru_22 : 216|16@1+ (1.0,0) [0|65532] "" FBD_HL,FBD_HM,FBD_HR,FBD_MM,FBD_Miko,FBD_VL,FBD_VM,FBD_VR,IPB_App1
 SG_ ResultBLEConMonitoringFBD_Tru_23 : 232|8@1+ (1.0,0) [0|252] "" FBD_HL,FBD_HM,FBD_HR,FBD_MM,FBD_Miko,FBD_VL,FBD_VM,FBD_VR,IPB_App1
 SG_ ResultBLEConMonitoringFBD_Tru_24 : 240|8@1+ (1.0,0) [0|252] "" FBD_HL,FBD_HM,FBD_HR,FBD_MM,FBD_Miko,FBD_VL,FBD_VM,FBD_VR,IPB_App1
 SG_ ResultBLEConMonitoringFBD_Tru_25 : 248|8@1+ (1.0,0) [0|252] "dB" FBD_HL,FBD_HM,FBD_HR,FBD_MM,FBD_Miko,FBD_VL,FBD_VM,FBD_VR,IPB_App1
 SG_ ResultBLEConMonitoringFBD_Tru_26 : 256|16@1+ (1.0,0) [0|65532] "" FBD_HL,FBD_HM,FBD_HR,FBD_MM,FBD_Miko,FBD_VL,FBD_VM,FBD_VR,IPB_App1
 SG_ ResultBLEConMonitoringFBD_Tru_27 : 272|8@1+ (1.0,0) [0|252] "" FBD_HL,FBD_HM,FBD_HR,FBD_MM,FBD_Miko,FBD_VL,FBD_VM,FBD_VR,IPB_App1
 SG_ ResultBLEConMonitoringFBD_Tru_28 : 280|8@1+ (1.0,0) [0|252] "" FBD_HL,FBD_HM,FBD_HR,FBD_MM,FBD_Miko,FBD_VL,FBD_VM,FBD_VR,IPB_App1
 SG_ ResultBLEConMonitoringFBD_Tru_29 : 288|8@1+ (1.0,0) [0|252] "dB" FBD_HL,FBD_HM,FBD_HR,FBD_MM,FBD_Miko,FBD_VL,FBD_VM,FBD_VR,IPB_App1
 SG_ ResultBLEConMonitoringFBD_Tru_30 : 296|16@1+ (1.0,0) [0|65532] "" FBD_HL,FBD_HM,FBD_HR,FBD_MM,FBD_Miko,FBD_VL,FBD_VM,FBD_VR,IPB_App1
 SG_ ResultBLEConMonitoringFBD_Tru_31 : 312|8@1+ (1.0,0) [0|252] "" FBD_HL,FBD_HM,FBD_HR,FBD_MM,FBD_Miko,FBD_VL,FBD_VM,FBD_VR,IPB_App1
 SG_ ResultBLEConMonitoringFBD_Tru_32 : 320|8@1+ (1.0,0) [0|252] "" FBD_HL,FBD_HM,FBD_HR,FBD_MM,FBD_Miko,FBD_VL,FBD_VM,FBD_VR,IPB_App1
 SG_ ResultBLEConMonitoringFBD_Tru_33 : 328|8@1+ (1.0,0) [0|252] "dB" FBD_HL,FBD_HM,FBD_HR,FBD_MM,FBD_Miko,FBD_VL,FBD_VM,FBD_VR,IPB_App1
 SG_ ResultBLEConMonitoringFBD_Tru_34 : 336|16@1+ (1.0,0) [0|65532] "" FBD_HL,FBD_HM,FBD_HR,FBD_MM,FBD_Miko,FBD_VL,FBD_VM,FBD_VR,IPB_App1
 SG_ ResultBLEConMonitoringFBD_Tru_35 : 352|8@1+ (1.0,0) [0|252] "" FBD_HL,FBD_HM,FBD_HR,FBD_MM,FBD_Miko,FBD_VL,FBD_VM,FBD_VR,IPB_App1
 SG_ ResultBLEConMonitoringFBD_Tru_36 : 360|8@1+ (1.0,0) [0|252] "" FBD_HL,FBD_HM,FBD_HR,FBD_MM,FBD_Miko,FBD_VL,FBD_VM,FBD_VR,IPB_App1
 SG_ ResultBLEConMonitoringFBD_Tru_37 : 368|8@1+ (1.0,0) [0|252] "dB" FBD_HL,FBD_HM,FBD_HR,FBD_MM,FBD_Miko,FBD_VL,FBD_VM,FBD_VR,IPB_App1
 SG_ ResultBLEConMonitoringFBD_Tru_38 : 376|16@1+ (1.0,0) [0|65532] "" FBD_HL,FBD_HM,FBD_HR,FBD_MM,FBD_Miko,FBD_VL,FBD_VM,FBD_VR,IPB_App1
 SG_ ResultBLEConMonitoringFBD_Tru_39 : 392|8@1+ (1.0,0) [0|252] "" FBD_HL,FBD_HM,FBD_HR,FBD_MM,FBD_Miko,FBD_VL,FBD_VM,FBD_VR,IPB_App1
 SG_ ResultBLEConMonitoringFBD_Tru_40 : 400|8@1+ (1.0,0) [0|252] "" FBD_HL,FBD_HM,FBD_HR,FBD_MM,FBD_Miko,FBD_VL,FBD_VM,FBD_VR,IPB_App1
 SG_ ResultBLEConMonitoringFBD_Tru_41 : 408|8@1+ (1.0,0) [0|255] "" FBD_HL,FBD_HM,FBD_HR,FBD_MM,FBD_Miko,FBD_VL,FBD_VM,FBD_VR,IPB_App1
 SG_ ResultBLEConMonitoringFBD_Tru_42 : 416|8@1+ (1.0,0) [0|255] "" FBD_HL,FBD_HM,FBD_HR,FBD_MM,FBD_Miko,FBD_VL,FBD_VM,FBD_VR,IPB_App1
 SG_ ResultBLEConMonitoringFBD_Tru_43 : 424|8@1+ (1.0,0) [0|255] "" FBD_HL,FBD_HM,FBD_HR,FBD_MM,FBD_Miko,FBD_VL,FBD_VM,FBD_VR,IPB_App1
 SG_ ResultBLEConMonitoringFBD_Tru_44 : 432|8@1+ (1.0,0) [0|255] "" FBD_HL,FBD_HM,FBD_HR,FBD_MM,FBD_Miko,FBD_VL,FBD_VM,FBD_VR,IPB_App1
 SG_ ResultBLEConMonitoringFBD_Tru_45 : 440|8@1+ (1.0,0) [0|255] "" FBD_HL,FBD_HM,FBD_HR,FBD_MM,FBD_Miko,FBD_VL,FBD_VM,FBD_VR,IPB_App1
 SG_ ResultBLEConMonitoringFBD_Tru_46 : 448|8@1+ (1.0,0) [0|255] "" FBD_HL,FBD_HM,FBD_HR,FBD_MM,FBD_Miko,FBD_VL,FBD_VM,FBD_VR,IPB_App1
 SG_ ResultBLEConMonitoringFBD_Tru_47 : 456|8@1+ (1.0,0) [0|255] "" FBD_HL,FBD_HM,FBD_HR,FBD_MM,FBD_Miko,FBD_VL,FBD_VM,FBD_VR,IPB_App1
 SG_ ResultBLEConMonitoringFBD_Tru_48 : 464|8@1+ (1.0,0) [0|255] "" FBD_HL,FBD_HM,FBD_HR,FBD_MM,FBD_Miko,FBD_VL,FBD_VM,FBD_VR,IPB_App1
 SG_ ResultBLEConMonitoringFBD_Tru_49 : 472|8@1+ (1.0,0) [0|255] "" FBD_HL,FBD_HM,FBD_HR,FBD_MM,FBD_Miko,FBD_VL,FBD_VM,FBD_VR,IPB_App1
 SG_ ResultBLEConMonitoringFBD_Tru_50 : 480|8@1+ (1.0,0) [0|255] "" FBD_HL,FBD_HM,FBD_HR,FBD_MM,FBD_Miko,FBD_VL,FBD_VM,FBD_VR,IPB_App1
 SG_ ResultBLEConMonitoringFBD_Tru_51 : 488|8@1+ (1.0,0) [0|255] "" FBD_HL,FBD_HM,FBD_HR,FBD_MM,FBD_Miko,FBD_VL,FBD_VM,FBD_VR,IPB_App1
 SG_ ResultBLEConMonitoringFBD_Tru_52 : 496|8@1+ (1.0,0) [0|255] "" FBD_HL,FBD_HM,FBD_HR,FBD_MM,FBD_Miko,FBD_VL,FBD_VM,FBD_VR,IPB_App1

BO_ 294 ResultBLEConMonitoringFBD_VL: 64 FBD_VL
 SG_ ResultBLEConMonitoringFBD_VL_IRK : 0|8@1+ (1.0,0) [0|252] "" FBD_HL,FBD_HM,FBD_HR,FBD_MM,FBD_Miko,FBD_Trunk,FBD_VM,FBD_VR,IPB_App1
 SG_ ResultBLEConMonitoringFBD_VL_RSS : 8|8@1+ (1.0,0) [0|252] "dB" FBD_HL,FBD_HM,FBD_HR,FBD_MM,FBD_Miko,FBD_Trunk,FBD_VM,FBD_VR,IPB_App1
 SG_ ResultBLEConMonitoringFBD_VL_con : 16|16@1+ (1.0,0) [0|65532] "" FBD_HL,FBD_HM,FBD_HR,FBD_MM,FBD_Miko,FBD_Trunk,FBD_VM,FBD_VR,IPB_App1
 SG_ ResultBLEConMonitoringFBD_VL_Ch_ : 32|8@1+ (1.0,0) [0|252] "" FBD_HL,FBD_HM,FBD_HR,FBD_MM,FBD_Miko,FBD_Trunk,FBD_VM,FBD_VR,IPB_App1
 SG_ ResultBLEConMonitoringFBD_VL_Dev : 40|8@1+ (1.0,0) [0|252] "" FBD_HL,FBD_HM,FBD_HR,FBD_MM,FBD_Miko,FBD_Trunk,FBD_VM,FBD_VR,IPB_App1
 SG_ ResultBLEConMonitoringFBD_VL_R_2 : 48|8@1+ (1.0,0) [0|252] "dB" FBD_HL,FBD_HM,FBD_HR,FBD_MM,FBD_Miko,FBD_Trunk,FBD_VM,FBD_VR,IPB_App1
 SG_ ResultBLEConMonitoringFBD_VL_c_2 : 56|16@1+ (1.0,0) [0|65532] "" FBD_HL,FBD_HM,FBD_HR,FBD_MM,FBD_Miko,FBD_Trunk,FBD_VM,FBD_VR,IPB_App1
 SG_ ResultBLEConMonitoringFBD_VL_C_2 : 72|8@1+ (1.0,0) [0|252] "" FBD_HL,FBD_HM,FBD_HR,FBD_MM,FBD_Miko,FBD_Trunk,FBD_VM,FBD_VR,IPB_App1
 SG_ ResultBLEConMonitoringFBD_VL_C_3 : 80|8@1+ (1.0,0) [0|252] "" FBD_HL,FBD_HM,FBD_HR,FBD_MM,FBD_Miko,FBD_Trunk,FBD_VM,FBD_VR,IPB_App1
 SG_ ResultBLEConMonitoringFBD_VL_R_3 : 88|8@1+ (1.0,0) [0|252] "dB" FBD_HL,FBD_HM,FBD_HR,FBD_MM,FBD_Miko,FBD_Trunk,FBD_VM,FBD_VR,IPB_App1
 SG_ ResultBLEConMonitoringFBD_VL_c_3 : 96|16@1+ (1.0,0) [0|65532] "" FBD_HL,FBD_HM,FBD_HR,FBD_MM,FBD_Miko,FBD_Trunk,FBD_VM,FBD_VR,IPB_App1
 SG_ ResultBLEConMonitoringFBD_VL_C_4 : 112|8@1+ (1.0,0) [0|252] "" FBD_HL,FBD_HM,FBD_HR,FBD_MM,FBD_Miko,FBD_Trunk,FBD_VM,FBD_VR,IPB_App1
 SG_ ResultBLEConMonitoringFBD_VL_C_5 : 120|8@1+ (1.0,0) [0|252] "" FBD_HL,FBD_HM,FBD_HR,FBD_MM,FBD_Miko,FBD_Trunk,FBD_VM,FBD_VR,IPB_App1
 SG_ ResultBLEConMonitoringFBD_VL_R_4 : 128|8@1+ (1.0,0) [0|252] "dB" FBD_HL,FBD_HM,FBD_HR,FBD_MM,FBD_Miko,FBD_Trunk,FBD_VM,FBD_VR,IPB_App1
 SG_ ResultBLEConMonitoringFBD_VL_c_4 : 136|16@1+ (1.0,0) [0|65532] "" FBD_HL,FBD_HM,FBD_HR,FBD_MM,FBD_Miko,FBD_Trunk,FBD_VM,FBD_VR,IPB_App1
 SG_ ResultBLEConMonitoringFBD_VL_C_6 : 152|8@1+ (1.0,0) [0|252] "" FBD_HL,FBD_HM,FBD_HR,FBD_MM,FBD_Miko,FBD_Trunk,FBD_VM,FBD_VR,IPB_App1
 SG_ ResultBLEConMonitoringFBD_VL_C_7 : 160|8@1+ (1.0,0) [0|252] "" FBD_HL,FBD_HM,FBD_HR,FBD_MM,FBD_Miko,FBD_Trunk,FBD_VM,FBD_VR,IPB_App1
 SG_ ResultBLEConMonitoringFBD_VL_R_5 : 168|8@1+ (1.0,0) [0|252] "dB" FBD_HL,FBD_HM,FBD_HR,FBD_MM,FBD_Miko,FBD_Trunk,FBD_VM,FBD_VR,IPB_App1
 SG_ ResultBLEConMonitoringFBD_VL_c_5 : 176|16@1+ (1.0,0) [0|65532] "" FBD_HL,FBD_HM,FBD_HR,FBD_MM,FBD_Miko,FBD_Trunk,FBD_VM,FBD_VR,IPB_App1
 SG_ ResultBLEConMonitoringFBD_VL_C_8 : 192|8@1+ (1.0,0) [0|252] "" FBD_HL,FBD_HM,FBD_HR,FBD_MM,FBD_Miko,FBD_Trunk,FBD_VM,FBD_VR,IPB_App1
 SG_ ResultBLEConMonitoringFBD_VL_C_9 : 200|8@1+ (1.0,0) [0|252] "" FBD_HL,FBD_HM,FBD_HR,FBD_MM,FBD_Miko,FBD_Trunk,FBD_VM,FBD_VR,IPB_App1
 SG_ ResultBLEConMonitoringFBD_VL_R_6 : 208|8@1+ (1.0,0) [0|252] "dB" FBD_HL,FBD_HM,FBD_HR,FBD_MM,FBD_Miko,FBD_Trunk,FBD_VM,FBD_VR,IPB_App1
 SG_ ResultBLEConMonitoringFBD_VL_c_6 : 216|16@1+ (1.0,0) [0|65532] "" FBD_HL,FBD_HM,FBD_HR,FBD_MM,FBD_Miko,FBD_Trunk,FBD_VM,FBD_VR,IPB_App1
 SG_ ResultBLEConMonitoringFBD_VL__10 : 232|8@1+ (1.0,0) [0|252] "" FBD_HL,FBD_HM,FBD_HR,FBD_MM,FBD_Miko,FBD_Trunk,FBD_VM,FBD_VR,IPB_App1
 SG_ ResultBLEConMonitoringFBD_VL__11 : 240|8@1+ (1.0,0) [0|252] "" FBD_HL,FBD_HM,FBD_HR,FBD_MM,FBD_Miko,FBD_Trunk,FBD_VM,FBD_VR,IPB_App1
 SG_ ResultBLEConMonitoringFBD_VL_R_7 : 248|8@1+ (1.0,0) [0|252] "dB" FBD_HL,FBD_HM,FBD_HR,FBD_MM,FBD_Miko,FBD_Trunk,FBD_VM,FBD_VR,IPB_App1
 SG_ ResultBLEConMonitoringFBD_VL_c_7 : 256|16@1+ (1.0,0) [0|65532] "" FBD_HL,FBD_HM,FBD_HR,FBD_MM,FBD_Miko,FBD_Trunk,FBD_VM,FBD_VR,IPB_App1
 SG_ ResultBLEConMonitoringFBD_VL__12 : 272|8@1+ (1.0,0) [0|252] "" FBD_HL,FBD_HM,FBD_HR,FBD_MM,FBD_Miko,FBD_Trunk,FBD_VM,FBD_VR,IPB_App1
 SG_ ResultBLEConMonitoringFBD_VL__13 : 280|8@1+ (1.0,0) [0|252] "" FBD_HL,FBD_HM,FBD_HR,FBD_MM,FBD_Miko,FBD_Trunk,FBD_VM,FBD_VR,IPB_App1
 SG_ ResultBLEConMonitoringFBD_VL_R_8 : 288|8@1+ (1.0,0) [0|252] "dB" FBD_HL,FBD_HM,FBD_HR,FBD_MM,FBD_Miko,FBD_Trunk,FBD_VM,FBD_VR,IPB_App1
 SG_ ResultBLEConMonitoringFBD_VL_c_8 : 296|16@1+ (1.0,0) [0|65532] "" FBD_HL,FBD_HM,FBD_HR,FBD_MM,FBD_Miko,FBD_Trunk,FBD_VM,FBD_VR,IPB_App1
 SG_ ResultBLEConMonitoringFBD_VL__14 : 312|8@1+ (1.0,0) [0|252] "" FBD_HL,FBD_HM,FBD_HR,FBD_MM,FBD_Miko,FBD_Trunk,FBD_VM,FBD_VR,IPB_App1
 SG_ ResultBLEConMonitoringFBD_VL__15 : 320|8@1+ (1.0,0) [0|252] "" FBD_HL,FBD_HM,FBD_HR,FBD_MM,FBD_Miko,FBD_Trunk,FBD_VM,FBD_VR,IPB_App1
 SG_ ResultBLEConMonitoringFBD_VL_R_9 : 328|8@1+ (1.0,0) [0|252] "dB" FBD_HL,FBD_HM,FBD_HR,FBD_MM,FBD_Miko,FBD_Trunk,FBD_VM,FBD_VR,IPB_App1
 SG_ ResultBLEConMonitoringFBD_VL_c_9 : 336|16@1+ (1.0,0) [0|65532] "" FBD_HL,FBD_HM,FBD_HR,FBD_MM,FBD_Miko,FBD_Trunk,FBD_VM,FBD_VR,IPB_App1
 SG_ ResultBLEConMonitoringFBD_VL__16 : 352|8@1+ (1.0,0) [0|252] "" FBD_HL,FBD_HM,FBD_HR,FBD_MM,FBD_Miko,FBD_Trunk,FBD_VM,FBD_VR,IPB_App1
 SG_ ResultBLEConMonitoringFBD_VL__17 : 360|8@1+ (1.0,0) [0|252] "" FBD_HL,FBD_HM,FBD_HR,FBD_MM,FBD_Miko,FBD_Trunk,FBD_VM,FBD_VR,IPB_App1
 SG_ ResultBLEConMonitoringFBD_VL__18 : 368|8@1+ (1.0,0) [0|252] "dB" FBD_HL,FBD_HM,FBD_HR,FBD_MM,FBD_Miko,FBD_Trunk,FBD_VM,FBD_VR,IPB_App1
 SG_ ResultBLEConMonitoringFBD_VL__19 : 376|16@1+ (1.0,0) [0|65532] "" FBD_HL,FBD_HM,FBD_HR,FBD_MM,FBD_Miko,FBD_Trunk,FBD_VM,FBD_VR,IPB_App1
 SG_ ResultBLEConMonitoringFBD_VL__20 : 392|8@1+ (1.0,0) [0|252] "" FBD_HL,FBD_HM,FBD_HR,FBD_MM,FBD_Miko,FBD_Trunk,FBD_VM,FBD_VR,IPB_App1
 SG_ ResultBLEConMonitoringFBD_VL__21 : 400|8@1+ (1.0,0) [0|252] "" FBD_HL,FBD_HM,FBD_HR,FBD_MM,FBD_Miko,FBD_Trunk,FBD_VM,FBD_VR,IPB_App1
 SG_ ResultBLEConMonitoringFBD_VL_IV0 : 408|8@1+ (1.0,0) [0|255] "" FBD_HL,FBD_HM,FBD_HR,FBD_MM,FBD_Miko,FBD_Trunk,FBD_VM,FBD_VR,IPB_App1
 SG_ ResultBLEConMonitoringFBD_VL_I_2 : 416|8@1+ (1.0,0) [0|255] "" FBD_HL,FBD_HM,FBD_HR,FBD_MM,FBD_Miko,FBD_Trunk,FBD_VM,FBD_VR,IPB_App1
 SG_ ResultBLEConMonitoringFBD_VL_I_3 : 424|8@1+ (1.0,0) [0|255] "" FBD_HL,FBD_HM,FBD_HR,FBD_MM,FBD_Miko,FBD_Trunk,FBD_VM,FBD_VR,IPB_App1
 SG_ ResultBLEConMonitoringFBD_VL_I_4 : 432|8@1+ (1.0,0) [0|255] "" FBD_HL,FBD_HM,FBD_HR,FBD_MM,FBD_Miko,FBD_Trunk,FBD_VM,FBD_VR,IPB_App1
 SG_ ResultBLEConMonitoringFBD_VL_Sig : 440|8@1+ (1.0,0) [0|255] "" FBD_HL,FBD_HM,FBD_HR,FBD_MM,FBD_Miko,FBD_Trunk,FBD_VM,FBD_VR,IPB_App1
 SG_ ResultBLEConMonitoringFBD_VL_S_2 : 448|8@1+ (1.0,0) [0|255] "" FBD_HL,FBD_HM,FBD_HR,FBD_MM,FBD_Miko,FBD_Trunk,FBD_VM,FBD_VR,IPB_App1
 SG_ ResultBLEConMonitoringFBD_VL_S_3 : 456|8@1+ (1.0,0) [0|255] "" FBD_HL,FBD_HM,FBD_HR,FBD_MM,FBD_Miko,FBD_Trunk,FBD_VM,FBD_VR,IPB_App1
 SG_ ResultBLEConMonitoringFBD_VL_S_4 : 464|8@1+ (1.0,0) [0|255] "" FBD_HL,FBD_HM,FBD_HR,FBD_MM,FBD_Miko,FBD_Trunk,FBD_VM,FBD_VR,IPB_App1
 SG_ ResultBLEConMonitoringFBD_VL_S_5 : 472|8@1+ (1.0,0) [0|255] "" FBD_HL,FBD_HM,FBD_HR,FBD_MM,FBD_Miko,FBD_Trunk,FBD_VM,FBD_VR,IPB_App1
 SG_ ResultBLEConMonitoringFBD_VL_S_6 : 480|8@1+ (1.0,0) [0|255] "" FBD_HL,FBD_HM,FBD_HR,FBD_MM,FBD_Miko,FBD_Trunk,FBD_VM,FBD_VR,IPB_App1
 SG_ ResultBLEConMonitoringFBD_VL_S_7 : 488|8@1+ (1.0,0) [0|255] "" FBD_HL,FBD_HM,FBD_HR,FBD_MM,FBD_Miko,FBD_Trunk,FBD_VM,FBD_VR,IPB_App1
 SG_ ResultBLEConMonitoringFBD_VL_S_8 : 496|8@1+ (1.0,0) [0|255] "" FBD_HL,FBD_HM,FBD_HR,FBD_MM,FBD_Miko,FBD_Trunk,FBD_VM,FBD_VR,IPB_App1

BO_ 290 ResultBLEConMonitoringFBD_VM: 64 FBD_VM
 SG_ ResultBLEConMonitoringFBD_VM_IRK : 0|8@1+ (1.0,0) [0|252] "" FBD_HL,FBD_HM,FBD_HR,FBD_MM,FBD_Miko,FBD_Trunk,FBD_VL,FBD_VR,IPB_App1
 SG_ ResultBLEConMonitoringFBD_VM_RSS : 8|8@1+ (1.0,0) [0|252] "dB" FBD_HL,FBD_HM,FBD_HR,FBD_MM,FBD_Miko,FBD_Trunk,FBD_VL,FBD_VR,IPB_App1
 SG_ ResultBLEConMonitoringFBD_VM_con : 16|16@1+ (1.0,0) [0|65532] "" FBD_HL,FBD_HM,FBD_HR,FBD_MM,FBD_Miko,FBD_Trunk,FBD_VL,FBD_VR,IPB_App1
 SG_ ResultBLEConMonitoringFBD_VM_Ch_ : 32|8@1+ (1.0,0) [0|252] "" FBD_HL,FBD_HM,FBD_HR,FBD_MM,FBD_Miko,FBD_Trunk,FBD_VL,FBD_VR,IPB_App1
 SG_ ResultBLEConMonitoringFBD_VM_Dev : 40|8@1+ (1.0,0) [0|252] "" FBD_HL,FBD_HM,FBD_HR,FBD_MM,FBD_Miko,FBD_Trunk,FBD_VL,FBD_VR,IPB_App1
 SG_ ResultBLEConMonitoringFBD_VM_R_2 : 48|8@1+ (1.0,0) [0|252] "dB" FBD_HL,FBD_HM,FBD_HR,FBD_MM,FBD_Miko,FBD_Trunk,FBD_VL,FBD_VR,IPB_App1
 SG_ ResultBLEConMonitoringFBD_VM_c_2 : 56|16@1+ (1.0,0) [0|65532] "" FBD_HL,FBD_HM,FBD_HR,FBD_MM,FBD_Miko,FBD_Trunk,FBD_VL,FBD_VR,IPB_App1
 SG_ ResultBLEConMonitoringFBD_VM_C_2 : 72|8@1+ (1.0,0) [0|252] "" FBD_HL,FBD_HM,FBD_HR,FBD_MM,FBD_Miko,FBD_Trunk,FBD_VL,FBD_VR,IPB_App1
 SG_ ResultBLEConMonitoringFBD_VM_C_3 : 80|8@1+ (1.0,0) [0|252] "" FBD_HL,FBD_HM,FBD_HR,FBD_MM,FBD_Miko,FBD_Trunk,FBD_VL,FBD_VR,IPB_App1
 SG_ ResultBLEConMonitoringFBD_VM_R_3 : 88|8@1+ (1.0,0) [0|252] "dB" FBD_HL,FBD_HM,FBD_HR,FBD_MM,FBD_Miko,FBD_Trunk,FBD_VL,FBD_VR,IPB_App1
 SG_ ResultBLEConMonitoringFBD_VM_c_3 : 96|16@1+ (1.0,0) [0|65532] "" FBD_HL,FBD_HM,FBD_HR,FBD_MM,FBD_Miko,FBD_Trunk,FBD_VL,FBD_VR,IPB_App1
 SG_ ResultBLEConMonitoringFBD_VM_C_4 : 112|8@1+ (1.0,0) [0|252] "" FBD_HL,FBD_HM,FBD_HR,FBD_MM,FBD_Miko,FBD_Trunk,FBD_VL,FBD_VR,IPB_App1
 SG_ ResultBLEConMonitoringFBD_VM_C_5 : 120|8@1+ (1.0,0) [0|252] "" FBD_HL,FBD_HM,FBD_HR,FBD_MM,FBD_Miko,FBD_Trunk,FBD_VL,FBD_VR,IPB_App1
 SG_ ResultBLEConMonitoringFBD_VM_R_4 : 128|8@1+ (1.0,0) [0|252] "dB" FBD_HL,FBD_HM,FBD_HR,FBD_MM,FBD_Miko,FBD_Trunk,FBD_VL,FBD_VR,IPB_App1
 SG_ ResultBLEConMonitoringFBD_VM_c_4 : 136|16@1+ (1.0,0) [0|65532] "" FBD_HL,FBD_HM,FBD_HR,FBD_MM,FBD_Miko,FBD_Trunk,FBD_VL,FBD_VR,IPB_App1
 SG_ ResultBLEConMonitoringFBD_VM_C_6 : 152|8@1+ (1.0,0) [0|252] "" FBD_HL,FBD_HM,FBD_HR,FBD_MM,FBD_Miko,FBD_Trunk,FBD_VL,FBD_VR,IPB_App1
 SG_ ResultBLEConMonitoringFBD_VM_C_7 : 160|8@1+ (1.0,0) [0|252] "" FBD_HL,FBD_HM,FBD_HR,FBD_MM,FBD_Miko,FBD_Trunk,FBD_VL,FBD_VR,IPB_App1
 SG_ ResultBLEConMonitoringFBD_VM_R_5 : 168|8@1+ (1.0,0) [0|252] "dB" FBD_HL,FBD_HM,FBD_HR,FBD_MM,FBD_Miko,FBD_Trunk,FBD_VL,FBD_VR,IPB_App1
 SG_ ResultBLEConMonitoringFBD_VM_c_5 : 176|16@1+ (1.0,0) [0|65532] "" FBD_HL,FBD_HM,FBD_HR,FBD_MM,FBD_Miko,FBD_Trunk,FBD_VL,FBD_VR,IPB_App1
 SG_ ResultBLEConMonitoringFBD_VM_C_8 : 192|8@1+ (1.0,0) [0|252] "" FBD_HL,FBD_HM,FBD_HR,FBD_MM,FBD_Miko,FBD_Trunk,FBD_VL,FBD_VR,IPB_App1
 SG_ ResultBLEConMonitoringFBD_VM_C_9 : 200|8@1+ (1.0,0) [0|252] "" FBD_HL,FBD_HM,FBD_HR,FBD_MM,FBD_Miko,FBD_Trunk,FBD_VL,FBD_VR,IPB_App1
 SG_ ResultBLEConMonitoringFBD_VM_R_6 : 208|8@1+ (1.0,0) [0|252] "dB" FBD_HL,FBD_HM,FBD_HR,FBD_MM,FBD_Miko,FBD_Trunk,FBD_VL,FBD_VR,IPB_App1
 SG_ ResultBLEConMonitoringFBD_VM_c_6 : 216|16@1+ (1.0,0) [0|65532] "" FBD_HL,FBD_HM,FBD_HR,FBD_MM,FBD_Miko,FBD_Trunk,FBD_VL,FBD_VR,IPB_App1
 SG_ ResultBLEConMonitoringFBD_VM__10 : 232|8@1+ (1.0,0) [0|252] "" FBD_HL,FBD_HM,FBD_HR,FBD_MM,FBD_Miko,FBD_Trunk,FBD_VL,FBD_VR,IPB_App1
 SG_ ResultBLEConMonitoringFBD_VM__11 : 240|8@1+ (1.0,0) [0|252] "" FBD_HL,FBD_HM,FBD_HR,FBD_MM,FBD_Miko,FBD_Trunk,FBD_VL,FBD_VR,IPB_App1
 SG_ ResultBLEConMonitoringFBD_VM_R_7 : 248|8@1+ (1.0,0) [0|252] "dB" FBD_HL,FBD_HM,FBD_HR,FBD_MM,FBD_Miko,FBD_Trunk,FBD_VL,FBD_VR,IPB_App1
 SG_ ResultBLEConMonitoringFBD_VM_c_7 : 256|16@1+ (1.0,0) [0|65532] "" FBD_HL,FBD_HM,FBD_HR,FBD_MM,FBD_Miko,FBD_Trunk,FBD_VL,FBD_VR,IPB_App1
 SG_ ResultBLEConMonitoringFBD_VM__12 : 272|8@1+ (1.0,0) [0|252] "" FBD_HL,FBD_HM,FBD_HR,FBD_MM,FBD_Miko,FBD_Trunk,FBD_VL,FBD_VR,IPB_App1
 SG_ ResultBLEConMonitoringFBD_VM__13 : 280|8@1+ (1.0,0) [0|252] "" FBD_HL,FBD_HM,FBD_HR,FBD_MM,FBD_Miko,FBD_Trunk,FBD_VL,FBD_VR,IPB_App1
 SG_ ResultBLEConMonitoringFBD_VM_R_8 : 288|8@1+ (1.0,0) [0|252] "dB" FBD_HL,FBD_HM,FBD_HR,FBD_MM,FBD_Miko,FBD_Trunk,FBD_VL,FBD_VR,IPB_App1
 SG_ ResultBLEConMonitoringFBD_VM_c_8 : 296|16@1+ (1.0,0) [0|65532] "" FBD_HL,FBD_HM,FBD_HR,FBD_MM,FBD_Miko,FBD_Trunk,FBD_VL,FBD_VR,IPB_App1
 SG_ ResultBLEConMonitoringFBD_VM__14 : 312|8@1+ (1.0,0) [0|252] "" FBD_HL,FBD_HM,FBD_HR,FBD_MM,FBD_Miko,FBD_Trunk,FBD_VL,FBD_VR,IPB_App1
 SG_ ResultBLEConMonitoringFBD_VM__15 : 320|8@1+ (1.0,0) [0|252] "" FBD_HL,FBD_HM,FBD_HR,FBD_MM,FBD_Miko,FBD_Trunk,FBD_VL,FBD_VR,IPB_App1
 SG_ ResultBLEConMonitoringFBD_VM_R_9 : 328|8@1+ (1.0,0) [0|252] "dB" FBD_HL,FBD_HM,FBD_HR,FBD_MM,FBD_Miko,FBD_Trunk,FBD_VL,FBD_VR,IPB_App1
 SG_ ResultBLEConMonitoringFBD_VM_c_9 : 336|16@1+ (1.0,0) [0|65532] "" FBD_HL,FBD_HM,FBD_HR,FBD_MM,FBD_Miko,FBD_Trunk,FBD_VL,FBD_VR,IPB_App1
 SG_ ResultBLEConMonitoringFBD_VM__16 : 352|8@1+ (1.0,0) [0|252] "" FBD_HL,FBD_HM,FBD_HR,FBD_MM,FBD_Miko,FBD_Trunk,FBD_VL,FBD_VR,IPB_App1
 SG_ ResultBLEConMonitoringFBD_VM__17 : 360|8@1+ (1.0,0) [0|252] "" FBD_HL,FBD_HM,FBD_HR,FBD_MM,FBD_Miko,FBD_Trunk,FBD_VL,FBD_VR,IPB_App1
 SG_ ResultBLEConMonitoringFBD_VM__18 : 368|8@1+ (1.0,0) [0|252] "dB" FBD_HL,FBD_HM,FBD_HR,FBD_MM,FBD_Miko,FBD_Trunk,FBD_VL,FBD_VR,IPB_App1
 SG_ ResultBLEConMonitoringFBD_VM__19 : 376|16@1+ (1.0,0) [0|65532] "" FBD_HL,FBD_HM,FBD_HR,FBD_MM,FBD_Miko,FBD_Trunk,FBD_VL,FBD_VR,IPB_App1
 SG_ ResultBLEConMonitoringFBD_VM__20 : 392|8@1+ (1.0,0) [0|252] "" FBD_HL,FBD_HM,FBD_HR,FBD_MM,FBD_Miko,FBD_Trunk,FBD_VL,FBD_VR,IPB_App1
 SG_ ResultBLEConMonitoringFBD_VM__21 : 400|8@1+ (1.0,0) [0|252] "" FBD_HL,FBD_HM,FBD_HR,FBD_MM,FBD_Miko,FBD_Trunk,FBD_VL,FBD_VR,IPB_App1
 SG_ ResultBLEConMonitoringFBD_VM_IV0 : 408|8@1+ (1.0,0) [0|255] "" FBD_HL,FBD_HM,FBD_HR,FBD_MM,FBD_Miko,FBD_Trunk,FBD_VL,FBD_VR,IPB_App1
 SG_ ResultBLEConMonitoringFBD_VM_I_2 : 416|8@1+ (1.0,0) [0|255] "" FBD_HL,FBD_HM,FBD_HR,FBD_MM,FBD_Miko,FBD_Trunk,FBD_VL,FBD_VR,IPB_App1
 SG_ ResultBLEConMonitoringFBD_VM_I_3 : 424|8@1+ (1.0,0) [0|255] "" FBD_HL,FBD_HM,FBD_HR,FBD_MM,FBD_Miko,FBD_Trunk,FBD_VL,FBD_VR,IPB_App1
 SG_ ResultBLEConMonitoringFBD_VM_I_4 : 432|8@1+ (1.0,0) [0|255] "" FBD_HL,FBD_HM,FBD_HR,FBD_MM,FBD_Miko,FBD_Trunk,FBD_VL,FBD_VR,IPB_App1
 SG_ ResultBLEConMonitoringFBD_VM_Sig : 440|8@1+ (1.0,0) [0|255] "" FBD_HL,FBD_HM,FBD_HR,FBD_MM,FBD_Miko,FBD_Trunk,FBD_VL,FBD_VR,IPB_App1
 SG_ ResultBLEConMonitoringFBD_VM_S_2 : 448|8@1+ (1.0,0) [0|255] "" FBD_HL,FBD_HM,FBD_HR,FBD_MM,FBD_Miko,FBD_Trunk,FBD_VL,FBD_VR,IPB_App1
 SG_ ResultBLEConMonitoringFBD_VM_S_3 : 456|8@1+ (1.0,0) [0|255] "" FBD_HL,FBD_HM,FBD_HR,FBD_MM,FBD_Miko,FBD_Trunk,FBD_VL,FBD_VR,IPB_App1
 SG_ ResultBLEConMonitoringFBD_VM_S_4 : 464|8@1+ (1.0,0) [0|255] "" FBD_HL,FBD_HM,FBD_HR,FBD_MM,FBD_Miko,FBD_Trunk,FBD_VL,FBD_VR,IPB_App1
 SG_ ResultBLEConMonitoringFBD_VM_S_5 : 472|8@1+ (1.0,0) [0|255] "" FBD_HL,FBD_HM,FBD_HR,FBD_MM,FBD_Miko,FBD_Trunk,FBD_VL,FBD_VR,IPB_App1
 SG_ ResultBLEConMonitoringFBD_VM_S_6 : 480|8@1+ (1.0,0) [0|255] "" FBD_HL,FBD_HM,FBD_HR,FBD_MM,FBD_Miko,FBD_Trunk,FBD_VL,FBD_VR,IPB_App1
 SG_ ResultBLEConMonitoringFBD_VM_S_7 : 488|8@1+ (1.0,0) [0|255] "" FBD_HL,FBD_HM,FBD_HR,FBD_MM,FBD_Miko,FBD_Trunk,FBD_VL,FBD_VR,IPB_App1
 SG_ ResultBLEConMonitoringFBD_VM_S_8 : 496|8@1+ (1.0,0) [0|255] "" FBD_HL,FBD_HM,FBD_HR,FBD_MM,FBD_Miko,FBD_Trunk,FBD_VL,FBD_VR,IPB_App1

BO_ 295 ResultBLEConMonitoringFBD_VR: 64 FBD_VR
 SG_ ResultBLEConMonitoringFBD_VR_IRK : 0|8@1+ (1.0,0) [0|252] "" FBD_HL,FBD_HM,FBD_HR,FBD_MM,FBD_Miko,FBD_Trunk,FBD_VL,FBD_VM,IPB_App1
 SG_ ResultBLEConMonitoringFBD_VR_RSS : 8|8@1+ (1.0,0) [0|252] "dB" FBD_HL,FBD_HM,FBD_HR,FBD_MM,FBD_Miko,FBD_Trunk,FBD_VL,FBD_VM,IPB_App1
 SG_ ResultBLEConMonitoringFBD_VR_con : 16|16@1+ (1.0,0) [0|65532] "" FBD_HL,FBD_HM,FBD_HR,FBD_MM,FBD_Miko,FBD_Trunk,FBD_VL,FBD_VM,IPB_App1
 SG_ ResultBLEConMonitoringFBD_VR_Ch_ : 32|8@1+ (1.0,0) [0|252] "" FBD_HL,FBD_HM,FBD_HR,FBD_MM,FBD_Miko,FBD_Trunk,FBD_VL,FBD_VM,IPB_App1
 SG_ ResultBLEConMonitoringFBD_VR_Dev : 40|8@1+ (1.0,0) [0|252] "" FBD_HL,FBD_HM,FBD_HR,FBD_MM,FBD_Miko,FBD_Trunk,FBD_VL,FBD_VM,IPB_App1
 SG_ ResultBLEConMonitoringFBD_VR_R_2 : 48|8@1+ (1.0,0) [0|252] "dB" FBD_HL,FBD_HM,FBD_HR,FBD_MM,FBD_Miko,FBD_Trunk,FBD_VL,FBD_VM,IPB_App1
 SG_ ResultBLEConMonitoringFBD_VR_c_2 : 56|16@1+ (1.0,0) [0|65532] "" FBD_HL,FBD_HM,FBD_HR,FBD_MM,FBD_Miko,FBD_Trunk,FBD_VL,FBD_VM,IPB_App1
 SG_ ResultBLEConMonitoringFBD_VR_C_2 : 72|8@1+ (1.0,0) [0|252] "" FBD_HL,FBD_HM,FBD_HR,FBD_MM,FBD_Miko,FBD_Trunk,FBD_VL,FBD_VM,IPB_App1
 SG_ ResultBLEConMonitoringFBD_VR_C_3 : 80|8@1+ (1.0,0) [0|252] "" FBD_HL,FBD_HM,FBD_HR,FBD_MM,FBD_Miko,FBD_Trunk,FBD_VL,FBD_VM,IPB_App1
 SG_ ResultBLEConMonitoringFBD_VR_R_3 : 88|8@1+ (1.0,0) [0|252] "dB" FBD_HL,FBD_HM,FBD_HR,FBD_MM,FBD_Miko,FBD_Trunk,FBD_VL,FBD_VM,IPB_App1
 SG_ ResultBLEConMonitoringFBD_VR_c_3 : 96|16@1+ (1.0,0) [0|65532] "" FBD_HL,FBD_HM,FBD_HR,FBD_MM,FBD_Miko,FBD_Trunk,FBD_VL,FBD_VM,IPB_App1
 SG_ ResultBLEConMonitoringFBD_VR_C_4 : 112|8@1+ (1.0,0) [0|252] "" FBD_HL,FBD_HM,FBD_HR,FBD_MM,FBD_Miko,FBD_Trunk,FBD_VL,FBD_VM,IPB_App1
 SG_ ResultBLEConMonitoringFBD_VR_C_5 : 120|8@1+ (1.0,0) [0|252] "" FBD_HL,FBD_HM,FBD_HR,FBD_MM,FBD_Miko,FBD_Trunk,FBD_VL,FBD_VM,IPB_App1
 SG_ ResultBLEConMonitoringFBD_VR_R_4 : 128|8@1+ (1.0,0) [0|252] "dB" FBD_HL,FBD_HM,FBD_HR,FBD_MM,FBD_Miko,FBD_Trunk,FBD_VL,FBD_VM,IPB_App1
 SG_ ResultBLEConMonitoringFBD_VR_c_4 : 136|16@1+ (1.0,0) [0|65532] "" FBD_HL,FBD_HM,FBD_HR,FBD_MM,FBD_Miko,FBD_Trunk,FBD_VL,FBD_VM,IPB_App1
 SG_ ResultBLEConMonitoringFBD_VR_C_6 : 152|8@1+ (1.0,0) [0|252] "" FBD_HL,FBD_HM,FBD_HR,FBD_MM,FBD_Miko,FBD_Trunk,FBD_VL,FBD_VM,IPB_App1
 SG_ ResultBLEConMonitoringFBD_VR_C_7 : 160|8@1+ (1.0,0) [0|252] "" FBD_HL,FBD_HM,FBD_HR,FBD_MM,FBD_Miko,FBD_Trunk,FBD_VL,FBD_VM,IPB_App1
 SG_ ResultBLEConMonitoringFBD_VR_R_5 : 168|8@1+ (1.0,0) [0|252] "dB" FBD_HL,FBD_HM,FBD_HR,FBD_MM,FBD_Miko,FBD_Trunk,FBD_VL,FBD_VM,IPB_App1
 SG_ ResultBLEConMonitoringFBD_VR_c_5 : 176|16@1+ (1.0,0) [0|65532] "" FBD_HL,FBD_HM,FBD_HR,FBD_MM,FBD_Miko,FBD_Trunk,FBD_VL,FBD_VM,IPB_App1
 SG_ ResultBLEConMonitoringFBD_VR_C_8 : 192|8@1+ (1.0,0) [0|252] "" FBD_HL,FBD_HM,FBD_HR,FBD_MM,FBD_Miko,FBD_Trunk,FBD_VL,FBD_VM,IPB_App1
 SG_ ResultBLEConMonitoringFBD_VR_C_9 : 200|8@1+ (1.0,0) [0|252] "" FBD_HL,FBD_HM,FBD_HR,FBD_MM,FBD_Miko,FBD_Trunk,FBD_VL,FBD_VM,IPB_App1
 SG_ ResultBLEConMonitoringFBD_VR_R_6 : 208|8@1+ (1.0,0) [0|252] "dB" FBD_HL,FBD_HM,FBD_HR,FBD_MM,FBD_Miko,FBD_Trunk,FBD_VL,FBD_VM,IPB_App1
 SG_ ResultBLEConMonitoringFBD_VR_c_6 : 216|16@1+ (1.0,0) [0|65532] "" FBD_HL,FBD_HM,FBD_HR,FBD_MM,FBD_Miko,FBD_Trunk,FBD_VL,FBD_VM,IPB_App1
 SG_ ResultBLEConMonitoringFBD_VR__10 : 232|8@1+ (1.0,0) [0|252] "" FBD_HL,FBD_HM,FBD_HR,FBD_MM,FBD_Miko,FBD_Trunk,FBD_VL,FBD_VM,IPB_App1
 SG_ ResultBLEConMonitoringFBD_VR__11 : 240|8@1+ (1.0,0) [0|252] "" FBD_HL,FBD_HM,FBD_HR,FBD_MM,FBD_Miko,FBD_Trunk,FBD_VL,FBD_VM,IPB_App1
 SG_ ResultBLEConMonitoringFBD_VR_R_7 : 248|8@1+ (1.0,0) [0|252] "dB" FBD_HL,FBD_HM,FBD_HR,FBD_MM,FBD_Miko,FBD_Trunk,FBD_VL,FBD_VM,IPB_App1
 SG_ ResultBLEConMonitoringFBD_VR_c_7 : 256|16@1+ (1.0,0) [0|65532] "" FBD_HL,FBD_HM,FBD_HR,FBD_MM,FBD_Miko,FBD_Trunk,FBD_VL,FBD_VM,IPB_App1
 SG_ ResultBLEConMonitoringFBD_VR__12 : 272|8@1+ (1.0,0) [0|252] "" FBD_HL,FBD_HM,FBD_HR,FBD_MM,FBD_Miko,FBD_Trunk,FBD_VL,FBD_VM,IPB_App1
 SG_ ResultBLEConMonitoringFBD_VR__13 : 280|8@1+ (1.0,0) [0|252] "" FBD_HL,FBD_HM,FBD_HR,FBD_MM,FBD_Miko,FBD_Trunk,FBD_VL,FBD_VM,IPB_App1
 SG_ ResultBLEConMonitoringFBD_VR_R_8 : 288|8@1+ (1.0,0) [0|252] "dB" FBD_HL,FBD_HM,FBD_HR,FBD_MM,FBD_Miko,FBD_Trunk,FBD_VL,FBD_VM,IPB_App1
 SG_ ResultBLEConMonitoringFBD_VR_c_8 : 296|16@1+ (1.0,0) [0|65532] "" FBD_HL,FBD_HM,FBD_HR,FBD_MM,FBD_Miko,FBD_Trunk,FBD_VL,FBD_VM,IPB_App1
 SG_ ResultBLEConMonitoringFBD_VR__14 : 312|8@1+ (1.0,0) [0|252] "" FBD_HL,FBD_HM,FBD_HR,FBD_MM,FBD_Miko,FBD_Trunk,FBD_VL,FBD_VM,IPB_App1
 SG_ ResultBLEConMonitoringFBD_VR__15 : 320|8@1+ (1.0,0) [0|252] "" FBD_HL,FBD_HM,FBD_HR,FBD_MM,FBD_Miko,FBD_Trunk,FBD_VL,FBD_VM,IPB_App1
 SG_ ResultBLEConMonitoringFBD_VR_R_9 : 328|8@1+ (1.0,0) [0|252] "dB" FBD_HL,FBD_HM,FBD_HR,FBD_MM,FBD_Miko,FBD_Trunk,FBD_VL,FBD_VM,IPB_App1
 SG_ ResultBLEConMonitoringFBD_VR_c_9 : 336|16@1+ (1.0,0) [0|65532] "" FBD_HL,FBD_HM,FBD_HR,FBD_MM,FBD_Miko,FBD_Trunk,FBD_VL,FBD_VM,IPB_App1
 SG_ ResultBLEConMonitoringFBD_VR__16 : 352|8@1+ (1.0,0) [0|252] "" FBD_HL,FBD_HM,FBD_HR,FBD_MM,FBD_Miko,FBD_Trunk,FBD_VL,FBD_VM,IPB_App1
 SG_ ResultBLEConMonitoringFBD_VR__17 : 360|8@1+ (1.0,0) [0|252] "" FBD_HL,FBD_HM,FBD_HR,FBD_MM,FBD_Miko,FBD_Trunk,FBD_VL,FBD_VM,IPB_App1
 SG_ ResultBLEConMonitoringFBD_VR__18 : 368|8@1+ (1.0,0) [0|252] "dB" FBD_HL,FBD_HM,FBD_HR,FBD_MM,FBD_Miko,FBD_Trunk,FBD_VL,FBD_VM,IPB_App1
 SG_ ResultBLEConMonitoringFBD_VR__19 : 376|16@1+ (1.0,0) [0|65532] "" FBD_HL,FBD_HM,FBD_HR,FBD_MM,FBD_Miko,FBD_Trunk,FBD_VL,FBD_VM,IPB_App1
 SG_ ResultBLEConMonitoringFBD_VR__20 : 392|8@1+ (1.0,0) [0|252] "" FBD_HL,FBD_HM,FBD_HR,FBD_MM,FBD_Miko,FBD_Trunk,FBD_VL,FBD_VM,IPB_App1
 SG_ ResultBLEConMonitoringFBD_VR__21 : 400|8@1+ (1.0,0) [0|252] "" FBD_HL,FBD_HM,FBD_HR,FBD_MM,FBD_Miko,FBD_Trunk,FBD_VL,FBD_VM,IPB_App1
 SG_ ResultBLEConMonitoringFBD_VR_IV0 : 408|8@1+ (1.0,0) [0|255] "" FBD_HL,FBD_HM,FBD_HR,FBD_MM,FBD_Miko,FBD_Trunk,FBD_VL,FBD_VM,IPB_App1
 SG_ ResultBLEConMonitoringFBD_VR_I_2 : 416|8@1+ (1.0,0) [0|255] "" FBD_HL,FBD_HM,FBD_HR,FBD_MM,FBD_Miko,FBD_Trunk,FBD_VL,FBD_VM,IPB_App1
 SG_ ResultBLEConMonitoringFBD_VR_I_3 : 424|8@1+ (1.0,0) [0|255] "" FBD_HL,FBD_HM,FBD_HR,FBD_MM,FBD_Miko,FBD_Trunk,FBD_VL,FBD_VM,IPB_App1
 SG_ ResultBLEConMonitoringFBD_VR_I_4 : 432|8@1+ (1.0,0) [0|255] "" FBD_HL,FBD_HM,FBD_HR,FBD_MM,FBD_Miko,FBD_Trunk,FBD_VL,FBD_VM,IPB_App1
 SG_ ResultBLEConMonitoringFBD_VR_Sig : 440|8@1+ (1.0,0) [0|255] "" FBD_HL,FBD_HM,FBD_HR,FBD_MM,FBD_Miko,FBD_Trunk,FBD_VL,FBD_VM,IPB_App1
 SG_ ResultBLEConMonitoringFBD_VR_S_2 : 448|8@1+ (1.0,0) [0|255] "" FBD_HL,FBD_HM,FBD_HR,FBD_MM,FBD_Miko,FBD_Trunk,FBD_VL,FBD_VM,IPB_App1
 SG_ ResultBLEConMonitoringFBD_VR_S_3 : 456|8@1+ (1.0,0) [0|255] "" FBD_HL,FBD_HM,FBD_HR,FBD_MM,FBD_Miko,FBD_Trunk,FBD_VL,FBD_VM,IPB_App1
 SG_ ResultBLEConMonitoringFBD_VR_S_4 : 464|8@1+ (1.0,0) [0|255] "" FBD_HL,FBD_HM,FBD_HR,FBD_MM,FBD_Miko,FBD_Trunk,FBD_VL,FBD_VM,IPB_App1
 SG_ ResultBLEConMonitoringFBD_VR_S_5 : 472|8@1+ (1.0,0) [0|255] "" FBD_HL,FBD_HM,FBD_HR,FBD_MM,FBD_Miko,FBD_Trunk,FBD_VL,FBD_VM,IPB_App1
 SG_ ResultBLEConMonitoringFBD_VR_S_6 : 480|8@1+ (1.0,0) [0|255] "" FBD_HL,FBD_HM,FBD_HR,FBD_MM,FBD_Miko,FBD_Trunk,FBD_VL,FBD_VM,IPB_App1
 SG_ ResultBLEConMonitoringFBD_VR_S_7 : 488|8@1+ (1.0,0) [0|255] "" FBD_HL,FBD_HM,FBD_HR,FBD_MM,FBD_Miko,FBD_Trunk,FBD_VL,FBD_VM,IPB_App1
 SG_ ResultBLEConMonitoringFBD_VR_S_8 : 496|8@1+ (1.0,0) [0|255] "" FBD_HL,FBD_HM,FBD_HR,FBD_MM,FBD_Miko,FBD_Trunk,FBD_VL,FBD_VM,IPB_App1

BO_ 576 ResultBLERSSIRangingIntentFBD_HL: 8 FBD_HL
 SG_ ResultBLERSSIRangingIntentFBD_HL : 0|16@1+ (1,0) [0|0] "" FBD_HM,FBD_HR,FBD_MM,FBD_Miko,FBD_Trunk,FBD_VL,FBD_VM,FBD_VR
 SG_ ResultBLERSSIRangingIntentFBD__2 : 16|8@1+ (1.0,0) [0|252] "" FBD_HM,FBD_HR,FBD_MM,FBD_Miko,FBD_Trunk,FBD_VL,FBD_VM,FBD_VR
 SG_ ResultBLERSSIRangingIntentFBD__3 : 24|8@1+ (1.0,0) [0|252] "" FBD_HM,FBD_HR,FBD_MM,FBD_Miko,FBD_Trunk,FBD_VL,FBD_VM,FBD_VR
 SG_ ResultBLERSSIRangingIntentFBD__4 : 32|8@1+ (0.004,0) [0|1] "" FBD_HM,FBD_HR,FBD_MM,FBD_Miko,FBD_Trunk,FBD_VL,FBD_VM,FBD_VR

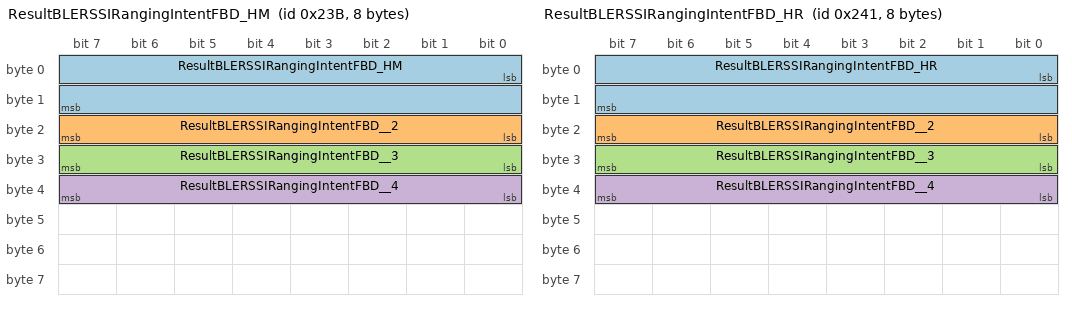
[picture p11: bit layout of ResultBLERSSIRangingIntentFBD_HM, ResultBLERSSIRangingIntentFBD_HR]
BO_ 571 ResultBLERSSIRangingIntentFBD_HM: 8 FBD_HM
 SG_ ResultBLERSSIRangingIntentFBD_HM : 0|16@1+ (1,0) [0|0] "" FBD_HL,FBD_HR,FBD_MM,FBD_Miko,FBD_Trunk,FBD_VL,FBD_VM,FBD_VR
 SG_ ResultBLERSSIRangingIntentFBD__2 : 16|8@1+ (1.0,0) [0|252] "" FBD_HL,FBD_HR,FBD_MM,FBD_Miko,FBD_Trunk,FBD_VL,FBD_VM,FBD_VR
 SG_ ResultBLERSSIRangingIntentFBD__3 : 24|8@1+ (1.0,0) [0|252] "" FBD_HL,FBD_HR,FBD_MM,FBD_Miko,FBD_Trunk,FBD_VL,FBD_VM,FBD_VR
 SG_ ResultBLERSSIRangingIntentFBD__4 : 32|8@1+ (0.004,0) [0|1] "" FBD_HL,FBD_HR,FBD_MM,FBD_Miko,FBD_Trunk,FBD_VL,FBD_VM,FBD_VR

BO_ 577 ResultBLERSSIRangingIntentFBD_HR: 8 FBD_HR
 SG_ ResultBLERSSIRangingIntentFBD_HR : 0|16@1+ (1,0) [0|0] "" FBD_HL,FBD_HM,FBD_MM,FBD_Miko,FBD_Trunk,FBD_VL,FBD_VM,FBD_VR
 SG_ ResultBLERSSIRangingIntentFBD__2 : 16|8@1+ (1.0,0) [0|252] "" FBD_HL,FBD_HM,FBD_MM,FBD_Miko,FBD_Trunk,FBD_VL,FBD_VM,FBD_VR
 SG_ ResultBLERSSIRangingIntentFBD__3 : 24|8@1+ (1.0,0) [0|252] "" FBD_HL,FBD_HM,FBD_MM,FBD_Miko,FBD_Trunk,FBD_VL,FBD_VM,FBD_VR
 SG_ ResultBLERSSIRangingIntentFBD__4 : 32|8@1+ (0.004,0) [0|1] "" FBD_HL,FBD_HM,FBD_MM,FBD_Miko,FBD_Trunk,FBD_VL,FBD_VM,FBD_VR

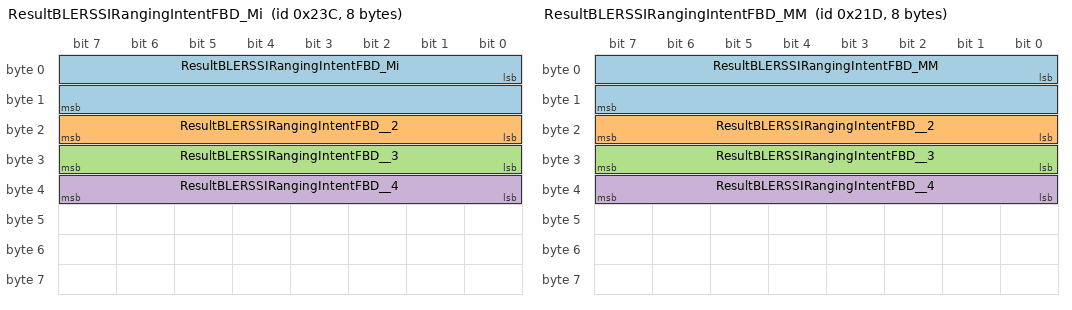
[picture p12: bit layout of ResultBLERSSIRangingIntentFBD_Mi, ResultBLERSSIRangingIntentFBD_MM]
BO_ 572 ResultBLERSSIRangingIntentFBD_Mi: 8 FBD_Miko
 SG_ ResultBLERSSIRangingIntentFBD_Mi : 0|16@1+ (1,0) [0|0] "" FBD_HL,FBD_HM,FBD_HR,FBD_MM,FBD_Trunk,FBD_VL,FBD_VM,FBD_VR
 SG_ ResultBLERSSIRangingIntentFBD__2 : 16|8@1+ (1.0,0) [0|252] "" FBD_HL,FBD_HM,FBD_HR,FBD_MM,FBD_Trunk,FBD_VL,FBD_VM,FBD_VR
 SG_ ResultBLERSSIRangingIntentFBD__3 : 24|8@1+ (1.0,0) [0|252] "" FBD_HL,FBD_HM,FBD_HR,FBD_MM,FBD_Trunk,FBD_VL,FBD_VM,FBD_VR
 SG_ ResultBLERSSIRangingIntentFBD__4 : 32|8@1+ (0.004,0) [0|1] "" FBD_HL,FBD_HM,FBD_HR,FBD_MM,FBD_Trunk,FBD_VL,FBD_VM,FBD_VR

BO_ 541 ResultBLERSSIRangingIntentFBD_MM: 8 FBD_MM
 SG_ ResultBLERSSIRangingIntentFBD_MM : 0|16@1+ (1,0) [0|0] "" FBD_HL,FBD_HM,FBD_HR,FBD_Miko,FBD_Trunk,FBD_VL,FBD_VM,FBD_VR
 SG_ ResultBLERSSIRangingIntentFBD__2 : 16|8@1+ (1.0,0) [0|252] "" FBD_HL,FBD_HM,FBD_HR,FBD_Miko,FBD_Trunk,FBD_VL,FBD_VM,FBD_VR
 SG_ ResultBLERSSIRangingIntentFBD__3 : 24|8@1+ (1.0,0) [0|252] "" FBD_HL,FBD_HM,FBD_HR,FBD_Miko,FBD_Trunk,FBD_VL,FBD_VM,FBD_VR
 SG_ ResultBLERSSIRangingIntentFBD__4 : 32|8@1+ (0.004,0) [0|1] "" FBD_HL,FBD_HM,FBD_HR,FBD_Miko,FBD_Trunk,FBD_VL,FBD_VM,FBD_VR

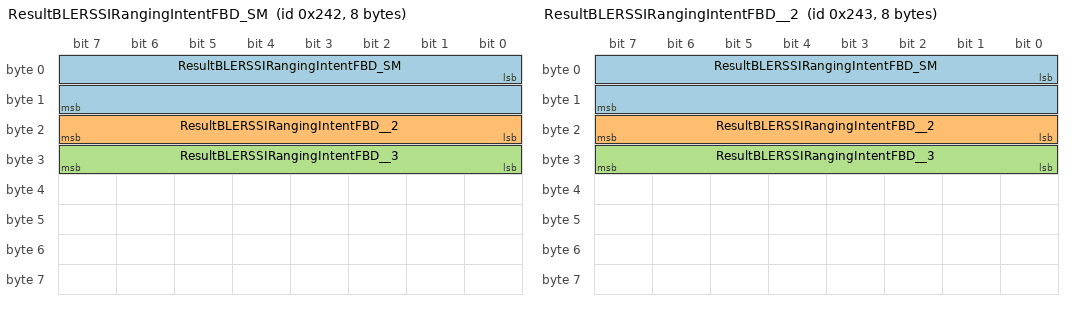
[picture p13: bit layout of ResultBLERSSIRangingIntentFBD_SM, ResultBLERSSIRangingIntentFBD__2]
BO_ 578 ResultBLERSSIRangingIntentFBD_SM: 8 IPB_App1
 SG_ ResultBLERSSIRangingIntentFBD_SM : 0|16@1+ (1,0) [0|0] "" FBD_HL,FBD_HM,FBD_HR,FBD_MM,FBD_Miko,FBD_Trunk,FBD_VL,FBD_VM,FBD_VR
 SG_ ResultBLERSSIRangingIntentFBD__2 : 16|8@1+ (1.0,0) [0|252] "" FBD_HL,FBD_HM,FBD_HR,FBD_MM,FBD_Miko,FBD_Trunk,FBD_VL,FBD_VM,FBD_VR
 SG_ ResultBLERSSIRangingIntentFBD__3 : 24|8@1+ (1.0,0) [0|252] "" FBD_HL,FBD_HM,FBD_HR,FBD_MM,FBD_Miko,FBD_Trunk,FBD_VL,FBD_VM,FBD_VR

BO_ 579 ResultBLERSSIRangingIntentFBD__2: 8 IPB_App1
 SG_ ResultBLERSSIRangingIntentFBD_SM : 0|16@1+ (1,0) [0|0] "" FBD_HL,FBD_HM,FBD_HR,FBD_MM,FBD_Miko,FBD_Trunk,FBD_VL,FBD_VM,FBD_VR
 SG_ ResultBLERSSIRangingIntentFBD__2 : 16|8@1+ (1.0,0) [0|252] "" FBD_HL,FBD_HM,FBD_HR,FBD_MM,FBD_Miko,FBD_Trunk,FBD_VL,FBD_VM,FBD_VR
 SG_ ResultBLERSSIRangingIntentFBD__3 : 24|8@1+ (1.0,0) [0|252] "" FBD_HL,FBD_HM,FBD_HR,FBD_MM,FBD_Miko,FBD_Trunk,FBD_VL,FBD_VM,FBD_VR

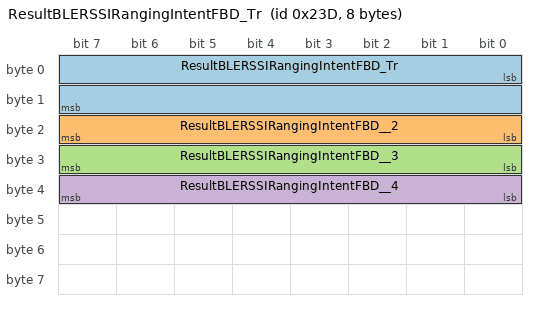
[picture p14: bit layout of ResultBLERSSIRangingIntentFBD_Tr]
BO_ 573 ResultBLERSSIRangingIntentFBD_Tr: 8 FBD_Trunk
 SG_ ResultBLERSSIRangingIntentFBD_Tr : 0|16@1+ (1,0) [0|0] "" FBD_HL,FBD_HM,FBD_HR,FBD_MM,FBD_Miko,FBD_VL,FBD_VM,FBD_VR
 SG_ ResultBLERSSIRangingIntentFBD__2 : 16|8@1+ (1.0,0) [0|252] "" FBD_HL,FBD_HM,FBD_HR,FBD_MM,FBD_Miko,FBD_VL,FBD_VM,FBD_VR
 SG_ ResultBLERSSIRangingIntentFBD__3 : 24|8@1+ (1.0,0) [0|252] "" FBD_HL,FBD_HM,FBD_HR,FBD_MM,FBD_Miko,FBD_VL,FBD_VM,FBD_VR
 SG_ ResultBLERSSIRangingIntentFBD__4 : 32|8@1+ (0.004,0) [0|1] "" FBD_HL,FBD_HM,FBD_HR,FBD_MM,FBD_Miko,FBD_VL,FBD_VM,FBD_VR

CM_ SG_ 552 LocalizationInitFBD_Miko_IRKList "contains Session-ID";
CM_ SG_ 552 LocalizationInitFBD_Miko_ZoneEnt "contains Zone transition";
CM_ SG_ 552 LocalizationInitFBD_Miko_Ranging "Frame Index of the latest ranging";
CM_ SG_ 552 LocalizationInitFBD_Miko_TimeOfF "ranging result in ps (PH) = (DEC) * 15.65";
CM_ SG_ 552 LocalizationInitFBD_Miko_RSSI_0 "first path AoA";
CM_ SG_ 552 LocalizationInitFBD_Miko_Rangi_2 "Frame Index of the second-to-last ranging";
CM_ SG_ 552 LocalizationInitFBD_Miko_TimeO_2 "ranging result in ps (PH) = (DEC) * 15.65";
CM_ SG_ 552 LocalizationInitFBD_Miko_RSSI_1 "first path AoA";
CM_ SG_ 552 LocalizationInitFBD_Miko_Rangi_3 "Frame Index of the third-to-last ranging";
CM_ SG_ 552 LocalizationInitFBD_Miko_TimeO_3 "ranging result in ps (PH) = (DEC) * 15.65";
CM_ SG_ 552 LocalizationInitFBD_Miko_RSSI_2 "first path AoA";
CM_ SG_ 552 LocalizationInitFBD_Miko_Rangi_4 "Frame Index of the fourth-last ranging";
CM_ SG_ 552 LocalizationInitFBD_Miko_TimeO_4 "ranging result in ps (PH) = (DEC) * 15.65";
CM_ SG_ 552 LocalizationInitFBD_Miko_RSSI_3 "first path AoA";
CM_ SG_ 552 LocalizationInitFBD_Miko_Rangi_5 "Frame Index of the fifth-last ranging";
CM_ SG_ 552 LocalizationInitFBD_Miko_TimeO_5 "ranging result in ps (PH) = (DEC) * 15.65";
CM_ SG_ 552 LocalizationInitFBD_Miko_RSSI_4 "first path AoA";
CM_ SG_ 552 LocalizationInitFBD_Miko_Sign_00 "contains Auth. Signal is encrypted, signal TAG not possible";
CM_ SG_ 552 LocalizationInitFBD_Miko_Sign_01 "contains Auth. Signal is encrypted, signal TAG not possible";
CM_ SG_ 552 LocalizationInitFBD_Miko_Sign_02 "contains Auth. Signal is encrypted, signal TAG not possible";
CM_ SG_ 552 LocalizationInitFBD_Miko_Sign_03 "contains Auth. Signal is encrypted, signal TAG not possible";
CM_ SG_ 552 LocalizationInitFBD_Miko_Sign_04 "contains Auth. Signal is encrypted, signal TAG not possible";
CM_ SG_ 552 LocalizationInitFBD_Miko_Sign_05 "contains Auth. Signal is encrypted, signal TAG not possible";
CM_ SG_ 552 LocalizationInitFBD_Miko_Sign_06 "contains Auth. Signal is encrypted, signal TAG not possible";
CM_ SG_ 552 LocalizationInitFBD_Miko_Sign_07 "contains Auth. Signal is encrypted, signal TAG not possible";
CM_ SG_ 552 LocalizationInitFBD_Miko_Sign_08 "contains Auth. Signal is encrypted, signal TAG not possible";
CM_ SG_ 552 LocalizationInitFBD_Miko_Sign_09 "contains Auth. Signal is encrypted, signal TAG not possible";
CM_ SG_ 552 LocalizationInitFBD_Miko_Sign_10 "contains Auth. Signal is encrypted, signal TAG not possible";
CM_ SG_ 552 LocalizationInitFBD_Miko_Sign_11 "contains Auth. Signal is encrypted, signal TAG not possible";
CM_ SG_ 552 LocalizationInitFBD_Miko_Sign_12 "contains Auth. Signal is encrypted, signal TAG not possible";
CM_ SG_ 552 LocalizationInitFBD_Miko_Sign_13 "contains Auth. Signal is encrypted, signal TAG not possible";
CM_ SG_ 552 LocalizationInitFBD_Miko_Sign_14 "contains Auth. Signal is encrypted, signal TAG not possible";
CM_ SG_ 552 LocalizationInitFBD_Miko_Sign_15 "contains Auth. Signal is encrypted, signal TAG not possible";
CM_ SG_ 552 LocalizationInitFBD_Miko_Rangi_6 "contains Hopping Offset";
CM_ SG_ 552 LocalizationInitFBD_Miko_Rangi_7 "contains Hopping Offset";
CM_ SG_ 552 LocalizationInitFBD_Miko_Rangi_8 "contains Hopping Offset";
CM_ SG_ 552 LocalizationInitFBD_Miko_Rangi_9 "contains Hopping Offset";
CM_ SG_ 552 LocalizationInitFBD_Miko_Rang_10 "contains Hopping Offset";
CM_ SG_ 560 LocalizationInitFBD_MM_IRKListIn "contains Session-ID";
CM_ SG_ 560 LocalizationInitFBD_MM_ZoneEntry "contains Zone transition";
CM_ SG_ 560 LocalizationInitFBD_MM_RangingBl "Frame Index of the latest ranging";
CM_ SG_ 560 LocalizationInitFBD_MM_TimeOfFli "ranging result in ps (PH) = (DEC) * 15.65";
CM_ SG_ 560 LocalizationInitFBD_MM_RSSI_0 "first path AoA (Range: 0 ... 180° / step: 1°)";
CM_ SG_ 560 LocalizationInitFBD_MM_Ranging_2 "Frame Index of the second-to-last ranging";
CM_ SG_ 560 LocalizationInitFBD_MM_TimeOfF_2 "ranging result in ps (PH) = (DEC) * 15.65";
CM_ SG_ 560 LocalizationInitFBD_MM_RSSI_1 "first path AoA (Range: 0 ... 180° / step: 1°)";
CM_ SG_ 560 LocalizationInitFBD_MM_Ranging_3 "Frame Index of the third-to-last ranging";
CM_ SG_ 560 LocalizationInitFBD_MM_TimeOfF_3 "ranging result in ps (PH) = (DEC) * 15.65";
CM_ SG_ 560 LocalizationInitFBD_MM_RSSI_2 "first path AoA (Range: 0 ... 180° / step: 1°)";
CM_ SG_ 560 LocalizationInitFBD_MM_Ranging_4 "Frame Index of the fourth-last ranging";
CM_ SG_ 560 LocalizationInitFBD_MM_TimeOfF_4 "ranging result in ps (PH) = (DEC) * 15.65";
CM_ SG_ 560 LocalizationInitFBD_MM_RSSI_3 "first path AoA (Range: 0 ... 180° / step: 1°)";
CM_ SG_ 560 LocalizationInitFBD_MM_Ranging_5 "Frame Index of the fifth-last ranging";
CM_ SG_ 560 LocalizationInitFBD_MM_TimeOfF_5 "ranging result in ps (PH) = (DEC) * 15.65";
CM_ SG_ 560 LocalizationInitFBD_MM_RSSI_4 "first path AoA (Range: 0 ... 180° / step: 1°)";
CM_ SG_ 560 LocalizationInitFBD_MM_Sign_00 "contains Auth. Signal is encrypted, signal TAG not possible";
CM_ SG_ 560 LocalizationInitFBD_MM_Sign_01 "contains Auth. Signal is encrypted, signal TAG not possible";
CM_ SG_ 560 LocalizationInitFBD_MM_Sign_02 "contains Auth. Signal is encrypted, signal TAG not possible";
CM_ SG_ 560 LocalizationInitFBD_MM_Sign_03 "contains Auth. Signal is encrypted, signal TAG not possible";
CM_ SG_ 560 LocalizationInitFBD_MM_Sign_04 "contains Auth. Signal is encrypted, signal TAG not possible";
CM_ SG_ 560 LocalizationInitFBD_MM_Sign_05 "contains Auth. Signal is encrypted, signal TAG not possible";
CM_ SG_ 560 LocalizationInitFBD_MM_Sign_06 "contains Auth. Signal is encrypted, signal TAG not possible";
CM_ SG_ 560 LocalizationInitFBD_MM_Sign_07 "contains Auth. Signal is encrypted, signal TAG not possible";
CM_ SG_ 560 LocalizationInitFBD_MM_Sign_08 "contains Auth. Signal is encrypted, signal TAG not possible";
CM_ SG_ 560 LocalizationInitFBD_MM_Sign_09 "contains Auth. Signal is encrypted, signal TAG not possible";
CM_ SG_ 560 LocalizationInitFBD_MM_Sign_10 "contains Auth. Signal is encrypted, signal TAG not possible";
CM_ SG_ 560 LocalizationInitFBD_MM_Sign_11 "contains Auth. Signal is encrypted, signal TAG not possible";
CM_ SG_ 560 LocalizationInitFBD_MM_Sign_12 "contains Auth. Signal is encrypted, signal TAG not possible";
CM_ SG_ 560 LocalizationInitFBD_MM_Sign_13 "contains Auth. Signal is encrypted, signal TAG not possible";
CM_ SG_ 560 LocalizationInitFBD_MM_Sign_14 "contains Auth. Signal is encrypted, signal TAG not possible";
CM_ SG_ 560 LocalizationInitFBD_MM_Sign_15 "contains Auth. Signal is encrypted, signal TAG not possible";
CM_ SG_ 560 LocalizationInitFBD_MM_RangingRo "contains Hopping Offset";
CM_ SG_ 560 LocalizationInitFBD_MM_Ranging_6 "contains Hopping Offset";
CM_ SG_ 560 LocalizationInitFBD_MM_Ranging_7 "contains Hopping Offset";
CM_ SG_ 560 LocalizationInitFBD_MM_Ranging_8 "contains Hopping Offset";
CM_ SG_ 560 LocalizationInitFBD_MM_Ranging_9 "contains Hopping Offset";
CM_ SG_ 553 LocalizationInitFBD_Trunk_IRKLis "contains Session-ID";
CM_ SG_ 553 LocalizationInitFBD_Trunk_ZoneEn "contains Zone transition";
CM_ SG_ 553 LocalizationInitFBD_Trunk_Rangin "Frame Index of the latest ranging";
CM_ SG_ 553 LocalizationInitFBD_Trunk_TimeOf "ranging result in ps (PH) = (DEC) * 15.65";
CM_ SG_ 553 LocalizationInitFBD_Trunk_RSSI_0 "first path AoA";
CM_ SG_ 553 LocalizationInitFBD_Trunk_Rang_2 "Frame Index of the second-to-last ranging";
CM_ SG_ 553 LocalizationInitFBD_Trunk_Time_2 "ranging result in ps (PH) = (DEC) * 15.65";
CM_ SG_ 553 LocalizationInitFBD_Trunk_RSSI_1 "first path AoA";
CM_ SG_ 553 LocalizationInitFBD_Trunk_Rang_3 "Frame Index of the third-to-last ranging";
CM_ SG_ 553 LocalizationInitFBD_Trunk_Time_3 "ranging result in ps (PH) = (DEC) * 15.65";
CM_ SG_ 553 LocalizationInitFBD_Trunk_RSSI_2 "first path AoA";
CM_ SG_ 553 LocalizationInitFBD_Trunk_Rang_4 "Frame Index of the fourth-last ranging";
CM_ SG_ 553 LocalizationInitFBD_Trunk_Time_4 "ranging result in ps (PH) = (DEC) * 15.65";
CM_ SG_ 553 LocalizationInitFBD_Trunk_RSSI_3 "first path AoA";
CM_ SG_ 553 LocalizationInitFBD_Trunk_Rang_5 "Frame Index of the fifth-last ranging";
CM_ SG_ 553 LocalizationInitFBD_Trunk_Time_5 "ranging result in ps (PH) = (DEC) * 15.65";
CM_ SG_ 553 LocalizationInitFBD_Trunk_RSSI_4 "first path AoA";
CM_ SG_ 553 LocalizationInitFBD_Trunk_Sign_0 "contains Auth. Signal is encrypted, signal TAG not possible";
CM_ SG_ 553 LocalizationInitFBD_Trunk_Sign_2 "contains Auth. Signal is encrypted, signal TAG not possible";
CM_ SG_ 553 LocalizationInitFBD_Trunk_Sign_3 "contains Auth. Signal is encrypted, signal TAG not possible";
CM_ SG_ 553 LocalizationInitFBD_Trunk_Sign_4 "contains Auth. Signal is encrypted, signal TAG not possible";
CM_ SG_ 553 LocalizationInitFBD_Trunk_Sign_5 "contains Auth. Signal is encrypted, signal TAG not possible";
CM_ SG_ 553 LocalizationInitFBD_Trunk_Sign_6 "contains Auth. Signal is encrypted, signal TAG not possible";
CM_ SG_ 553 LocalizationInitFBD_Trunk_Sign_7 "contains Auth. Signal is encrypted, signal TAG not possible";
CM_ SG_ 553 LocalizationInitFBD_Trunk_Sign_8 "contains Auth. Signal is encrypted, signal TAG not possible";
CM_ SG_ 553 LocalizationInitFBD_Trunk_Sign_9 "contains Auth. Signal is encrypted, signal TAG not possible";
CM_ SG_ 553 LocalizationInitFBD_Trunk_Sig_10 "contains Auth. Signal is encrypted, signal TAG not possible";
CM_ SG_ 553 LocalizationInitFBD_Trunk_Sign_1 "contains Auth. Signal is encrypted, signal TAG not possible";
CM_ SG_ 553 LocalizationInitFBD_Trunk_Sig_11 "contains Auth. Signal is encrypted, signal TAG not possible";
CM_ SG_ 553 LocalizationInitFBD_Trunk_Sig_12 "contains Auth. Signal is encrypted, signal TAG not possible";
CM_ SG_ 553 LocalizationInitFBD_Trunk_Sig_13 "contains Auth. Signal is encrypted, signal TAG not possible";
CM_ SG_ 553 LocalizationInitFBD_Trunk_Sig_14 "contains Auth. Signal is encrypted, signal TAG not possible";
CM_ SG_ 553 LocalizationInitFBD_Trunk_Sig_15 "contains Auth. Signal is encrypted, signal TAG not possible";
CM_ SG_ 553 LocalizationInitFBD_Trunk_Rang_6 "contains Hopping Offset";
CM_ SG_ 553 LocalizationInitFBD_Trunk_Rang_7 "contains Hopping Offset";
CM_ SG_ 553 LocalizationInitFBD_Trunk_Rang_8 "contains Hopping Offset";
CM_ SG_ 553 LocalizationInitFBD_Trunk_Rang_9 "contains Hopping Offset";
CM_ SG_ 553 LocalizationInitFBD_Trunk_Ran_10 "contains Hopping Offset";
CM_ SG_ 554 LocalizationInitFBD_VL_IRKListIn "contains Session-ID";
CM_ SG_ 554 LocalizationInitFBD_VL_ZoneEntry "contains Zone transition";
CM_ SG_ 554 LocalizationInitFBD_VL_RangingBl "Frame Index of the latest ranging";
CM_ SG_ 554 LocalizationInitFBD_VL_TimeOfFli "ranging result in ps (PH) = (DEC) * 15.65";
CM_ SG_ 554 LocalizationInitFBD_VL_RSSI_0 "first path AoA";
CM_ SG_ 554 LocalizationInitFBD_VL_Ranging_2 "Frame Index of the second-to-last ranging";
CM_ SG_ 554 LocalizationInitFBD_VL_TimeOfF_2 "ranging result in ps (PH) = (DEC) * 15.65";
CM_ SG_ 554 LocalizationInitFBD_VL_RSSI_1 "first path AoA";
CM_ SG_ 554 LocalizationInitFBD_VL_Ranging_3 "Frame Index of the third-to-last ranging";
CM_ SG_ 554 LocalizationInitFBD_VL_TimeOfF_3 "ranging result in ps (PH) = (DEC) * 15.65";
CM_ SG_ 554 LocalizationInitFBD_VL_RSSI_2 "first path AoA";
CM_ SG_ 554 LocalizationInitFBD_VL_Ranging_4 "Frame Index of the fourth-last ranging";
CM_ SG_ 554 LocalizationInitFBD_VL_TimeOfF_4 "ranging result in ps (PH) = (DEC) * 15.65";
CM_ SG_ 554 LocalizationInitFBD_VL_RSSI_3 "first path AoA";
CM_ SG_ 554 LocalizationInitFBD_VL_Ranging_5 "Frame Index of the fifth-last ranging";
CM_ SG_ 554 LocalizationInitFBD_VL_TimeOfF_5 "ranging result in ps (PH) = (DEC) * 15.65";
CM_ SG_ 554 LocalizationInitFBD_VL_RSSI_4 "first path AoA";
CM_ SG_ 554 LocalizationInitFBD_VL_Sign_00 "contains Auth. Signal is encrypted, signal TAG not possible";
CM_ SG_ 554 LocalizationInitFBD_VL_Sign_01 "contains Auth. Signal is encrypted, signal TAG not possible";
CM_ SG_ 554 LocalizationInitFBD_VL_Sign_02 "contains Auth. Signal is encrypted, signal TAG not possible";
CM_ SG_ 554 LocalizationInitFBD_VL_Sign_03 "contains Auth. Signal is encrypted, signal TAG not possible";
CM_ SG_ 554 LocalizationInitFBD_VL_Sign_04 "contains Auth. Signal is encrypted, signal TAG not possible";
CM_ SG_ 554 LocalizationInitFBD_VL_Sign_05 "contains Auth. Signal is encrypted, signal TAG not possible";
CM_ SG_ 554 LocalizationInitFBD_VL_Sign_06 "contains Auth. Signal is encrypted, signal TAG not possible";
CM_ SG_ 554 LocalizationInitFBD_VL_Sign_07 "contains Auth. Signal is encrypted, signal TAG not possible";
CM_ SG_ 554 LocalizationInitFBD_VL_Sign_08 "contains Auth. Signal is encrypted, signal TAG not possible";
CM_ SG_ 554 LocalizationInitFBD_VL_Sign_09 "contains Auth. Signal is encrypted, signal TAG not possible";
CM_ SG_ 554 LocalizationInitFBD_VL_Sign_10 "contains Auth. Signal is encrypted, signal TAG not possible";
CM_ SG_ 554 LocalizationInitFBD_VL_Sign_11 "contains Auth. Signal is encrypted, signal TAG not possible";
CM_ SG_ 554 LocalizationInitFBD_VL_Sign_12 "contains Auth. Signal is encrypted, signal TAG not possible";
CM_ SG_ 554 LocalizationInitFBD_VL_Sign_13 "contains Auth. Signal is encrypted, signal TAG not possible";
CM_ SG_ 554 LocalizationInitFBD_VL_Sign_14 "contains Auth. Signal is encrypted, signal TAG not possible";
CM_ SG_ 554 LocalizationInitFBD_VL_Sign_15 "contains Auth. Signal is encrypted, signal TAG not possible";
CM_ SG_ 554 LocalizationInitFBD_VL_RangingRo "contains Hopping Offset";
CM_ SG_ 554 LocalizationInitFBD_VL_Ranging_6 "contains Hopping Offset";
CM_ SG_ 554 LocalizationInitFBD_VL_Ranging_7 "contains Hopping Offset";
CM_ SG_ 554 LocalizationInitFBD_VL_Ranging_8 "contains Hopping Offset";
CM_ SG_ 554 LocalizationInitFBD_VL_Ranging_9 "contains Hopping Offset";
CM_ SG_ 550 LocalizationInitFBD_VM_IRKListIn "contains Session-ID";
CM_ SG_ 550 LocalizationInitFBD_VM_ZoneEntry "contains Zone transition";
CM_ SG_ 550 LocalizationInitFBD_VM_RangingBl "Frame Index of the latest ranging";
CM_ SG_ 550 LocalizationInitFBD_VM_TimeOfFli "ranging result in ps (PH) = (DEC) * 15.65";
CM_ SG_ 550 LocalizationInitFBD_VM_RSSI_0 "first path AoA";
CM_ SG_ 550 LocalizationInitFBD_VM_Ranging_2 "Frame Index of the second-to-last ranging";
CM_ SG_ 550 LocalizationInitFBD_VM_TimeOfF_2 "ranging result in ps (PH) = (DEC) * 15.65";
CM_ SG_ 550 LocalizationInitFBD_VM_RSSI_1 "first path AoA";
CM_ SG_ 550 LocalizationInitFBD_VM_Ranging_3 "Frame Index of the third-to-last ranging";
CM_ SG_ 550 LocalizationInitFBD_VM_TimeOfF_3 "ranging result in ps (PH) = (DEC) * 15.65";
CM_ SG_ 550 LocalizationInitFBD_VM_RSSI_2 "first path AoA";
CM_ SG_ 550 LocalizationInitFBD_VM_Ranging_4 "Frame Index of the fourth-last ranging";
CM_ SG_ 550 LocalizationInitFBD_VM_TimeOfF_4 "ranging result in ps (PH) = (DEC) * 15.65";
CM_ SG_ 550 LocalizationInitFBD_VM_RSSI_3 "first path AoA";
CM_ SG_ 550 LocalizationInitFBD_VM_Ranging_5 "Frame Index of the fifth-last ranging";
CM_ SG_ 550 LocalizationInitFBD_VM_TimeOfF_5 "ranging result in ps (PH) = (DEC) * 15.65";
CM_ SG_ 550 LocalizationInitFBD_VM_RSSI_4 "first path AoA";
CM_ SG_ 550 LocalizationInitFBD_VM_Sign_00 "contains Auth. Signal is encrypted, signal TAG not possible";
CM_ SG_ 550 LocalizationInitFBD_VM_Sign_01 "contains Auth. Signal is encrypted, signal TAG not possible";
CM_ SG_ 550 LocalizationInitFBD_VM_Sign_02 "contains Auth. Signal is encrypted, signal TAG not possible";
CM_ SG_ 550 LocalizationInitFBD_VM_Sign_03 "contains Auth. Signal is encrypted, signal TAG not possible";
CM_ SG_ 550 LocalizationInitFBD_VM_Sign_04 "contains Auth. Signal is encrypted, signal TAG not possible";
CM_ SG_ 550 LocalizationInitFBD_VM_Sign_05 "contains Auth. Signal is encrypted, signal TAG not possible";
CM_ SG_ 550 LocalizationInitFBD_VM_Sign_06 "contains Auth. Signal is encrypted, signal TAG not possible";
CM_ SG_ 550 LocalizationInitFBD_VM_Sign_07 "contains Auth. Signal is encrypted, signal TAG not possible";
CM_ SG_ 550 LocalizationInitFBD_VM_Sign_08 "contains Auth. Signal is encrypted, signal TAG not possible";
CM_ SG_ 550 LocalizationInitFBD_VM_Sign_09 "contains Auth. Signal is encrypted, signal TAG not possible";
CM_ SG_ 550 LocalizationInitFBD_VM_Sign_10 "contains Auth. Signal is encrypted, signal TAG not possible";
CM_ SG_ 550 LocalizationInitFBD_VM_Sign_11 "contains Auth. Signal is encrypted, signal TAG not possible";
CM_ SG_ 550 LocalizationInitFBD_VM_Sign_12 "contains Auth. Signal is encrypted, signal TAG not possible";
CM_ SG_ 550 LocalizationInitFBD_VM_Sign_13 "contains Auth. Signal is encrypted, signal TAG not possible";
CM_ SG_ 550 LocalizationInitFBD_VM_Sign_14 "contains Auth. Signal is encrypted, signal TAG not possible";
CM_ SG_ 550 LocalizationInitFBD_VM_Sign_15 "contains Auth. Signal is encrypted, signal TAG not possible";
CM_ SG_ 550 LocalizationInitFBD_VM_RangingRo "contains Hopping Offset";
CM_ SG_ 550 LocalizationInitFBD_VM_Ranging_6 "contains Hopping Offset";
CM_ SG_ 550 LocalizationInitFBD_VM_Ranging_7 "contains Hopping Offset";
CM_ SG_ 550 LocalizationInitFBD_VM_Ranging_8 "contains Hopping Offset";
CM_ SG_ 550 LocalizationInitFBD_VM_Ranging_9 "contains Hopping Offset";
CM_ SG_ 555 LocalizationInitFBD_VR_IRKListIn "contains Session-ID";
CM_ SG_ 555 LocalizationInitFBD_VR_ZoneEntry "contains Zone transition";
CM_ SG_ 555 LocalizationInitFBD_VR_RangingBl "Frame Index of the latest ranging";
CM_ SG_ 555 LocalizationInitFBD_VR_TimeOfFli "ranging result in ps (PH) = (DEC) * 15.65";
CM_ SG_ 555 LocalizationInitFBD_VR_RSSI_0 "first path AoA";
CM_ SG_ 555 LocalizationInitFBD_VR_Ranging_2 "Frame Index of the second-to-last ranging";
CM_ SG_ 555 LocalizationInitFBD_VR_TimeOfF_2 "ranging result in ps (PH) = (DEC) * 15.65";
CM_ SG_ 555 LocalizationInitFBD_VR_RSSI_1 "first path AoA";
CM_ SG_ 555 LocalizationInitFBD_VR_Ranging_3 "Frame Index of the third-to-last ranging";
CM_ SG_ 555 LocalizationInitFBD_VR_TimeOfF_3 "ranging result in ps (PH) = (DEC) * 15.65";
CM_ SG_ 555 LocalizationInitFBD_VR_RSSI_2 "first path AoA";
CM_ SG_ 555 LocalizationInitFBD_VR_Ranging_4 "Frame Index of the fourth-last ranging";
CM_ SG_ 555 LocalizationInitFBD_VR_TimeOfF_4 "ranging result in ps (PH) = (DEC) * 15.65";
CM_ SG_ 555 LocalizationInitFBD_VR_RSSI_3 "first path AoA";
CM_ SG_ 555 LocalizationInitFBD_VR_Ranging_5 "Frame Index of the fifth-last ranging";
CM_ SG_ 555 LocalizationInitFBD_VR_TimeOfF_5 "ranging result in ps (PH) = (DEC) * 15.65";
CM_ SG_ 555 LocalizationInitFBD_VR_RSSI_4 "first path AoA";
CM_ SG_ 555 LocalizationInitFBD_VR_Sign_00 "contains Auth. Signal is encrypted, signal TAG not possible";
CM_ SG_ 555 LocalizationInitFBD_VR_Sign_01 "contains Auth. Signal is encrypted, signal TAG not possible";
CM_ SG_ 555 LocalizationInitFBD_VR_Sign_02 "contains Auth. Signal is encrypted, signal TAG not possible";
CM_ SG_ 555 LocalizationInitFBD_VR_Sign_03 "contains Auth. Signal is encrypted, signal TAG not possible";
CM_ SG_ 555 LocalizationInitFBD_VR_Sign_04 "contains Auth. Signal is encrypted, signal TAG not possible";
CM_ SG_ 555 LocalizationInitFBD_VR_Sign_05 "contains Auth. Signal is encrypted, signal TAG not possible";
CM_ SG_ 555 LocalizationInitFBD_VR_Sign_06 "contains Auth. Signal is encrypted, signal TAG not possible";
CM_ SG_ 555 LocalizationInitFBD_VR_Sign_07 "contains Auth. Signal is encrypted, signal TAG not possible";
CM_ SG_ 555 LocalizationInitFBD_VR_Sign_08 "contains Auth. Signal is encrypted, signal TAG not possible";
CM_ SG_ 555 LocalizationInitFBD_VR_Sign_09 "contains Auth. Signal is encrypted, signal TAG not possible";
CM_ SG_ 555 LocalizationInitFBD_VR_Sign_10 "contains Auth. Signal is encrypted, signal TAG not possible";
CM_ SG_ 555 LocalizationInitFBD_VR_Sign_11 "contains Auth. Signal is encrypted, signal TAG not possible";
CM_ SG_ 555 LocalizationInitFBD_VR_Sign_12 "contains Auth. Signal is encrypted, signal TAG not possible";
CM_ SG_ 555 LocalizationInitFBD_VR_Sign_13 "contains Auth. Signal is encrypted, signal TAG not possible";
CM_ SG_ 555 LocalizationInitFBD_VR_Sign_14 "contains Auth. Signal is encrypted, signal TAG not possible";
CM_ SG_ 555 LocalizationInitFBD_VR_Sign_15 "contains Auth. Signal is encrypted, signal TAG not possible";
CM_ SG_ 555 LocalizationInitFBD_VR_RangingRo "contains Hopping Offset";
CM_ SG_ 555 LocalizationInitFBD_VR_Ranging_6 "contains Hopping Offset";
CM_ SG_ 555 LocalizationInitFBD_VR_Ranging_7 "contains Hopping Offset";
CM_ SG_ 555 LocalizationInitFBD_VR_Ranging_8 "contains Hopping Offset";
CM_ SG_ 555 LocalizationInitFBD_VR_Ranging_9 "contains Hopping Offset";
CM_ SG_ 406 LocalizationInitRequest_Address "LocalizationInitRequest_Address";
CM_ SG_ 406 LocalizationInitRequest_SessionI "LocalizationInitRequest_SessionIDShort";
CM_ SG_ 406 LocalizationInitRequest_IRKListI "LocalizationInitRequest_IRKListIndex";
CM_ SG_ 406 LocalizationInitRequest_Auth00 "LocalizationInitRequest_Auth00";
CM_ SG_ 406 LocalizationInitRequest_Auth01 "LocalizationInitRequest_Auth01";
CM_ SG_ 406 LocalizationInitRequest_Auth02 "LocalizationInitRequest_Auth02";
CM_ SG_ 406 LocalizationInitRequest_Auth03 "LocalizationInitRequest_Auth03";
CM_ SG_ 406 LocalizationInitRequest_Auth04 "LocalizationInitRequest_Auth04";
CM_ SG_ 406 LocalizationInitRequest_Auth05 "LocalizationInitRequest_Auth05";
CM_ SG_ 406 LocalizationInitRequest_Auth06 "LocalizationInitRequest_Auth06";
CM_ SG_ 406 LocalizationInitRequest_Auth07 "LocalizationInitRequest_Auth07";
CM_ SG_ 406 LocalizationInitRequest_Auth08 "LocalizationInitRequest_Auth08";
CM_ SG_ 406 LocalizationInitRequest_Auth09 "LocalizationInitRequest_Auth09";
CM_ SG_ 406 LocalizationInitRequest_Auth10 "LocalizationInitRequest_Auth10";
CM_ SG_ 406 LocalizationInitRequest_Auth11 "LocalizationInitRequest_Auth11";
CM_ SG_ 406 LocalizationInitRequest_Auth12 "LocalizationInitRequest_Auth12";
CM_ SG_ 406 LocalizationInitRequest_Auth13 "LocalizationInitRequest_Auth13";
CM_ SG_ 406 LocalizationInitRequest_Auth14 "LocalizationInitRequest_Auth14";
CM_ SG_ 406 LocalizationInitRequest_Auth15 "LocalizationInitRequest_Auth15";
CM_ SG_ 999 LocalizationResult_IPB_Byte00 "Debug-Information_00";
CM_ SG_ 999 LocalizationResult_IPB_Byte01 "Debug-Information_01";
CM_ SG_ 999 LocalizationResult_IPB_Byte02 "Debug-Information_02";
CM_ SG_ 999 LocalizationResult_IPB_Byte03 "Debug-Information_03";
CM_ SG_ 999 LocalizationResult_IPB_Byte04 "Debug-Information_04";
CM_ SG_ 999 LocalizationResult_IPB_Byte05 "Debug-Information_05";
CM_ SG_ 999 LocalizationResult_IPB_Byte06 "Debug-Information_06";
CM_ SG_ 999 LocalizationResult_IPB_Byte07 "Debug-Information_07";
CM_ SG_ 999 LocalizationResult_IPB_Byte08 "Debug-Information_08";
CM_ SG_ 999 LocalizationResult_IPB_Byte09 "Debug-Information_09";
CM_ SG_ 999 LocalizationResult_IPB_Byte10 "Debug-Information_10";
CM_ SG_ 999 LocalizationResult_IPB_Byte11 "Debug-Information_11";
CM_ SG_ 999 LocalizationResult_IPB_Byte12 "Debug-Information_12";
CM_ SG_ 999 LocalizationResult_IPB_Byte13 "Debug-Information_13";
CM_ SG_ 999 LocalizationResult_IPB_Byte14 "Debug-Information_14";
CM_ SG_ 999 LocalizationResult_IPB_Byte15 "Debug-Information_15";
CM_ SG_ 999 LocalizationResult_IPB_Byte16 "Debug-Information_16";
CM_ SG_ 999 LocalizationResult_IPB_Byte17 "Debug-Information_17";
CM_ SG_ 999 LocalizationResult_IPB_Byte18 "Debug-Information_18";
CM_ SG_ 999 LocalizationResult_IPB_Byte19 "Debug-Information_19";
CM_ SG_ 999 LocalizationResult_IPB_Byte20 "Debug-Information_20";
CM_ SG_ 999 LocalizationResult_IPB_Byte21 "Debug-Information_21";
CM_ SG_ 999 LocalizationResult_IPB_Byte22 "Debug-Information_22";
CM_ SG_ 999 LocalizationResult_IPB_Byte23 "Debug-Information_23";
CM_ SG_ 999 LocalizationResult_IPB_Byte24 "Debug-Information_24";
CM_ SG_ 999 LocalizationResult_IPB_Byte25 "Debug-Information_25";
CM_ SG_ 999 LocalizationResult_IPB_Byte26 "Debug-Information_26";
CM_ SG_ 999 LocalizationResult_IPB_Byte27 "Debug-Information_27";
CM_ SG_ 999 LocalizationResult_IPB_Byte28 "Debug-Information_28";
CM_ SG_ 999 LocalizationResult_IPB_Byte29 "Debug-Information_29";
CM_ SG_ 999 LocalizationResult_IPB_Byte30 "Debug-Information_30";
CM_ SG_ 999 LocalizationResult_IPB_Byte31 "Debug-Information_31";
CM_ SG_ 998 MyWayTracking_IPB_SessionIDShort "SessionID of device";
CM_ SG_ 998 MyWayTracking_IPB_IRKListIndex "IRKListIndex of device";
CM_ SG_ 998 MyWayTracking_IPB_TrackingStatus "Tracking Staus of device: active, stopped";
CM_ SG_ 998 MyWayTracking_IPB_Classification "Classification";
CM_ SG_ 998 MyWayTracking_IPB_Intent "Intent";
CM_ SG_ 998 MyWayTracking_IPB_TimeRemaining "Time remaining";
CM_ SG_ 998 MyWayTracking_IPB_Target "Target: charging flap, trunk, driver door";
CM_ SG_ 606 RequestBindingStatusFBD_Address "addressing of the UWB anchors";
CM_ SG_ 606 RequestBindingStatusFBD_RequestS "contains request of binding data";
CM_ SG_ 384 RequestBLECSSession_Address "addressing of the BLE nodes";
CM_ SG_ 384 RequestBLECSSession_ID "defines the channel sounding session ID within the active connection";
CM_ SG_ 384 RequestBLECSSession_IRKListID "defines the connected BLE device";
CM_ SG_ 384 RequestBLECSSession_DeviceGroup "defines the device group";
CM_ SG_ 384 RequestBLECSSession_MainModeType "defines the main mode";
CM_ SG_ 384 RequestBLECSSession_SubModeType "defines the sub mode";
CM_ SG_ 384 RequestBLECSSession_MainModeRepe "defines the number of times the main mode is repeated";
CM_ SG_ 384 RequestBLECSSession_Mode0Steps "defines the number of Mode-0 steps (frequency calibration) at the start of each subevent";
CM_ SG_ 384 RequestBLECSSession_RTTType "defines the RTT type";
CM_ SG_ 384 RequestBLECSSession_CSSyncPHY "defines the used CS sync PHY";
CM_ SG_ 384 RequestBLECSSession_ChannelMap00 "bitmap where each bit corresponds to a channel (0-59). A bit value of 1 indicates the channel is enabled for Channel Sounding, while 0 indicates it is disabled";
CM_ SG_ 384 RequestBLECSSession_ChannelMap60 "bitmap where each bit corresponds to a channel (60-79). A bit value of 1 indicates the channel is enabled for Channel Sounding, while 0 indicates it is disabled";
CM_ SG_ 384 RequestBLECSSession_MaxProcedure "defines the maximum duration of the CS procedure (in 0.625 ms units)";
CM_ SG_ 384 RequestBLECSSession_MinProcedure "defines the time range between the start of consecutive CS procedures (in 0.625 ms units).";
CM_ SG_ 384 RequestBLECSSession_MaxProcedu_2 "efines the time range between the start of consecutive CS procedures (in 0.625 ms units).";
CM_ SG_ 384 RequestBLECSSession_MaxProcedu_3 "defines the number of CS procedures to be executed before the controller automatically disables them. Default is 1";
CM_ SG_ 384 RequestBLECSSession_ToneAntennaC "defines antenna configuration";
CM_ SG_ 384 RequestBLECSSession_BusCycleTime "defines how often the message StatusCSRangingFBD is sent";
CM_ SG_ 249 RequestBLEHandover_Address "addressing of the UWB anchors";
CM_ SG_ 249 RequestBLEHandover_ConnectionID "contains ConnectionID";
CM_ SG_ 249 RequestBLEHandover_SourceFBD "contains source FBD";
CM_ SG_ 249 RequestBLEHandover_TargetFBD "contains target FBD";
CM_ SG_ 249 RequestBLEHandover_Delay "time delay until handover must be finished (range: 0ms ... 252ms / step: 1ms)";
CM_ SG_ 249 RequestBLEHandover_Timeout "Timeout for handover (range: 0ms ... 65532ms / step: 1ms / 0 = default value)";
CM_ SG_ 203 RequestBLESettings_Address "addressing of the BLE TRX";
CM_ SG_ 203 RequestBLESettings_RequestSettin "request BLE Settings of FBD";
CM_ SG_ 601 RequestConfigurationStatusFBD_Ad "addressing of the UWB anchors";
CM_ SG_ 601 RequestConfigurationStatusFBD_Re "request actual configuration data";
CM_ SG_ 246 RequestConnectionRSSI_NumberAver "defines the number of averaging connection intervals";
CM_ SG_ 246 RequestConnectionRSSI_Activate "activate, deactivate";
CM_ SG_ 602 RequestCoordinates_Address "addressing of the UWB anchors";
CM_ SG_ 602 RequestCoordinates_RequestData "request coordinates of FBD";
CM_ SG_ 305 RequestCPDDataFBD_Address "addressing of the UWB anchors";
CM_ SG_ 305 RequestCPDDataFBD_SessionID "definition of Session-ID";
CM_ SG_ 305 RequestCPDDataFBD_Parameter1 "definition of parameter 1";
CM_ SG_ 305 RequestCPDDataFBD_Parameter2 "definition of parameter 2";
CM_ SG_ 305 RequestCPDDataFBD_Parameter3 "definition of parameter 3";
CM_ SG_ 305 RequestCPDDataFBD_Parameter4 "definition of parameter 4";
CM_ SG_ 305 RequestCPDDataFBD_Parameter5 "definition of parameter 5";
CM_ SG_ 405 RequestRangingSessionSign_Addres "addressing of the UWB anchors";
CM_ SG_ 405 RequestRangingSessionSign_Functi "contains function";
CM_ SG_ 405 RequestRangingSessionSign_IRKLis "definition of Session-ID";
CM_ SG_ 405 RequestRangingSessionSign_STSInd "contains STS-Index";
CM_ SG_ 405 RequestRangingSessionSign_Nonce "contains NONCE, only signal TAG 0xFF possible";
CM_ SG_ 266 RequestSeamlessBLEHandoverFBD_HL "contains ConnectionID";
CM_ SG_ 266 RequestSeamlessBLEHandoverFBD__2 "contains handover source";
CM_ SG_ 266 RequestSeamlessBLEHandoverFBD__3 "contains handover destination";
CM_ SG_ 266 RequestSeamlessBLEHandoverFBD__4 "contains the number of samples for RSSI averaging";
CM_ SG_ 266 RequestSeamlessBLEHandoverFBD__5 "contains the RSSI threeshold (Range: -127 ... -1 dB / step: 0.5dB)";
CM_ SG_ 266 RequestSeamlessBLEHandoverFBD__6 "contains the minimum RSSI difference (Range: 0 ... 127 dB / step: 0.5dB)";
CM_ SG_ 266 RequestSeamlessBLEHandoverFBD__7 "contains maximal handover time (range: 0ms ... 252ms / step: 1ms)";
CM_ SG_ 261 RequestSeamlessBLEHandoverFBD_HM "contains ConnectionID";
CM_ SG_ 261 RequestSeamlessBLEHandoverFBD__2 "contains handover source";
CM_ SG_ 261 RequestSeamlessBLEHandoverFBD__3 "contains handover destination";
CM_ SG_ 261 RequestSeamlessBLEHandoverFBD__4 "contains the number of samples for RSSI averaging";
CM_ SG_ 261 RequestSeamlessBLEHandoverFBD__5 "contains the RSSI threeshold (Range: -127 ... -1 dB / step: 0.5dB)";
CM_ SG_ 261 RequestSeamlessBLEHandoverFBD__6 "contains the minimum RSSI difference (Range: 0 ... 127 dB / step: 0.5dB)";
CM_ SG_ 261 RequestSeamlessBLEHandoverFBD__7 "contains maximal handover time (range: 0ms ... 252ms / step: 1ms)";
CM_ SG_ 267 RequestSeamlessBLEHandoverFBD_HR "contains ConnectionID";
CM_ SG_ 267 RequestSeamlessBLEHandoverFBD__2 "contains handover source";
CM_ SG_ 267 RequestSeamlessBLEHandoverFBD__3 "contains handover destination";
CM_ SG_ 267 RequestSeamlessBLEHandoverFBD__4 "contains the number of samples for RSSI averaging";
CM_ SG_ 267 RequestSeamlessBLEHandoverFBD__5 "contains the RSSI threeshold (Range: -127 ... -1 dB / step: 0.5dB)";
CM_ SG_ 267 RequestSeamlessBLEHandoverFBD__6 "contains the minimum RSSI difference (Range: 0 ... 127 dB / step: 0.5dB)";
CM_ SG_ 267 RequestSeamlessBLEHandoverFBD__7 "contains maximal handover time (range: 0ms ... 252ms / step: 1ms)";
CM_ SG_ 262 RequestSeamlessBLEHandoverFBD_Mi "contains ConnectionID";
CM_ SG_ 262 RequestSeamlessBLEHandoverFBD__2 "contains handover source";
CM_ SG_ 262 RequestSeamlessBLEHandoverFBD__3 "contains handover destination";
CM_ SG_ 262 RequestSeamlessBLEHandoverFBD__4 "contains the number of samples for RSSI averaging";
CM_ SG_ 262 RequestSeamlessBLEHandoverFBD__5 "contains the RSSI threeshold (Range: -127 ... -1 dB / step: 0.5dB)";
CM_ SG_ 262 RequestSeamlessBLEHandoverFBD__6 "contains the minimum RSSI difference (Range: 0 ... 127 dB / step: 0.5dB)";
CM_ SG_ 262 RequestSeamlessBLEHandoverFBD__7 "contains maximal handover time (range: 0ms ... 252ms / step: 1ms)";
CM_ SG_ 821 RequestSeamlessBLEHandoverFBD_MM "contains ConnectionID";
CM_ SG_ 821 RequestSeamlessBLEHandoverFBD__2 "contains handover source";
CM_ SG_ 821 RequestSeamlessBLEHandoverFBD__3 "contains handover destination";
CM_ SG_ 821 RequestSeamlessBLEHandoverFBD__4 "contains the number of samples for RSSI averaging";
CM_ SG_ 821 RequestSeamlessBLEHandoverFBD__5 "contains the RSSI threeshold (Range: -127 ... -1 dB / step: 0.5dB)";
CM_ SG_ 821 RequestSeamlessBLEHandoverFBD__6 "contains the minimum RSSI difference (Range: 0 ... 127 dB / step: 0.5dB)";
CM_ SG_ 821 RequestSeamlessBLEHandoverFBD__7 "contains maximal handover time (range: 0ms ... 252ms / step: 1ms)";
CM_ SG_ 263 RequestSeamlessBLEHandoverFBD_Tr "contains ConnectionID";
CM_ SG_ 263 RequestSeamlessBLEHandoverFBD__2 "contains handover source";
CM_ SG_ 263 RequestSeamlessBLEHandoverFBD__3 "contains handover destination";
CM_ SG_ 263 RequestSeamlessBLEHandoverFBD__4 "contains the number of samples for RSSI averaging";
CM_ SG_ 263 RequestSeamlessBLEHandoverFBD__5 "contains the RSSI threeshold (Range: -127 ... -1 dB / step: 0.5dB)";
CM_ SG_ 263 RequestSeamlessBLEHandoverFBD__6 "contains the minimum RSSI difference (Range: 0 ... 127 dB / step: 0.5dB)";
CM_ SG_ 263 RequestSeamlessBLEHandoverFBD__7 "contains maximal handover time (range: 0ms ... 252ms / step: 1ms)";
CM_ SG_ 264 RequestSeamlessBLEHandoverFBD_VL "contains ConnectionID";
CM_ SG_ 264 RequestSeamlessBLEHandoverFBD__2 "contains handover source";
CM_ SG_ 264 RequestSeamlessBLEHandoverFBD__3 "contains handover destination";
CM_ SG_ 264 RequestSeamlessBLEHandoverFBD__4 "contains the number of samples for RSSI averaging";
CM_ SG_ 264 RequestSeamlessBLEHandoverFBD__5 "contains the RSSI threeshold (Range: -127 ... -1 dB / step: 0.5dB)";
CM_ SG_ 264 RequestSeamlessBLEHandoverFBD__6 "contains the minimum RSSI difference (Range: 0 ... 127 dB / step: 0.5dB)";
CM_ SG_ 264 RequestSeamlessBLEHandoverFBD__7 "contains maximal handover time (range: 0ms ... 252ms / step: 1ms)";
CM_ SG_ 260 RequestSeamlessBLEHandoverFBD_VM "contains ConnectionID";
CM_ SG_ 260 RequestSeamlessBLEHandoverFBD__2 "contains handover source";
CM_ SG_ 260 RequestSeamlessBLEHandoverFBD__3 "contains handover destination";
CM_ SG_ 260 RequestSeamlessBLEHandoverFBD__4 "contains the number of samples for RSSI averaging";
CM_ SG_ 260 RequestSeamlessBLEHandoverFBD__5 "contains the RSSI threeshold (Range: -127 ... -1 dB / step: 0.5dB)";
CM_ SG_ 260 RequestSeamlessBLEHandoverFBD__6 "contains the minimum RSSI difference (Range: 0 ... 127 dB / step: 0.5dB)";
CM_ SG_ 260 RequestSeamlessBLEHandoverFBD__7 "contains maximal handover time (range: 0ms ... 252ms / step: 1ms)";
CM_ SG_ 265 RequestSeamlessBLEHandoverFBD_VR "contains ConnectionID";
CM_ SG_ 265 RequestSeamlessBLEHandoverFBD__2 "contains handover source";
CM_ SG_ 265 RequestSeamlessBLEHandoverFBD__3 "contains handover destination";
CM_ SG_ 265 RequestSeamlessBLEHandoverFBD__4 "contains the number of samples for RSSI averaging";
CM_ SG_ 265 RequestSeamlessBLEHandoverFBD__5 "contains the RSSI threeshold (Range: -127 ... -1 dB / step: 0.5dB)";
CM_ SG_ 265 RequestSeamlessBLEHandoverFBD__6 "contains the minimum RSSI difference (Range: 0 ... 127 dB / step: 0.5dB)";
CM_ SG_ 265 RequestSeamlessBLEHandoverFBD__7 "contains maximal handover time (range: 0ms ... 252ms / step: 1ms)";
CM_ SG_ 316 ResultBLE_Request_TxpowerFBD_HL_ "contains Connection Index";
CM_ SG_ 316 ResultBLE_Request_TxpowerFBD_H_2 "Tx Power in dBm";
CM_ SG_ 316 ResultBLE_Request_TxpowerFBD_H_3 "Path loss in dB";
CM_ SG_ 311 ResultBLE_Request_TxpowerFBD_HM_ "contains Connection Index";
CM_ SG_ 311 ResultBLE_Request_TxpowerFBD_H_2 "Tx Power in dBm";
CM_ SG_ 311 ResultBLE_Request_TxpowerFBD_H_3 "Path loss in dB";
CM_ SG_ 317 ResultBLE_Request_TxpowerFBD_HR_ "contains Connection Index";
CM_ SG_ 317 ResultBLE_Request_TxpowerFBD_H_2 "Tx Power in dBm";
CM_ SG_ 317 ResultBLE_Request_TxpowerFBD_H_3 "Path loss in dB";
CM_ SG_ 312 ResultBLE_Request_TxpowerFBD_Mik "contains Connection Index";
CM_ SG_ 312 ResultBLE_Request_TxpowerFBD_M_2 "Tx Power in dBm";
CM_ SG_ 312 ResultBLE_Request_TxpowerFBD_M_3 "Path loss in dB";
CM_ SG_ 318 ResultBLE_Request_TxpowerFBD_MM_ "contains Connection Index";
CM_ SG_ 318 ResultBLE_Request_TxpowerFBD_M_2 "Tx Power in dBm";
CM_ SG_ 318 ResultBLE_Request_TxpowerFBD_M_3 "Path loss in dB";
CM_ SG_ 313 ResultBLE_Request_TxpowerFBD_Tru "contains Connection Index";
CM_ SG_ 313 ResultBLE_Request_TxpowerFBD_T_2 "Tx Power in dBm";
CM_ SG_ 313 ResultBLE_Request_TxpowerFBD_T_3 "Path loss in dB";
CM_ SG_ 314 ResultBLE_Request_TxpowerFBD_VL_ "contains Connection Index";
CM_ SG_ 314 ResultBLE_Request_TxpowerFBD_V_2 "Tx Power in dBm";
CM_ SG_ 314 ResultBLE_Request_TxpowerFBD_V_3 "Path loss in dB";
CM_ SG_ 310 ResultBLE_Request_TxpowerFBD_VM_ "contains Connection Index";
CM_ SG_ 310 ResultBLE_Request_TxpowerFBD_V_2 "Tx Power in dBm";
CM_ SG_ 310 ResultBLE_Request_TxpowerFBD_V_3 "Path loss in dB";
CM_ SG_ 315 ResultBLE_Request_TxpowerFBD_VR_ "contains Connection Index";
CM_ SG_ 315 ResultBLE_Request_TxpowerFBD_V_2 "Tx Power in dBm";
CM_ SG_ 315 ResultBLE_Request_TxpowerFBD_V_3 "Path loss in dB";
CM_ SG_ 296 ResultBLEConMonitoringFBD_HL_IRK "contains ConnectionID";
CM_ SG_ 296 ResultBLEConMonitoringFBD_HL_RSS "contains the BLE RSSI level (Range: -127 ... -1 dB / step: 0.5dB)";
CM_ SG_ 296 ResultBLEConMonitoringFBD_HL_con "the BLE connection event counter";
CM_ SG_ 296 ResultBLEConMonitoringFBD_HL_Ch_ "The RF channel number";
CM_ SG_ 296 ResultBLEConMonitoringFBD_HL_Dev "The RF channel quality";
CM_ SG_ 296 ResultBLEConMonitoringFBD_HL_R_2 "contains the BLE RSSI level (Range: -127 ... -1 dB / step: 0.5dB)";
CM_ SG_ 296 ResultBLEConMonitoringFBD_HL_c_2 "the BLE connection event counter";
CM_ SG_ 296 ResultBLEConMonitoringFBD_HL_C_2 "The RF channel number";
CM_ SG_ 296 ResultBLEConMonitoringFBD_HL_C_3 "The RF channel quality";
CM_ SG_ 296 ResultBLEConMonitoringFBD_HL_R_3 "contains the BLE RSSI level (Range: -127 ... -1 dB / step: 0.5dB)";
CM_ SG_ 296 ResultBLEConMonitoringFBD_HL_c_3 "the BLE connection event counter";
CM_ SG_ 296 ResultBLEConMonitoringFBD_HL_C_4 "The RF channel number";
CM_ SG_ 296 ResultBLEConMonitoringFBD_HL_C_5 "The RF channel quality";
CM_ SG_ 296 ResultBLEConMonitoringFBD_HL_R_4 "contains the BLE RSSI level (Range: -127 ... -1 dB / step: 0.5dB)";
CM_ SG_ 296 ResultBLEConMonitoringFBD_HL_c_4 "the BLE connection event counter";
CM_ SG_ 296 ResultBLEConMonitoringFBD_HL_C_6 "The RF channel number";
CM_ SG_ 296 ResultBLEConMonitoringFBD_HL_C_7 "The RF channel quality";
CM_ SG_ 296 ResultBLEConMonitoringFBD_HL_R_5 "contains the BLE RSSI level (Range: -127 ... -1 dB / step: 0.5dB)";
CM_ SG_ 296 ResultBLEConMonitoringFBD_HL_c_5 "the BLE connection event counter";
CM_ SG_ 296 ResultBLEConMonitoringFBD_HL_C_8 "The RF channel number";
CM_ SG_ 296 ResultBLEConMonitoringFBD_HL_C_9 "The RF channel quality";
CM_ SG_ 296 ResultBLEConMonitoringFBD_HL_R_6 "contains the BLE RSSI level (Range: -127 ... -1 dB / step: 0.5dB)";
CM_ SG_ 296 ResultBLEConMonitoringFBD_HL_c_6 "the BLE connection event counter";
CM_ SG_ 296 ResultBLEConMonitoringFBD_HL__10 "The RF channel number";
CM_ SG_ 296 ResultBLEConMonitoringFBD_HL__11 "The RF channel quality";
CM_ SG_ 296 ResultBLEConMonitoringFBD_HL_R_7 "contains the BLE RSSI level (Range: -127 ... -1 dB / step: 0.5dB)";
CM_ SG_ 296 ResultBLEConMonitoringFBD_HL_c_7 "the BLE connection event counter";
CM_ SG_ 296 ResultBLEConMonitoringFBD_HL__12 "The RF channel number";
CM_ SG_ 296 ResultBLEConMonitoringFBD_HL__13 "The RF channel quality";
CM_ SG_ 296 ResultBLEConMonitoringFBD_HL_R_8 "contains the BLE RSSI level (Range: -127 ... -1 dB / step: 0.5dB)";
CM_ SG_ 296 ResultBLEConMonitoringFBD_HL_c_8 "the BLE connection event counter";
CM_ SG_ 296 ResultBLEConMonitoringFBD_HL__14 "The RF channel number";
CM_ SG_ 296 ResultBLEConMonitoringFBD_HL__15 "The RF channel quality";
CM_ SG_ 296 ResultBLEConMonitoringFBD_HL_R_9 "contains the BLE RSSI level (Range: -127 ... -1 dB / step: 0.5dB)";
CM_ SG_ 296 ResultBLEConMonitoringFBD_HL_c_9 "the BLE connection event counter";
CM_ SG_ 296 ResultBLEConMonitoringFBD_HL__16 "The RF channel number";
CM_ SG_ 296 ResultBLEConMonitoringFBD_HL__17 "The RF channel quality";
CM_ SG_ 296 ResultBLEConMonitoringFBD_HL__18 "contains the BLE RSSI level (Range: -127 ... -1 dB / step: 0.5dB)";
CM_ SG_ 296 ResultBLEConMonitoringFBD_HL__19 "the BLE connection event counter";
CM_ SG_ 296 ResultBLEConMonitoringFBD_HL__20 "The RF channel number";
CM_ SG_ 296 ResultBLEConMonitoringFBD_HL__21 "The RF channel quality";
CM_ SG_ 296 ResultBLEConMonitoringFBD_HL_IV0 "contains IV to signature";
CM_ SG_ 296 ResultBLEConMonitoringFBD_HL_I_2 "contains IV to signature";
CM_ SG_ 296 ResultBLEConMonitoringFBD_HL_I_3 "contains IV to signature";
CM_ SG_ 296 ResultBLEConMonitoringFBD_HL_I_4 "contains IV to signature";
CM_ SG_ 296 ResultBLEConMonitoringFBD_HL_Sig "contains signature";
CM_ SG_ 296 ResultBLEConMonitoringFBD_HL_S_2 "contains signature";
CM_ SG_ 296 ResultBLEConMonitoringFBD_HL_S_3 "contains signature";
CM_ SG_ 296 ResultBLEConMonitoringFBD_HL_S_4 "contains signature";
CM_ SG_ 296 ResultBLEConMonitoringFBD_HL_S_5 "contains signature";
CM_ SG_ 296 ResultBLEConMonitoringFBD_HL_S_6 "contains signature";
CM_ SG_ 296 ResultBLEConMonitoringFBD_HL_S_7 "contains signature";
CM_ SG_ 296 ResultBLEConMonitoringFBD_HL_S_8 "contains signature";
CM_ SG_ 291 ResultBLEConMonitoringFBD_HM_IRK "contains ConnectionID";
CM_ SG_ 291 ResultBLEConMonitoringFBD_HM_RSS "contains the BLE RSSI level (Range: -127 ... -1 dB / step: 0.5dB)";
CM_ SG_ 291 ResultBLEConMonitoringFBD_HM_con "the BLE connection event counter";
CM_ SG_ 291 ResultBLEConMonitoringFBD_HM_Ch_ "The RF channel number";
CM_ SG_ 291 ResultBLEConMonitoringFBD_HM_Dev "The RF channel quality";
CM_ SG_ 291 ResultBLEConMonitoringFBD_HM_R_2 "contains the BLE RSSI level (Range: -127 ... -1 dB / step: 0.5dB)";
CM_ SG_ 291 ResultBLEConMonitoringFBD_HM_c_2 "the BLE connection event counter";
CM_ SG_ 291 ResultBLEConMonitoringFBD_HM_C_2 "The RF channel number";
CM_ SG_ 291 ResultBLEConMonitoringFBD_HM_C_3 "The RF channel quality";
CM_ SG_ 291 ResultBLEConMonitoringFBD_HM_R_3 "contains the BLE RSSI level (Range: -127 ... -1 dB / step: 0.5dB)";
CM_ SG_ 291 ResultBLEConMonitoringFBD_HM_c_3 "the BLE connection event counter";
CM_ SG_ 291 ResultBLEConMonitoringFBD_HM_C_4 "The RF channel number";
CM_ SG_ 291 ResultBLEConMonitoringFBD_HM_C_5 "The RF channel quality";
CM_ SG_ 291 ResultBLEConMonitoringFBD_HM_R_4 "contains the BLE RSSI level (Range: -127 ... -1 dB / step: 0.5dB)";
CM_ SG_ 291 ResultBLEConMonitoringFBD_HM_c_4 "the BLE connection event counter";
CM_ SG_ 291 ResultBLEConMonitoringFBD_HM_C_6 "The RF channel number";
CM_ SG_ 291 ResultBLEConMonitoringFBD_HM_C_7 "The RF channel quality";
CM_ SG_ 291 ResultBLEConMonitoringFBD_HM_R_5 "contains the BLE RSSI level (Range: -127 ... -1 dB / step: 0.5dB)";
CM_ SG_ 291 ResultBLEConMonitoringFBD_HM_c_5 "the BLE connection event counter";
CM_ SG_ 291 ResultBLEConMonitoringFBD_HM_C_8 "The RF channel number";
CM_ SG_ 291 ResultBLEConMonitoringFBD_HM_C_9 "The RF channel quality";
CM_ SG_ 291 ResultBLEConMonitoringFBD_HM_R_6 "contains the BLE RSSI level (Range: -127 ... -1 dB / step: 0.5dB)";
CM_ SG_ 291 ResultBLEConMonitoringFBD_HM_c_6 "the BLE connection event counter";
CM_ SG_ 291 ResultBLEConMonitoringFBD_HM__10 "The RF channel number";
CM_ SG_ 291 ResultBLEConMonitoringFBD_HM__11 "The RF channel quality";
CM_ SG_ 291 ResultBLEConMonitoringFBD_HM_R_7 "contains the BLE RSSI level (Range: -127 ... -1 dB / step: 0.5dB)";
CM_ SG_ 291 ResultBLEConMonitoringFBD_HM_c_7 "the BLE connection event counter";
CM_ SG_ 291 ResultBLEConMonitoringFBD_HM__12 "The RF channel number";
CM_ SG_ 291 ResultBLEConMonitoringFBD_HM__13 "The RF channel quality";
CM_ SG_ 291 ResultBLEConMonitoringFBD_HM_R_8 "contains the BLE RSSI level (Range: -127 ... -1 dB / step: 0.5dB)";
CM_ SG_ 291 ResultBLEConMonitoringFBD_HM_c_8 "the BLE connection event counter";
CM_ SG_ 291 ResultBLEConMonitoringFBD_HM__14 "The RF channel number";
CM_ SG_ 291 ResultBLEConMonitoringFBD_HM__15 "The RF channel quality";
CM_ SG_ 291 ResultBLEConMonitoringFBD_HM_R_9 "contains the BLE RSSI level (Range: -127 ... -1 dB / step: 0.5dB)";
CM_ SG_ 291 ResultBLEConMonitoringFBD_HM_c_9 "the BLE connection event counter";
CM_ SG_ 291 ResultBLEConMonitoringFBD_HM__16 "The RF channel number";
CM_ SG_ 291 ResultBLEConMonitoringFBD_HM__17 "The RF channel quality";
CM_ SG_ 291 ResultBLEConMonitoringFBD_HM__18 "contains the BLE RSSI level (Range: -127 ... -1 dB / step: 0.5dB)";
CM_ SG_ 291 ResultBLEConMonitoringFBD_HM__19 "the BLE connection event counter";
CM_ SG_ 291 ResultBLEConMonitoringFBD_HM__20 "The RF channel number";
CM_ SG_ 291 ResultBLEConMonitoringFBD_HM__21 "The RF channel quality";
CM_ SG_ 291 ResultBLEConMonitoringFBD_HM_IV0 "contains IV to signature";
CM_ SG_ 291 ResultBLEConMonitoringFBD_HM_I_2 "contains IV to signature";
CM_ SG_ 291 ResultBLEConMonitoringFBD_HM_I_3 "contains IV to signature";
CM_ SG_ 291 ResultBLEConMonitoringFBD_HM_I_4 "contains IV to signature";
CM_ SG_ 291 ResultBLEConMonitoringFBD_HM_Sig "contains signature";
CM_ SG_ 291 ResultBLEConMonitoringFBD_HM_S_2 "contains signature";
CM_ SG_ 291 ResultBLEConMonitoringFBD_HM_S_3 "contains signature";
CM_ SG_ 291 ResultBLEConMonitoringFBD_HM_S_4 "contains signature";
CM_ SG_ 291 ResultBLEConMonitoringFBD_HM_S_5 "contains signature";
CM_ SG_ 291 ResultBLEConMonitoringFBD_HM_S_6 "contains signature";
CM_ SG_ 291 ResultBLEConMonitoringFBD_HM_S_7 "contains signature";
CM_ SG_ 291 ResultBLEConMonitoringFBD_HM_S_8 "contains signature";
CM_ SG_ 297 ResultBLEConMonitoringFBD_HR_IRK "contains ConnectionID";
CM_ SG_ 297 ResultBLEConMonitoringFBD_HR_RSS "contains the BLE RSSI level (Range: -127 ... -1 dB / step: 0.5dB)";
CM_ SG_ 297 ResultBLEConMonitoringFBD_HR_con "the BLE connection event counter";
CM_ SG_ 297 ResultBLEConMonitoringFBD_HR_Ch_ "The RF channel number";
CM_ SG_ 297 ResultBLEConMonitoringFBD_HR_Dev "The RF channel quality";
CM_ SG_ 297 ResultBLEConMonitoringFBD_HR_R_2 "contains the BLE RSSI level (Range: -127 ... -1 dB / step: 0.5dB)";
CM_ SG_ 297 ResultBLEConMonitoringFBD_HR_c_2 "the BLE connection event counter";
CM_ SG_ 297 ResultBLEConMonitoringFBD_HR_C_2 "The RF channel number";
CM_ SG_ 297 ResultBLEConMonitoringFBD_HR_C_3 "The RF channel quality";
CM_ SG_ 297 ResultBLEConMonitoringFBD_HR_R_3 "contains the BLE RSSI level (Range: -127 ... -1 dB / step: 0.5dB)";
CM_ SG_ 297 ResultBLEConMonitoringFBD_HR_c_3 "the BLE connection event counter";
CM_ SG_ 297 ResultBLEConMonitoringFBD_HR_C_4 "The RF channel number";
CM_ SG_ 297 ResultBLEConMonitoringFBD_HR_C_5 "The RF channel quality";
CM_ SG_ 297 ResultBLEConMonitoringFBD_HR_R_4 "contains the BLE RSSI level (Range: -127 ... -1 dB / step: 0.5dB)";
CM_ SG_ 297 ResultBLEConMonitoringFBD_HR_c_4 "the BLE connection event counter";
CM_ SG_ 297 ResultBLEConMonitoringFBD_HR_C_6 "The RF channel number";
CM_ SG_ 297 ResultBLEConMonitoringFBD_HR_C_7 "The RF channel quality";
CM_ SG_ 297 ResultBLEConMonitoringFBD_HR_R_5 "contains the BLE RSSI level (Range: -127 ... -1 dB / step: 0.5dB)";
CM_ SG_ 297 ResultBLEConMonitoringFBD_HR_c_5 "the BLE connection event counter";
CM_ SG_ 297 ResultBLEConMonitoringFBD_HR_C_8 "The RF channel number";
CM_ SG_ 297 ResultBLEConMonitoringFBD_HR_C_9 "The RF channel quality";
CM_ SG_ 297 ResultBLEConMonitoringFBD_HR_R_6 "contains the BLE RSSI level (Range: -127 ... -1 dB / step: 0.5dB)";
CM_ SG_ 297 ResultBLEConMonitoringFBD_HR_c_6 "the BLE connection event counter";
CM_ SG_ 297 ResultBLEConMonitoringFBD_HR__10 "The RF channel number";
CM_ SG_ 297 ResultBLEConMonitoringFBD_HR__11 "The RF channel quality";
CM_ SG_ 297 ResultBLEConMonitoringFBD_HR_R_7 "contains the BLE RSSI level (Range: -127 ... -1 dB / step: 0.5dB)";
CM_ SG_ 297 ResultBLEConMonitoringFBD_HR_c_7 "the BLE connection event counter";
CM_ SG_ 297 ResultBLEConMonitoringFBD_HR__12 "The RF channel number";
CM_ SG_ 297 ResultBLEConMonitoringFBD_HR__13 "The RF channel quality";
CM_ SG_ 297 ResultBLEConMonitoringFBD_HR_R_8 "contains the BLE RSSI level (Range: -127 ... -1 dB / step: 0.5dB)";
CM_ SG_ 297 ResultBLEConMonitoringFBD_HR_c_8 "the BLE connection event counter";
CM_ SG_ 297 ResultBLEConMonitoringFBD_HR__14 "The RF channel number";
CM_ SG_ 297 ResultBLEConMonitoringFBD_HR__15 "The RF channel quality";
CM_ SG_ 297 ResultBLEConMonitoringFBD_HR_R_9 "contains the BLE RSSI level (Range: -127 ... -1 dB / step: 0.5dB)";
CM_ SG_ 297 ResultBLEConMonitoringFBD_HR_c_9 "the BLE connection event counter";
CM_ SG_ 297 ResultBLEConMonitoringFBD_HR__16 "The RF channel number";
CM_ SG_ 297 ResultBLEConMonitoringFBD_HR__17 "The RF channel quality";
CM_ SG_ 297 ResultBLEConMonitoringFBD_HR__18 "contains the BLE RSSI level (Range: -127 ... -1 dB / step: 0.5dB)";
CM_ SG_ 297 ResultBLEConMonitoringFBD_HR__19 "the BLE connection event counter";
CM_ SG_ 297 ResultBLEConMonitoringFBD_HR__20 "The RF channel number";
CM_ SG_ 297 ResultBLEConMonitoringFBD_HR__21 "The RF channel quality";
CM_ SG_ 297 ResultBLEConMonitoringFBD_HR_IV0 "contains IV to signature";
CM_ SG_ 297 ResultBLEConMonitoringFBD_HR_I_2 "contains IV to signature";
CM_ SG_ 297 ResultBLEConMonitoringFBD_HR_I_3 "contains IV to signature";
CM_ SG_ 297 ResultBLEConMonitoringFBD_HR_I_4 "contains IV to signature";
CM_ SG_ 297 ResultBLEConMonitoringFBD_HR_Sig "contains signature";
CM_ SG_ 297 ResultBLEConMonitoringFBD_HR_S_2 "contains signature";
CM_ SG_ 297 ResultBLEConMonitoringFBD_HR_S_3 "contains signature";
CM_ SG_ 297 ResultBLEConMonitoringFBD_HR_S_4 "contains signature";
CM_ SG_ 297 ResultBLEConMonitoringFBD_HR_S_5 "contains signature";
CM_ SG_ 297 ResultBLEConMonitoringFBD_HR_S_6 "contains signature";
CM_ SG_ 297 ResultBLEConMonitoringFBD_HR_S_7 "contains signature";
CM_ SG_ 297 ResultBLEConMonitoringFBD_HR_S_8 "contains signature";
CM_ SG_ 292 ResultBLEConMonitoringFBD_Miko_I "contains ConnectionID";
CM_ SG_ 292 ResultBLEConMonitoringFBD_Miko_R "contains the BLE RSSI level (Range: -127 ... -1 dB / step: 0.5dB)";
CM_ SG_ 292 ResultBLEConMonitoringFBD_Miko_c "the BLE connection event counter";
CM_ SG_ 292 ResultBLEConMonitoringFBD_Miko_C "The RF channel number";
CM_ SG_ 292 ResultBLEConMonitoringFBD_Miko_D "The RF channel quality";
CM_ SG_ 292 ResultBLEConMonitoringFBD_Miko_2 "contains the BLE RSSI level (Range: -127 ... -1 dB / step: 0.5dB)";
CM_ SG_ 292 ResultBLEConMonitoringFBD_Miko_3 "the BLE connection event counter";
CM_ SG_ 292 ResultBLEConMonitoringFBD_Miko_4 "The RF channel number";
CM_ SG_ 292 ResultBLEConMonitoringFBD_Miko_5 "The RF channel quality";
CM_ SG_ 292 ResultBLEConMonitoringFBD_Miko_6 "contains the BLE RSSI level (Range: -127 ... -1 dB / step: 0.5dB)";
CM_ SG_ 292 ResultBLEConMonitoringFBD_Miko_7 "the BLE connection event counter";
CM_ SG_ 292 ResultBLEConMonitoringFBD_Miko_8 "The RF channel number";
CM_ SG_ 292 ResultBLEConMonitoringFBD_Miko_9 "The RF channel quality";
CM_ SG_ 292 ResultBLEConMonitoringFBD_Mik_10 "contains the BLE RSSI level (Range: -127 ... -1 dB / step: 0.5dB)";
CM_ SG_ 292 ResultBLEConMonitoringFBD_Mik_11 "the BLE connection event counter";
CM_ SG_ 292 ResultBLEConMonitoringFBD_Mik_12 "The RF channel number";
CM_ SG_ 292 ResultBLEConMonitoringFBD_Mik_13 "The RF channel quality";
CM_ SG_ 292 ResultBLEConMonitoringFBD_Mik_14 "contains the BLE RSSI level (Range: -127 ... -1 dB / step: 0.5dB)";
CM_ SG_ 292 ResultBLEConMonitoringFBD_Mik_15 "the BLE connection event counter";
CM_ SG_ 292 ResultBLEConMonitoringFBD_Mik_16 "The RF channel number";
CM_ SG_ 292 ResultBLEConMonitoringFBD_Mik_17 "The RF channel quality";
CM_ SG_ 292 ResultBLEConMonitoringFBD_Mik_18 "contains the BLE RSSI level (Range: -127 ... -1 dB / step: 0.5dB)";
CM_ SG_ 292 ResultBLEConMonitoringFBD_Mik_19 "the BLE connection event counter";
CM_ SG_ 292 ResultBLEConMonitoringFBD_Mik_20 "The RF channel number";
CM_ SG_ 292 ResultBLEConMonitoringFBD_Mik_21 "The RF channel quality";
CM_ SG_ 292 ResultBLEConMonitoringFBD_Mik_22 "contains the BLE RSSI level (Range: -127 ... -1 dB / step: 0.5dB)";
CM_ SG_ 292 ResultBLEConMonitoringFBD_Mik_23 "the BLE connection event counter";
CM_ SG_ 292 ResultBLEConMonitoringFBD_Mik_24 "The RF channel number";
CM_ SG_ 292 ResultBLEConMonitoringFBD_Mik_25 "The RF channel quality";
CM_ SG_ 292 ResultBLEConMonitoringFBD_Mik_26 "contains the BLE RSSI level (Range: -127 ... -1 dB / step: 0.5dB)";
CM_ SG_ 292 ResultBLEConMonitoringFBD_Mik_27 "the BLE connection event counter";
CM_ SG_ 292 ResultBLEConMonitoringFBD_Mik_28 "The RF channel number";
CM_ SG_ 292 ResultBLEConMonitoringFBD_Mik_29 "The RF channel quality";
CM_ SG_ 292 ResultBLEConMonitoringFBD_Mik_30 "contains the BLE RSSI level (Range: -127 ... -1 dB / step: 0.5dB)";
CM_ SG_ 292 ResultBLEConMonitoringFBD_Mik_31 "the BLE connection event counter";
CM_ SG_ 292 ResultBLEConMonitoringFBD_Mik_32 "The RF channel number";
CM_ SG_ 292 ResultBLEConMonitoringFBD_Mik_33 "The RF channel quality";
CM_ SG_ 292 ResultBLEConMonitoringFBD_Mik_34 "contains the BLE RSSI level (Range: -127 ... -1 dB / step: 0.5dB)";
CM_ SG_ 292 ResultBLEConMonitoringFBD_Mik_35 "the BLE connection event counter";
CM_ SG_ 292 ResultBLEConMonitoringFBD_Mik_36 "The RF channel number";
CM_ SG_ 292 ResultBLEConMonitoringFBD_Mik_37 "The RF channel quality";
CM_ SG_ 292 ResultBLEConMonitoringFBD_Mik_38 "contains IV to signature";
CM_ SG_ 292 ResultBLEConMonitoringFBD_Mik_39 "contains IV to signature";
CM_ SG_ 292 ResultBLEConMonitoringFBD_Mik_40 "contains IV to signature";
CM_ SG_ 292 ResultBLEConMonitoringFBD_Mik_41 "contains IV to signature";
CM_ SG_ 292 ResultBLEConMonitoringFBD_Miko_S "contains signature";
CM_ SG_ 292 ResultBLEConMonitoringFBD_Mik_42 "contains signature";
CM_ SG_ 292 ResultBLEConMonitoringFBD_Mik_43 "contains signature";
CM_ SG_ 292 ResultBLEConMonitoringFBD_Mik_44 "contains signature";
CM_ SG_ 292 ResultBLEConMonitoringFBD_Mik_45 "contains signature";
CM_ SG_ 292 ResultBLEConMonitoringFBD_Mik_46 "contains signature";
CM_ SG_ 292 ResultBLEConMonitoringFBD_Mik_47 "contains signature";
CM_ SG_ 292 ResultBLEConMonitoringFBD_Mik_48 "contains signature";
CM_ SG_ 825 ResultBLEConMonitoringFBD_MM_IRK "contains ConnectionID";
CM_ SG_ 825 ResultBLEConMonitoringFBD_MM_RSS "contains the BLE RSSI level (Range: -127 ... -1 dB / step: 0.5dB)";
CM_ SG_ 825 ResultBLEConMonitoringFBD_MM_con "the BLE connection event counter";
CM_ SG_ 825 ResultBLEConMonitoringFBD_MM_Ch_ "The RF channel number";
CM_ SG_ 825 ResultBLEConMonitoringFBD_MM_Dev "The RF channel quality";
CM_ SG_ 825 ResultBLEConMonitoringFBD_MM_R_2 "contains the BLE RSSI level (Range: -127 ... -1 dB / step: 0.5dB)";
CM_ SG_ 825 ResultBLEConMonitoringFBD_MM_c_2 "the BLE connection event counter";
CM_ SG_ 825 ResultBLEConMonitoringFBD_MM_C_2 "The RF channel number";
CM_ SG_ 825 ResultBLEConMonitoringFBD_MM_C_3 "The RF channel quality";
CM_ SG_ 825 ResultBLEConMonitoringFBD_MM_R_3 "contains the BLE RSSI level (Range: -127 ... -1 dB / step: 0.5dB)";
CM_ SG_ 825 ResultBLEConMonitoringFBD_MM_c_3 "the BLE connection event counter";
CM_ SG_ 825 ResultBLEConMonitoringFBD_MM_C_4 "The RF channel number";
CM_ SG_ 825 ResultBLEConMonitoringFBD_MM_C_5 "The RF channel quality";
CM_ SG_ 825 ResultBLEConMonitoringFBD_MM_R_4 "contains the BLE RSSI level (Range: -127 ... -1 dB / step: 0.5dB)";
CM_ SG_ 825 ResultBLEConMonitoringFBD_MM_c_4 "the BLE connection event counter";
CM_ SG_ 825 ResultBLEConMonitoringFBD_MM_C_6 "The RF channel number";
CM_ SG_ 825 ResultBLEConMonitoringFBD_MM_C_7 "The RF channel quality";
CM_ SG_ 825 ResultBLEConMonitoringFBD_MM_R_5 "contains the BLE RSSI level (Range: -127 ... -1 dB / step: 0.5dB)";
CM_ SG_ 825 ResultBLEConMonitoringFBD_MM_c_5 "the BLE connection event counter";
CM_ SG_ 825 ResultBLEConMonitoringFBD_MM_C_8 "The RF channel number";
CM_ SG_ 825 ResultBLEConMonitoringFBD_MM_C_9 "The RF channel quality";
CM_ SG_ 825 ResultBLEConMonitoringFBD_MM_R_6 "contains the BLE RSSI level (Range: -127 ... -1 dB / step: 0.5dB)";
CM_ SG_ 825 ResultBLEConMonitoringFBD_MM_c_6 "the BLE connection event counter";
CM_ SG_ 825 ResultBLEConMonitoringFBD_MM__10 "The RF channel number";
CM_ SG_ 825 ResultBLEConMonitoringFBD_MM__11 "The RF channel quality";
CM_ SG_ 825 ResultBLEConMonitoringFBD_MM_R_7 "contains the BLE RSSI level (Range: -127 ... -1 dB / step: 0.5dB)";
CM_ SG_ 825 ResultBLEConMonitoringFBD_MM_c_7 "the BLE connection event counter";
CM_ SG_ 825 ResultBLEConMonitoringFBD_MM__12 "The RF channel number";
CM_ SG_ 825 ResultBLEConMonitoringFBD_MM__13 "The RF channel quality";
CM_ SG_ 825 ResultBLEConMonitoringFBD_MM_R_8 "contains the BLE RSSI level (Range: -127 ... -1 dB / step: 0.5dB)";
CM_ SG_ 825 ResultBLEConMonitoringFBD_MM_c_8 "the BLE connection event counter";
CM_ SG_ 825 ResultBLEConMonitoringFBD_MM__14 "The RF channel number";
CM_ SG_ 825 ResultBLEConMonitoringFBD_MM__15 "The RF channel quality";
CM_ SG_ 825 ResultBLEConMonitoringFBD_MM_R_9 "contains the BLE RSSI level (Range: -127 ... -1 dB / step: 0.5dB)";
CM_ SG_ 825 ResultBLEConMonitoringFBD_MM_c_9 "the BLE connection event counter";
CM_ SG_ 825 ResultBLEConMonitoringFBD_MM__16 "The RF channel number";
CM_ SG_ 825 ResultBLEConMonitoringFBD_MM__17 "The RF channel quality";
CM_ SG_ 825 ResultBLEConMonitoringFBD_MM__18 "contains the BLE RSSI level (Range: -127 ... -1 dB / step: 0.5dB)";
CM_ SG_ 825 ResultBLEConMonitoringFBD_MM__19 "the BLE connection event counter";
CM_ SG_ 825 ResultBLEConMonitoringFBD_MM__20 "The RF channel number";
CM_ SG_ 825 ResultBLEConMonitoringFBD_MM__21 "The RF channel quality";
CM_ SG_ 825 ResultBLEConMonitoringFBD_MM_IV0 "contains IV to signature";
CM_ SG_ 825 ResultBLEConMonitoringFBD_MM_I_2 "contains IV to signature";
CM_ SG_ 825 ResultBLEConMonitoringFBD_MM_I_3 "contains IV to signature";
CM_ SG_ 825 ResultBLEConMonitoringFBD_MM_I_4 "contains IV to signature";
CM_ SG_ 825 ResultBLEConMonitoringFBD_MM_Sig "contains signature";
CM_ SG_ 825 ResultBLEConMonitoringFBD_MM_S_2 "contains signature";
CM_ SG_ 825 ResultBLEConMonitoringFBD_MM_S_3 "contains signature";
CM_ SG_ 825 ResultBLEConMonitoringFBD_MM_S_4 "contains signature";
CM_ SG_ 825 ResultBLEConMonitoringFBD_MM_S_5 "contains signature";
CM_ SG_ 825 ResultBLEConMonitoringFBD_MM_S_6 "contains signature";
CM_ SG_ 825 ResultBLEConMonitoringFBD_MM_S_7 "contains signature";
CM_ SG_ 825 ResultBLEConMonitoringFBD_MM_S_8 "contains signature";
CM_ SG_ 293 ResultBLEConMonitoringFBD_Trunk_ "contains ConnectionID";
CM_ SG_ 293 ResultBLEConMonitoringFBD_Trun_2 "contains the BLE RSSI level (Range: -127 ... -1 dB / step: 0.5dB)";
CM_ SG_ 293 ResultBLEConMonitoringFBD_Trun_3 "the BLE connection event counter";
CM_ SG_ 293 ResultBLEConMonitoringFBD_Trun_4 "The RF channel number";
CM_ SG_ 293 ResultBLEConMonitoringFBD_Tunk_D "The RF channel quality";
CM_ SG_ 293 ResultBLEConMonitoringFBD_Trun_5 "contains the BLE RSSI level (Range: -127 ... -1 dB / step: 0.5dB)";
CM_ SG_ 293 ResultBLEConMonitoringFBD_Trun_6 "the BLE connection event counter";
CM_ SG_ 293 ResultBLEConMonitoringFBD_Trun_7 "The RF channel number";
CM_ SG_ 293 ResultBLEConMonitoringFBD_Trun_8 "The RF channel quality";
CM_ SG_ 293 ResultBLEConMonitoringFBD_Trun_9 "contains the BLE RSSI level (Range: -127 ... -1 dB / step: 0.5dB)";
CM_ SG_ 293 ResultBLEConMonitoringFBD_Tru_10 "the BLE connection event counter";
CM_ SG_ 293 ResultBLEConMonitoringFBD_Tru_11 "The RF channel number";
CM_ SG_ 293 ResultBLEConMonitoringFBD_Tru_12 "The RF channel quality";
CM_ SG_ 293 ResultBLEConMonitoringFBD_Tru_13 "contains the BLE RSSI level (Range: -127 ... -1 dB / step: 0.5dB)";
CM_ SG_ 293 ResultBLEConMonitoringFBD_Tru_14 "the BLE connection event counter";
CM_ SG_ 293 ResultBLEConMonitoringFBD_Tru_15 "The RF channel number";
CM_ SG_ 293 ResultBLEConMonitoringFBD_Tru_16 "The RF channel quality";
CM_ SG_ 293 ResultBLEConMonitoringFBD_Tru_17 "contains the BLE RSSI level (Range: -127 ... -1 dB / step: 0.5dB)";
CM_ SG_ 293 ResultBLEConMonitoringFBD_Tru_18 "the BLE connection event counter";
CM_ SG_ 293 ResultBLEConMonitoringFBD_Tru_19 "The RF channel number";
CM_ SG_ 293 ResultBLEConMonitoringFBD_Tru_20 "The RF channel quality";
CM_ SG_ 293 ResultBLEConMonitoringFBD_Tru_21 "contains the BLE RSSI level (Range: -127 ... -1 dB / step: 0.5dB)";
CM_ SG_ 293 ResultBLEConMonitoringFBD_Tru_22 "the BLE connection event counter";
CM_ SG_ 293 ResultBLEConMonitoringFBD_Tru_23 "The RF channel number";
CM_ SG_ 293 ResultBLEConMonitoringFBD_Tru_24 "The RF channel quality";
CM_ SG_ 293 ResultBLEConMonitoringFBD_Tru_25 "contains the BLE RSSI level (Range: -127 ... -1 dB / step: 0.5dB)";
CM_ SG_ 293 ResultBLEConMonitoringFBD_Tru_26 "the BLE connection event counter";
CM_ SG_ 293 ResultBLEConMonitoringFBD_Tru_27 "The RF channel number";
CM_ SG_ 293 ResultBLEConMonitoringFBD_Tru_28 "The RF channel quality";
CM_ SG_ 293 ResultBLEConMonitoringFBD_Tru_29 "contains the BLE RSSI level (Range: -127 ... -1 dB / step: 0.5dB)";
CM_ SG_ 293 ResultBLEConMonitoringFBD_Tru_30 "the BLE connection event counter";
CM_ SG_ 293 ResultBLEConMonitoringFBD_Tru_31 "The RF channel number";
CM_ SG_ 293 ResultBLEConMonitoringFBD_Tru_32 "The RF channel quality";
CM_ SG_ 293 ResultBLEConMonitoringFBD_Tru_33 "contains the BLE RSSI level (Range: -127 ... -1 dB / step: 0.5dB)";
CM_ SG_ 293 ResultBLEConMonitoringFBD_Tru_34 "the BLE connection event counter";
CM_ SG_ 293 ResultBLEConMonitoringFBD_Tru_35 "The RF channel number";
CM_ SG_ 293 ResultBLEConMonitoringFBD_Tru_36 "The RF channel quality";
CM_ SG_ 293 ResultBLEConMonitoringFBD_Tru_37 "contains the BLE RSSI level (Range: -127 ... -1 dB / step: 0.5dB)";
CM_ SG_ 293 ResultBLEConMonitoringFBD_Tru_38 "the BLE connection event counter";
CM_ SG_ 293 ResultBLEConMonitoringFBD_Tru_39 "The RF channel number";
CM_ SG_ 293 ResultBLEConMonitoringFBD_Tru_40 "The RF channel quality";
CM_ SG_ 293 ResultBLEConMonitoringFBD_Tru_41 "contains IV to signature";
CM_ SG_ 293 ResultBLEConMonitoringFBD_Tru_42 "contains IV to signature";
CM_ SG_ 293 ResultBLEConMonitoringFBD_Tru_43 "contains IV to signature";
CM_ SG_ 293 ResultBLEConMonitoringFBD_Tru_44 "contains IV to signature";
CM_ SG_ 293 ResultBLEConMonitoringFBD_Tru_45 "contains signature";
CM_ SG_ 293 ResultBLEConMonitoringFBD_Tru_46 "contains signature";
CM_ SG_ 293 ResultBLEConMonitoringFBD_Tru_47 "contains signature";
CM_ SG_ 293 ResultBLEConMonitoringFBD_Tru_48 "contains signature";
CM_ SG_ 293 ResultBLEConMonitoringFBD_Tru_49 "contains signature";
CM_ SG_ 293 ResultBLEConMonitoringFBD_Tru_50 "contains signature";
CM_ SG_ 293 ResultBLEConMonitoringFBD_Tru_51 "contains signature";
CM_ SG_ 293 ResultBLEConMonitoringFBD_Tru_52 "contains signature";
CM_ SG_ 294 ResultBLEConMonitoringFBD_VL_IRK "contains ConnectionID";
CM_ SG_ 294 ResultBLEConMonitoringFBD_VL_RSS "contains the BLE RSSI level (Range: -127 ... -1 dB / step: 0.5dB)";
CM_ SG_ 294 ResultBLEConMonitoringFBD_VL_con "the BLE connection event counter";
CM_ SG_ 294 ResultBLEConMonitoringFBD_VL_Ch_ "The RF channel number";
CM_ SG_ 294 ResultBLEConMonitoringFBD_VL_Dev "The RF channel quality";
CM_ SG_ 294 ResultBLEConMonitoringFBD_VL_R_2 "contains the BLE RSSI level (Range: -127 ... -1 dB / step: 0.5dB)";
CM_ SG_ 294 ResultBLEConMonitoringFBD_VL_c_2 "the BLE connection event counter";
CM_ SG_ 294 ResultBLEConMonitoringFBD_VL_C_2 "The RF channel number";
CM_ SG_ 294 ResultBLEConMonitoringFBD_VL_C_3 "The RF channel quality";
CM_ SG_ 294 ResultBLEConMonitoringFBD_VL_R_3 "contains the BLE RSSI level (Range: -127 ... -1 dB / step: 0.5dB)";
CM_ SG_ 294 ResultBLEConMonitoringFBD_VL_c_3 "the BLE connection event counter";
CM_ SG_ 294 ResultBLEConMonitoringFBD_VL_C_4 "The RF channel number";
CM_ SG_ 294 ResultBLEConMonitoringFBD_VL_C_5 "The RF channel quality";
CM_ SG_ 294 ResultBLEConMonitoringFBD_VL_R_4 "contains the BLE RSSI level (Range: -127 ... -1 dB / step: 0.5dB)";
CM_ SG_ 294 ResultBLEConMonitoringFBD_VL_c_4 "the BLE connection event counter";
CM_ SG_ 294 ResultBLEConMonitoringFBD_VL_C_6 "The RF channel number";
CM_ SG_ 294 ResultBLEConMonitoringFBD_VL_C_7 "The RF channel quality";
CM_ SG_ 294 ResultBLEConMonitoringFBD_VL_R_5 "contains the BLE RSSI level (Range: -127 ... -1 dB / step: 0.5dB)";
CM_ SG_ 294 ResultBLEConMonitoringFBD_VL_c_5 "the BLE connection event counter";
CM_ SG_ 294 ResultBLEConMonitoringFBD_VL_C_8 "The RF channel number";
CM_ SG_ 294 ResultBLEConMonitoringFBD_VL_C_9 "The RF channel quality";
CM_ SG_ 294 ResultBLEConMonitoringFBD_VL_R_6 "contains the BLE RSSI level (Range: -127 ... -1 dB / step: 0.5dB)";
CM_ SG_ 294 ResultBLEConMonitoringFBD_VL_c_6 "the BLE connection event counter";
CM_ SG_ 294 ResultBLEConMonitoringFBD_VL__10 "The RF channel number";
CM_ SG_ 294 ResultBLEConMonitoringFBD_VL__11 "The RF channel quality";
CM_ SG_ 294 ResultBLEConMonitoringFBD_VL_R_7 "contains the BLE RSSI level (Range: -127 ... -1 dB / step: 0.5dB)";
CM_ SG_ 294 ResultBLEConMonitoringFBD_VL_c_7 "the BLE connection event counter";
CM_ SG_ 294 ResultBLEConMonitoringFBD_VL__12 "The RF channel number";
CM_ SG_ 294 ResultBLEConMonitoringFBD_VL__13 "The RF channel quality";
CM_ SG_ 294 ResultBLEConMonitoringFBD_VL_R_8 "contains the BLE RSSI level (Range: -127 ... -1 dB / step: 0.5dB)";
CM_ SG_ 294 ResultBLEConMonitoringFBD_VL_c_8 "the BLE connection event counter";
CM_ SG_ 294 ResultBLEConMonitoringFBD_VL__14 "The RF channel number";
CM_ SG_ 294 ResultBLEConMonitoringFBD_VL__15 "The RF channel quality";
CM_ SG_ 294 ResultBLEConMonitoringFBD_VL_R_9 "contains the BLE RSSI level (Range: -127 ... -1 dB / step: 0.5dB)";
CM_ SG_ 294 ResultBLEConMonitoringFBD_VL_c_9 "the BLE connection event counter";
CM_ SG_ 294 ResultBLEConMonitoringFBD_VL__16 "The RF channel number";
CM_ SG_ 294 ResultBLEConMonitoringFBD_VL__17 "The RF channel quality";
CM_ SG_ 294 ResultBLEConMonitoringFBD_VL__18 "contains the BLE RSSI level (Range: -127 ... -1 dB / step: 0.5dB)";
CM_ SG_ 294 ResultBLEConMonitoringFBD_VL__19 "the BLE connection event counter";
CM_ SG_ 294 ResultBLEConMonitoringFBD_VL__20 "The RF channel number";
CM_ SG_ 294 ResultBLEConMonitoringFBD_VL__21 "The RF channel quality";
CM_ SG_ 294 ResultBLEConMonitoringFBD_VL_IV0 "contains IV to signature";
CM_ SG_ 294 ResultBLEConMonitoringFBD_VL_I_2 "contains IV to signature";
CM_ SG_ 294 ResultBLEConMonitoringFBD_VL_I_3 "contains IV to signature";
CM_ SG_ 294 ResultBLEConMonitoringFBD_VL_I_4 "contains IV to signature";
CM_ SG_ 294 ResultBLEConMonitoringFBD_VL_Sig "contains signature";
CM_ SG_ 294 ResultBLEConMonitoringFBD_VL_S_2 "contains signature";
CM_ SG_ 294 ResultBLEConMonitoringFBD_VL_S_3 "contains signature";
CM_ SG_ 294 ResultBLEConMonitoringFBD_VL_S_4 "contains signature";
CM_ SG_ 294 ResultBLEConMonitoringFBD_VL_S_5 "contains signature";
CM_ SG_ 294 ResultBLEConMonitoringFBD_VL_S_6 "contains signature";
CM_ SG_ 294 ResultBLEConMonitoringFBD_VL_S_7 "contains signature";
CM_ SG_ 294 ResultBLEConMonitoringFBD_VL_S_8 "contains signature";
CM_ SG_ 290 ResultBLEConMonitoringFBD_VM_IRK "contains ConnectionID";
CM_ SG_ 290 ResultBLEConMonitoringFBD_VM_RSS "contains the BLE RSSI level (Range: -127 ... -1 dB / step: 0.5dB)";
CM_ SG_ 290 ResultBLEConMonitoringFBD_VM_con "the BLE connection event counter";
CM_ SG_ 290 ResultBLEConMonitoringFBD_VM_Ch_ "The RF channel number";
CM_ SG_ 290 ResultBLEConMonitoringFBD_VM_Dev "The RF channel quality";
CM_ SG_ 290 ResultBLEConMonitoringFBD_VM_R_2 "contains the BLE RSSI level (Range: -127 ... -1 dB / step: 0.5dB)";
CM_ SG_ 290 ResultBLEConMonitoringFBD_VM_c_2 "the BLE connection event counter";
CM_ SG_ 290 ResultBLEConMonitoringFBD_VM_C_2 "The RF channel number";
CM_ SG_ 290 ResultBLEConMonitoringFBD_VM_C_3 "The RF channel quality";
CM_ SG_ 290 ResultBLEConMonitoringFBD_VM_R_3 "contains the BLE RSSI level (Range: -127 ... -1 dB / step: 0.5dB)";
CM_ SG_ 290 ResultBLEConMonitoringFBD_VM_c_3 "the BLE connection event counter";
CM_ SG_ 290 ResultBLEConMonitoringFBD_VM_C_4 "The RF channel number";
CM_ SG_ 290 ResultBLEConMonitoringFBD_VM_C_5 "The RF channel quality";
CM_ SG_ 290 ResultBLEConMonitoringFBD_VM_R_4 "contains the BLE RSSI level (Range: -127 ... -1 dB / step: 0.5dB)";
CM_ SG_ 290 ResultBLEConMonitoringFBD_VM_c_4 "the BLE connection event counter";
CM_ SG_ 290 ResultBLEConMonitoringFBD_VM_C_6 "The RF channel number";
CM_ SG_ 290 ResultBLEConMonitoringFBD_VM_C_7 "The RF channel quality";
CM_ SG_ 290 ResultBLEConMonitoringFBD_VM_R_5 "contains the BLE RSSI level (Range: -127 ... -1 dB / step: 0.5dB)";
CM_ SG_ 290 ResultBLEConMonitoringFBD_VM_c_5 "the BLE connection event counter";
CM_ SG_ 290 ResultBLEConMonitoringFBD_VM_C_8 "The RF channel number";
CM_ SG_ 290 ResultBLEConMonitoringFBD_VM_C_9 "The RF channel quality";
CM_ SG_ 290 ResultBLEConMonitoringFBD_VM_R_6 "contains the BLE RSSI level (Range: -127 ... -1 dB / step: 0.5dB)";
CM_ SG_ 290 ResultBLEConMonitoringFBD_VM_c_6 "the BLE connection event counter";
CM_ SG_ 290 ResultBLEConMonitoringFBD_VM__10 "The RF channel number";
CM_ SG_ 290 ResultBLEConMonitoringFBD_VM__11 "The RF channel quality";
CM_ SG_ 290 ResultBLEConMonitoringFBD_VM_R_7 "contains the BLE RSSI level (Range: -127 ... -1 dB / step: 0.5dB)";
CM_ SG_ 290 ResultBLEConMonitoringFBD_VM_c_7 "the BLE connection event counter";
CM_ SG_ 290 ResultBLEConMonitoringFBD_VM__12 "The RF channel number";
CM_ SG_ 290 ResultBLEConMonitoringFBD_VM__13 "The RF channel quality";
CM_ SG_ 290 ResultBLEConMonitoringFBD_VM_R_8 "contains the BLE RSSI level (Range: -127 ... -1 dB / step: 0.5dB)";
CM_ SG_ 290 ResultBLEConMonitoringFBD_VM_c_8 "the BLE connection event counter";
CM_ SG_ 290 ResultBLEConMonitoringFBD_VM__14 "The RF channel number";
CM_ SG_ 290 ResultBLEConMonitoringFBD_VM__15 "The RF channel quality";
CM_ SG_ 290 ResultBLEConMonitoringFBD_VM_R_9 "contains the BLE RSSI level (Range: -127 ... -1 dB / step: 0.5dB)";
CM_ SG_ 290 ResultBLEConMonitoringFBD_VM_c_9 "the BLE connection event counter";
CM_ SG_ 290 ResultBLEConMonitoringFBD_VM__16 "The RF channel number";
CM_ SG_ 290 ResultBLEConMonitoringFBD_VM__17 "The RF channel quality";
CM_ SG_ 290 ResultBLEConMonitoringFBD_VM__18 "contains the BLE RSSI level (Range: -127 ... -1 dB / step: 0.5dB)";
CM_ SG_ 290 ResultBLEConMonitoringFBD_VM__19 "the BLE connection event counter";
CM_ SG_ 290 ResultBLEConMonitoringFBD_VM__20 "The RF channel number";
CM_ SG_ 290 ResultBLEConMonitoringFBD_VM__21 "The RF channel quality";
CM_ SG_ 290 ResultBLEConMonitoringFBD_VM_IV0 "contains IV to signature";
CM_ SG_ 290 ResultBLEConMonitoringFBD_VM_I_2 "contains IV to signature";
CM_ SG_ 290 ResultBLEConMonitoringFBD_VM_I_3 "contains IV to signature";
CM_ SG_ 290 ResultBLEConMonitoringFBD_VM_I_4 "contains IV to signature";
CM_ SG_ 290 ResultBLEConMonitoringFBD_VM_Sig "contains signature";
CM_ SG_ 290 ResultBLEConMonitoringFBD_VM_S_2 "contains signature";
CM_ SG_ 290 ResultBLEConMonitoringFBD_VM_S_3 "contains signature";
CM_ SG_ 290 ResultBLEConMonitoringFBD_VM_S_4 "contains signature";
CM_ SG_ 290 ResultBLEConMonitoringFBD_VM_S_5 "contains signature";
CM_ SG_ 290 ResultBLEConMonitoringFBD_VM_S_6 "contains signature";
CM_ SG_ 290 ResultBLEConMonitoringFBD_VM_S_7 "contains signature";
CM_ SG_ 290 ResultBLEConMonitoringFBD_VM_S_8 "contains signature";
CM_ SG_ 295 ResultBLEConMonitoringFBD_VR_IRK "contains ConnectionID";
CM_ SG_ 295 ResultBLEConMonitoringFBD_VR_RSS "contains the BLE RSSI level (Range: -127 ... -1 dB / step: 0.5dB)";
CM_ SG_ 295 ResultBLEConMonitoringFBD_VR_con "the BLE connection event counter";
CM_ SG_ 295 ResultBLEConMonitoringFBD_VR_Ch_ "The RF channel number";
CM_ SG_ 295 ResultBLEConMonitoringFBD_VR_Dev "The RF channel quality";
CM_ SG_ 295 ResultBLEConMonitoringFBD_VR_R_2 "contains the BLE RSSI level (Range: -127 ... -1 dB / step: 0.5dB)";
CM_ SG_ 295 ResultBLEConMonitoringFBD_VR_c_2 "the BLE connection event counter";
CM_ SG_ 295 ResultBLEConMonitoringFBD_VR_C_2 "The RF channel number";
CM_ SG_ 295 ResultBLEConMonitoringFBD_VR_C_3 "The RF channel quality";
CM_ SG_ 295 ResultBLEConMonitoringFBD_VR_R_3 "contains the BLE RSSI level (Range: -127 ... -1 dB / step: 0.5dB)";
CM_ SG_ 295 ResultBLEConMonitoringFBD_VR_c_3 "the BLE connection event counter";
CM_ SG_ 295 ResultBLEConMonitoringFBD_VR_C_4 "The RF channel number";
CM_ SG_ 295 ResultBLEConMonitoringFBD_VR_C_5 "The RF channel quality";
CM_ SG_ 295 ResultBLEConMonitoringFBD_VR_R_4 "contains the BLE RSSI level (Range: -127 ... -1 dB / step: 0.5dB)";
CM_ SG_ 295 ResultBLEConMonitoringFBD_VR_c_4 "the BLE connection event counter";
CM_ SG_ 295 ResultBLEConMonitoringFBD_VR_C_6 "The RF channel number";
CM_ SG_ 295 ResultBLEConMonitoringFBD_VR_C_7 "The RF channel quality";
CM_ SG_ 295 ResultBLEConMonitoringFBD_VR_R_5 "contains the BLE RSSI level (Range: -127 ... -1 dB / step: 0.5dB)";
CM_ SG_ 295 ResultBLEConMonitoringFBD_VR_c_5 "the BLE connection event counter";
CM_ SG_ 295 ResultBLEConMonitoringFBD_VR_C_8 "The RF channel number";
CM_ SG_ 295 ResultBLEConMonitoringFBD_VR_C_9 "The RF channel quality";
CM_ SG_ 295 ResultBLEConMonitoringFBD_VR_R_6 "contains the BLE RSSI level (Range: -127 ... -1 dB / step: 0.5dB)";
CM_ SG_ 295 ResultBLEConMonitoringFBD_VR_c_6 "the BLE connection event counter";
CM_ SG_ 295 ResultBLEConMonitoringFBD_VR__10 "The RF channel number";
CM_ SG_ 295 ResultBLEConMonitoringFBD_VR__11 "The RF channel quality";
CM_ SG_ 295 ResultBLEConMonitoringFBD_VR_R_7 "contains the BLE RSSI level (Range: -127 ... -1 dB / step: 0.5dB)";
CM_ SG_ 295 ResultBLEConMonitoringFBD_VR_c_7 "the BLE connection event counter";
CM_ SG_ 295 ResultBLEConMonitoringFBD_VR__12 "The RF channel number";
CM_ SG_ 295 ResultBLEConMonitoringFBD_VR__13 "The RF channel quality";
CM_ SG_ 295 ResultBLEConMonitoringFBD_VR_R_8 "contains the BLE RSSI level (Range: -127 ... -1 dB / step: 0.5dB)";
CM_ SG_ 295 ResultBLEConMonitoringFBD_VR_c_8 "the BLE connection event counter";
CM_ SG_ 295 ResultBLEConMonitoringFBD_VR__14 "The RF channel number";
CM_ SG_ 295 ResultBLEConMonitoringFBD_VR__15 "The RF channel quality";
CM_ SG_ 295 ResultBLEConMonitoringFBD_VR_R_9 "contains the BLE RSSI level (Range: -127 ... -1 dB / step: 0.5dB)";
CM_ SG_ 295 ResultBLEConMonitoringFBD_VR_c_9 "the BLE connection event counter";
CM_ SG_ 295 ResultBLEConMonitoringFBD_VR__16 "The RF channel number";
CM_ SG_ 295 ResultBLEConMonitoringFBD_VR__17 "The RF channel quality";
CM_ SG_ 295 ResultBLEConMonitoringFBD_VR__18 "contains the BLE RSSI level (Range: -127 ... -1 dB / step: 0.5dB)";
CM_ SG_ 295 ResultBLEConMonitoringFBD_VR__19 "the BLE connection event counter";
CM_ SG_ 295 ResultBLEConMonitoringFBD_VR__20 "The RF channel number";
CM_ SG_ 295 ResultBLEConMonitoringFBD_VR__21 "The RF channel quality";
CM_ SG_ 295 ResultBLEConMonitoringFBD_VR_IV0 "contains IV to signature";
CM_ SG_ 295 ResultBLEConMonitoringFBD_VR_I_2 "contains IV to signature";
CM_ SG_ 295 ResultBLEConMonitoringFBD_VR_I_3 "contains IV to signature";
CM_ SG_ 295 ResultBLEConMonitoringFBD_VR_I_4 "contains IV to signature";
CM_ SG_ 295 ResultBLEConMonitoringFBD_VR_Sig "contains signature";
CM_ SG_ 295 ResultBLEConMonitoringFBD_VR_S_2 "contains signature";
CM_ SG_ 295 ResultBLEConMonitoringFBD_VR_S_3 "contains signature";
CM_ SG_ 295 ResultBLEConMonitoringFBD_VR_S_4 "contains signature";
CM_ SG_ 295 ResultBLEConMonitoringFBD_VR_S_5 "contains signature";
CM_ SG_ 295 ResultBLEConMonitoringFBD_VR_S_6 "contains signature";
CM_ SG_ 295 ResultBLEConMonitoringFBD_VR_S_7 "contains signature";
CM_ SG_ 295 ResultBLEConMonitoringFBD_VR_S_8 "contains signature";
CM_ SG_ 576 ResultBLERSSIRangingIntentFBD_HL "addressing of the UWB anchors";
CM_ SG_ 576 ResultBLERSSIRangingIntentFBD__2 "contains IRK List ID";
CM_ SG_ 576 ResultBLERSSIRangingIntentFBD__3 "contains status to motion detection";
CM_ SG_ 576 ResultBLERSSIRangingIntentFBD__4 "containes decision confidence";
CM_ SG_ 571 ResultBLERSSIRangingIntentFBD_HM "addressing of the UWB anchors";
CM_ SG_ 571 ResultBLERSSIRangingIntentFBD__2 "contains IRK List ID";
CM_ SG_ 571 ResultBLERSSIRangingIntentFBD__3 "contains status to motion detection";
CM_ SG_ 571 ResultBLERSSIRangingIntentFBD__4 "containes decision confidence";
CM_ SG_ 577 ResultBLERSSIRangingIntentFBD_HR "addressing of the UWB anchors";
CM_ SG_ 577 ResultBLERSSIRangingIntentFBD__2 "contains IRK List ID";
CM_ SG_ 577 ResultBLERSSIRangingIntentFBD__3 "contains status to motion detection";
CM_ SG_ 577 ResultBLERSSIRangingIntentFBD__4 "containes decision confidence";
CM_ SG_ 572 ResultBLERSSIRangingIntentFBD_Mi "addressing of the UWB anchors";
CM_ SG_ 572 ResultBLERSSIRangingIntentFBD__2 "contains IRK List ID";
CM_ SG_ 572 ResultBLERSSIRangingIntentFBD__3 "contains status to motion detection";
CM_ SG_ 572 ResultBLERSSIRangingIntentFBD__4 "containes decision confidence";
CM_ SG_ 541 ResultBLERSSIRangingIntentFBD_MM "addressing of the UWB anchors";
CM_ SG_ 541 ResultBLERSSIRangingIntentFBD__2 "contains IRK List ID";
CM_ SG_ 541 ResultBLERSSIRangingIntentFBD__3 "contains status to motion detection";
CM_ SG_ 541 ResultBLERSSIRangingIntentFBD__4 "containes decision confidence";
CM_ SG_ 578 ResultBLERSSIRangingIntentFBD_SM "addressing of the UWB anchors";
CM_ SG_ 578 ResultBLERSSIRangingIntentFBD__2 "contains IRK List ID";
CM_ SG_ 578 ResultBLERSSIRangingIntentFBD__3 "contains status to motion detection";
CM_ SG_ 579 ResultBLERSSIRangingIntentFBD_SM "addressing of the UWB anchors";
CM_ SG_ 579 ResultBLERSSIRangingIntentFBD__2 "contains IRK List ID";
CM_ SG_ 579 ResultBLERSSIRangingIntentFBD__3 "contains status to motion detection";
CM_ SG_ 573 ResultBLERSSIRangingIntentFBD_Tr "addressing of the UWB anchors";
CM_ SG_ 573 ResultBLERSSIRangingIntentFBD__2 "contains IRK List ID";
CM_ SG_ 573 ResultBLERSSIRangingIntentFBD__3 "contains status to motion detection";
CM_ SG_ 573 ResultBLERSSIRangingIntentFBD__4 "containes decision confidence";

BA_DEF_ BO_ "VFrameFormat" ENUM "StandardCAN","ExtendedCAN","reserved","J1939PG","reserved","reserved","reserved","reserved","reserved","reserved","reserved","reserved","reserved","reserved","StandardCAN_FD","ExtendedCAN_FD";
BA_DEF_DEF_ "VFrameFormat" "StandardCAN";
BA_ "VFrameFormat" BO_ 552 14;
BA_ "VFrameFormat" BO_ 560 14;
BA_ "VFrameFormat" BO_ 553 14;
BA_ "VFrameFormat" BO_ 554 14;
BA_ "VFrameFormat" BO_ 550 14;
BA_ "VFrameFormat" BO_ 555 14;
BA_ "VFrameFormat" BO_ 406 14;
BA_ "VFrameFormat" BO_ 999 14;
BA_ "VFrameFormat" BO_ 998 14;
BA_ "VFrameFormat" BO_ 384 14;
BA_ "VFrameFormat" BO_ 405 14;
BA_ "VFrameFormat" BO_ 296 14;
BA_ "VFrameFormat" BO_ 291 14;
BA_ "VFrameFormat" BO_ 297 14;
BA_ "VFrameFormat" BO_ 292 14;
BA_ "VFrameFormat" BO_ 825 14;
BA_ "VFrameFormat" BO_ 293 14;
BA_ "VFrameFormat" BO_ 294 14;
BA_ "VFrameFormat" BO_ 290 14;
BA_ "VFrameFormat" BO_ 295 14;
